VERSION ""

NS_ :

BS_:

BU_: ECS Dummy CGW MFC SPAS ESC BSD SCC SAS MDPS HUD CLU

BO_ 3221225472 VECTOR__INDEPENDENT_SIG_MSG: 0 Vector__XXX
 SG_ SNI_MDPS : 0|8@1+ (1,0) [0|0] "" Vector__XXX
 SG_ SNI_ECS : 0|8@1+ (1,0) [0|0] "" Vector__XXX
 SG_ CBV_RMR_MDPS : 0|1@1+ (1,0) [0|0] "" Vector__XXX
 SG_ CBV_RMR_ECS : 0|1@1+ (1,0) [0|0] "" Vector__XXX
 SG_ CBV_PNIB_MDPS : 0|1@1+ (1,0) [0|0] "" Vector__XXX
 SG_ CBV_PNIB_ECS : 0|1@1+ (1,0) [0|0] "" Vector__XXX
 SG_ CBV_NMCoSRB_MDPS : 0|1@1+ (1,0) [0|0] "" Vector__XXX
 SG_ CBV_NMCoSRB_ECS : 0|1@1+ (1,0) [0|0] "" Vector__XXX
 SG_ CBV_NMCoID_MDPS : 0|2@1+ (1,0) [0|0] "" Vector__XXX
 SG_ CBV_NMCoID_ECS : 0|2@1+ (1,0) [0|0] "" Vector__XXX
 SG_ CBV_AWB_MDPS : 0|1@1+ (1,0) [0|0] "" Vector__XXX
 SG_ CBV_AWB_ECS : 0|1@1+ (1,0) [0|0] "" Vector__XXX
 SG_ PNI_MDPS : 0|32@1+ (1,0) [0|0] "" Vector__XXX
 SG_ PNI_ECS : 0|32@1+ (1,0) [0|0] "" Vector__XXX
 SG_ NM_State_MDPS : 0|8@1+ (1,0) [0|0] "" Vector__XXX
 SG_ NM_State_ECS : 0|8@1+ (1,0) [0|0] "" Vector__XXX
 SG_ BSD_Crc1Val : 0|12@1+ (1,0) [0|0] "" Vector__XXX
 SG_ BSD_AlvCnt1Val : 0|4@1+ (1,0) [0|0] "" Vector__XXX
 SG_ BSD_Sta : 0|4@1+ (1,0) [0|0] "" Vector__XXX
 SG_ BSD_SndWarngSta : 0|2@1- (1,0) [0|0] "" Vector__XXX
 SG_ BSD_LftIndSta : 0|2@1+ (1,0) [0|0] "" Vector__XXX
 SG_ BSD_RtIndSta : 0|2@1+ (1,0) [0|0] "" Vector__XXX
 SG_ BSD_LftSndWrngSta : 0|2@1+ (1,0) [0|0] "" Vector__XXX
 SG_ BSD_RtSndWrngSta : 0|2@1+ (1,0) [0|0] "" Vector__XXX
 SG_ BSD_LftIndBriLvlSta : 0|8@1+ (1,0) [0|0] "" Vector__XXX
 SG_ BSD_RtIndBriLvlSta : 0|8@1+ (1,0) [0|0] "" Vector__XXX
 SG_ RCTA_Sta : 0|4@1+ (1,0) [0|0] "" Vector__XXX
 SG_ RCTA_LftIndSta : 0|2@1+ (1,0) [0|0] "" Vector__XXX
 SG_ RCTA_RtIndSta : 0|2@1+ (1,0) [0|0] "" Vector__XXX
 SG_ RCTA_LftSndWrngSta : 0|2@1+ (1,0) [0|0] "" Vector__XXX
 SG_ RCTA_RtSndWrngSta : 0|2@1+ (1,0) [0|0] "" Vector__XXX
 SG_ RCTA_LftWrngIndBriLvlSta : 0|8@1+ (1,0) [0|0] "" Vector__XXX
 SG_ RCTA_RtWrngIndBriLvlSta : 0|8@1+ (1,0) [0|0] "" Vector__XXX
 SG_ ABSD_Sta : 0|3@1+ (1,0) [0|0] "" Vector__XXX
 SG_ ABSD_WrngSta : 0|2@1+ (1,0) [0|0] "" Vector__XXX
 SG_ ABSD_FLBrkCtrlReq : 0|2@1+ (1,0) [0|0] "" Vector__XXX
 SG_ ABSD_FRBrkCtrlReq : 0|2@1+ (1,0) [0|0] "" Vector__XXX
 SG_ ABSD_RLBrkCtrlReq : 0|2@1+ (1,0) [0|0] "" Vector__XXX
 SG_ ABSD_RRBrkCtrlReq : 0|2@1+ (1,0) [0|0] "" Vector__XXX
 SG_ ABSD_FrWhlTrgtBrkPrsrVal : 0|6@1+ (1,0) [0|0] "Bar" Vector__XXX
 SG_ ABSD_RrWhlTrgtBrkPrsrVal : 0|6@1+ (1,0) [0|0] "Bar" Vector__XXX

BO_ 1892 CGW_SIG_GW_TOM_IF_03_B: 8 CGW
 SG_ SIG_GW_03_B_Sig2 : 32|32@1+ (1,0) [0|4294967295] ""  Dummy
 SG_ SIG_GW_03_B_Sig1 : 0|32@1+ (1,0) [0|4294967295] ""  Dummy

BO_ 1891 CGW_SIG_GW_Msg_IF_02_C: 8 CGW
 SG_ SIG_GW_02_C_Sig2 : 32|32@1+ (1,0) [0|4294967295] ""  Dummy
 SG_ SIG_GW_02_C_Sig1 : 0|32@1+ (1,0) [0|4294967295] ""  Dummy

BO_ 1890 CGW_SIG_GW_Msg_IF_02_B: 8 CGW
 SG_ SIG_GW_02_B_Sig2 : 32|32@1+ (1,0) [0|4294967295] ""  Dummy
 SG_ SIG_GW_02_B_Sig1 : 0|32@1+ (1,0) [0|4294967295] ""  Dummy

BO_ 1889 CGW_SIG_GW_Msg_IF_01_B: 8 CGW
 SG_ SIG_GW_01_B_Sig2 : 32|32@1+ (1,0) [0|4294967295] ""  Dummy
 SG_ SIG_GW_01_B_Sig1 : 0|32@1+ (1,0) [0|4294967295] ""  Dummy

BO_ 1888 Diag_Msg_TP_Phys_Res_FD_CAN1: 8 CGW
 SG_ TP_Phys_DiagRes_DATA_FD_CAN1 : 0|64@1+ (1,0) [0|0] ""  Dummy

BO_ 1896 Diag_Msg_TP_Phys_Req_FD_CAN1: 8 Dummy
 SG_ TP_Phys_DiagReq_DATA_FD_CAN1 : 0|64@1+ (1,0) [0|0] ""  CGW

BO_ 2015 Diag_Msg_TP_Func_FD_CAN1: 8 Dummy
 SG_ TP_Func_DiagReq_DATA_FD_CAN1 : 0|64@1+ (1,0) [0|0] ""  CGW

BO_ 263 V_CGW_07_B: 8 CGW
 SG_ V_CGW_07_B_SIG : 0|32@1+ (1,0) [0|0] ""  Dummy

BO_ 262 V_CGW_06_A: 8 Dummy
 SG_ V_CGW_06_A_SIG : 0|64@1+ (1,0) [0|0] ""  CGW

BO_ 290 V_CGW_05_C: 8 CGW
 SG_ V_CGW_05_C_SIG : 0|8@1- (1,0) [0|0] ""  Dummy

BO_ 517 V_CGW_02_A: 8 Dummy
 SG_ V_CGW_02_A_SIG : 0|64@1+ (1,0) [0|0] ""  CGW

BO_ 514 V_CGW_01_B: 8 CGW
 SG_ V_CGW_01_B_SigGrp_2 : 8|4@1+ (1,0) [0|15] ""  Dummy
 SG_ V_CGW_01_B_SigGrp_1 : 0|8@1+ (1,0) [0|244] ""  Dummy

BO_ 1761 XCP_Response: 20 CGW
 SG_ XCP_RESPONSE_DATA : 0|64@1+ (1,0) [0|1.84467440737096E+019] ""  SCC

BO_ 1762 XCP_Request: 20 SCC
 SG_ XCP_REQUEST_DATA : 0|64@1+ (1,0) [0|1.84467440737096E+019] ""  CGW

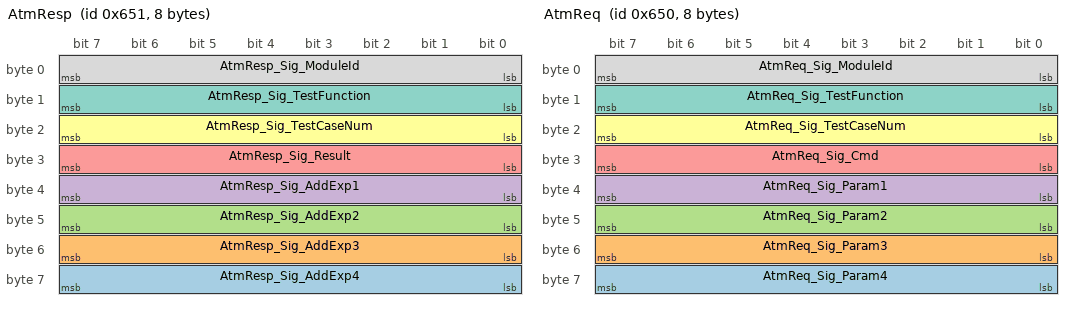
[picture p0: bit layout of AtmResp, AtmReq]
BO_ 1617 AtmResp: 8 CGW
 SG_ AtmResp_Sig_AddExp4 : 56|8@1+ (1,0) [0|0] ""  Dummy
 SG_ AtmResp_Sig_AddExp3 : 48|8@1+ (1,0) [0|0] ""  Dummy
 SG_ AtmResp_Sig_AddExp2 : 40|8@1+ (1,0) [0|0] ""  Dummy
 SG_ AtmResp_Sig_AddExp1 : 32|8@1+ (1,0) [0|0] ""  Dummy
 SG_ AtmResp_Sig_Result : 24|8@1+ (1,0) [0|0] ""  Dummy
 SG_ AtmResp_Sig_TestCaseNum : 16|8@1+ (1,0) [0|0] ""  Dummy
 SG_ AtmResp_Sig_TestFunction : 8|8@1+ (1,0) [0|0] ""  Dummy
 SG_ AtmResp_Sig_ModuleId : 0|8@1+ (1,0) [0|0] ""  Dummy

BO_ 1616 AtmReq: 8 Dummy
 SG_ AtmReq_Sig_Param4 : 56|8@1+ (1,0) [0|0] ""  CGW
 SG_ AtmReq_Sig_Param3 : 48|8@1+ (1,0) [0|0] ""  CGW
 SG_ AtmReq_Sig_Param2 : 40|8@1+ (1,0) [0|0] ""  CGW
 SG_ AtmReq_Sig_Param1 : 32|8@1+ (1,0) [0|0] ""  CGW
 SG_ AtmReq_Sig_Cmd : 24|8@1+ (1,0) [0|0] ""  CGW
 SG_ AtmReq_Sig_TestCaseNum : 16|8@1+ (1,0) [0|0] ""  CGW
 SG_ AtmReq_Sig_TestFunction : 8|8@1+ (1,0) [0|0] ""  CGW
 SG_ AtmReq_Sig_ModuleId : 0|8@1+ (1,0) [0|0] ""  CGW

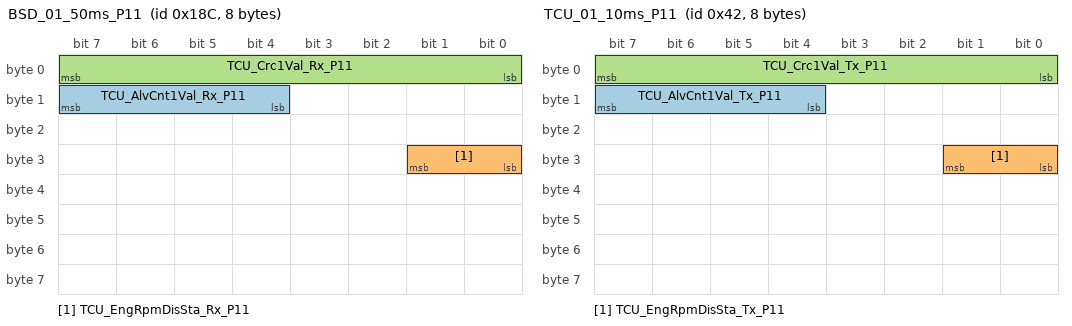
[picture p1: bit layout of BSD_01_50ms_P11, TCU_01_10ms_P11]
BO_ 396 BSD_01_50ms_P11: 8 CLU
 SG_ TCU_AlvCnt1Val_Rx_P11 : 12|4@1+ (1,0) [0|15] ""  CGW
 SG_ TCU_EngRpmDisSta_Rx_P11 : 24|2@1+ (1,0) [0|3] ""  CGW
 SG_ TCU_Crc1Val_Rx_P11 : 0|8@1+ (1,0) [0|255] ""  CGW

BO_ 66 TCU_01_10ms_P11: 8 CGW
 SG_ TCU_AlvCnt1Val_Tx_P11 : 12|4@1+ (1,0) [0|15] ""  CLU
 SG_ TCU_EngRpmDisSta_Tx_P11 : 24|2@1+ (1,0) [0|3] ""  CLU
 SG_ TCU_Crc1Val_Tx_P11 : 0|8@1+ (1,0) [0|255] ""  CLU

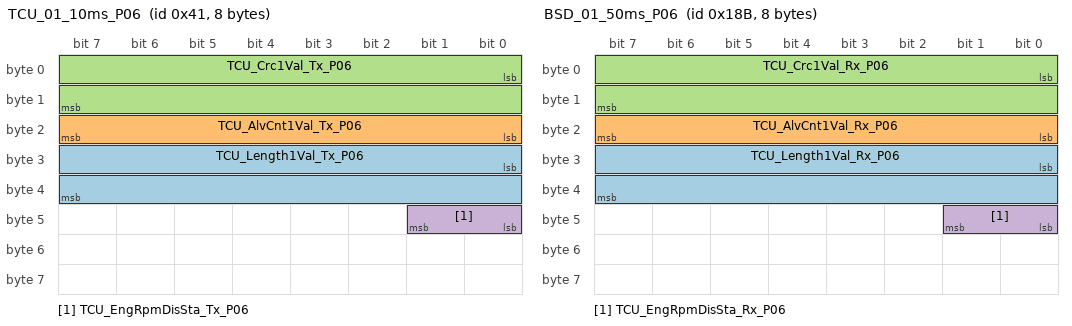
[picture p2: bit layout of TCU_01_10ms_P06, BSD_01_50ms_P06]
BO_ 65 TCU_01_10ms_P06: 8 CGW
 SG_ TCU_Length1Val_Tx_P06 : 24|16@1+ (1,0) [0|65535] "" Vector__XXX
 SG_ TCU_AlvCnt1Val_Tx_P06 : 16|8@1+ (1,0) [0|255] ""  CLU
 SG_ TCU_Crc1Val_Tx_P06 : 0|16@1+ (1,0) [0|65535] ""  CLU
 SG_ TCU_EngRpmDisSta_Tx_P06 : 40|2@1+ (1,0) [0|3] ""  CLU

BO_ 395 BSD_01_50ms_P06: 8 CLU
 SG_ TCU_Length1Val_Rx_P06 : 24|16@1+ (1,0) [0|65535] "" Vector__XXX
 SG_ TCU_AlvCnt1Val_Rx_P06 : 16|8@1+ (1,0) [0|255] ""  CGW
 SG_ TCU_Crc1Val_Rx_P06 : 0|16@1+ (1,0) [0|65535] ""  CGW
 SG_ TCU_EngRpmDisSta_Rx_P06 : 40|2@1+ (1,0) [0|3] ""  CGW

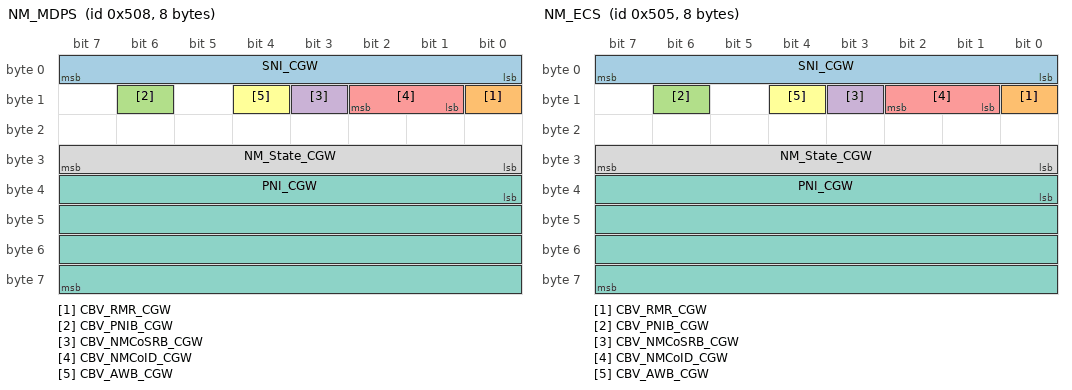
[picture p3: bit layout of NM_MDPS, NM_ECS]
BO_ 1288 NM_MDPS: 8 MDPS
 SG_ SNI_CGW : 0|8@1+ (1,0) [0|0] ""  CGW,ECS
 SG_ CBV_RMR_CGW : 8|1@1+ (1,0) [0|0] ""  CGW,ECS
 SG_ CBV_PNIB_CGW : 14|1@1+ (1,0) [0|0] ""  CGW,ECS
 SG_ CBV_NMCoSRB_CGW : 11|1@1+ (1,0) [0|0] ""  CGW,ECS
 SG_ CBV_NMCoID_CGW : 9|2@1+ (1,0) [0|0] ""  CGW,ECS
 SG_ CBV_AWB_CGW : 12|1@1+ (1,0) [0|0] ""  CGW,ECS
 SG_ PNI_CGW : 32|32@1+ (1,0) [0|0] ""  CGW,ECS
 SG_ NM_State_CGW : 24|8@1+ (1,0) [0|0] ""  CGW,ECS

BO_ 1285 NM_ECS: 8 ECS
 SG_ SNI_CGW : 0|8@1+ (1,0) [0|0] ""  CGW,MDPS
 SG_ CBV_RMR_CGW : 8|1@1+ (1,0) [0|0] ""  CGW,MDPS
 SG_ CBV_PNIB_CGW : 14|1@1+ (1,0) [0|0] ""  CGW,MDPS
 SG_ CBV_NMCoSRB_CGW : 11|1@1+ (1,0) [0|0] ""  CGW,MDPS
 SG_ CBV_NMCoID_CGW : 9|2@1+ (1,0) [0|0] ""  CGW,MDPS
 SG_ CBV_AWB_CGW : 12|1@1+ (1,0) [0|0] ""  CGW,MDPS
 SG_ PNI_CGW : 32|32@1+ (1,0) [0|0] ""  CGW,MDPS
 SG_ NM_State_CGW : 24|8@1+ (1,0) [0|0] ""  CGW,MDPS

BO_ 1886 Normal_Msg_FD_TP_01_B: 64 Dummy
 SG_ Normal_FD_TP_01_B_DATA_02 : 64|64@1+ (1,0) [0|0] ""  CGW
 SG_ Normal_FD_TP_01_B_DATA_01 : 0|64@1+ (1,0) [0|0] ""  CGW

BO_ 1882 Normal_Msg_FD_TP_01_A: 64 CGW
 SG_ Normal_FD_TP_01_A_DATA_02 : 64|64@1+ (1,0) [0|0] ""  Dummy
 SG_ Normal_FD_TP_01_A_DATA_01 : 0|64@1+ (1,0) [0|0] ""  Dummy

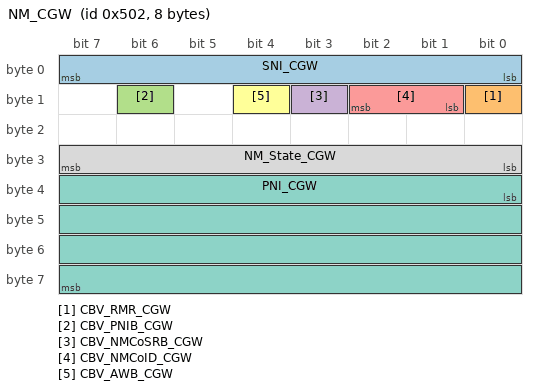
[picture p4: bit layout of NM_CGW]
BO_ 1282 NM_CGW: 8 CGW
 SG_ SNI_CGW : 0|8@1+ (1,0) [0|0] ""  MDPS,ECS
 SG_ CBV_RMR_CGW : 8|1@1+ (1,0) [0|0] ""  MDPS,ECS
 SG_ CBV_PNIB_CGW : 14|1@1+ (1,0) [0|0] ""  MDPS,ECS
 SG_ CBV_NMCoSRB_CGW : 11|1@1+ (1,0) [0|0] ""  MDPS,ECS
 SG_ CBV_NMCoID_CGW : 9|2@1+ (1,0) [0|0] ""  MDPS,ECS
 SG_ CBV_AWB_CGW : 12|1@1+ (1,0) [0|0] ""  MDPS,ECS
 SG_ PNI_CGW : 32|32@1+ (1,0) [0|0] ""  MDPS,ECS
 SG_ NM_State_CGW : 24|8@1+ (1,0) [0|0] ""  MDPS,ECS

BO_ 171 CGW_GW1_0xAB: 8 CGW
 SG_ CGW_GW1_TC00001_Signal1 : 0|64@1+ (1,0) [0|0] ""  Dummy

BO_ 464 ECS_01_100ms: 32 ECS
 SG_ ECS_Crc1Val : 0|12@1+ (1,0) [0|0] ""  Dummy,CGW
 SG_ ECS_AlvCnt1Val : 12|4@1+ (1,0) [0|0] ""  Dummy,CGW
 SG_ ECS_WrngLmpSta : 16|2@1+ (1,0) [0|0] ""  Dummy,CGW
 SG_ ECS_DfctvSta : 18|2@1+ (1,0) [0|0] ""  Dummy,CGW
 SG_ ECS_DiagSta : 20|2@1+ (1,0) [0|0] ""  Dummy,CGW
 SG_ ECS_DmpModSta : 22|3@1+ (1,0) [0|0] ""  Dummy,CGW
 SG_ ECS_DmpModReq : 25|3@1+ (1,0) [0|0] ""  Dummy,CGW
 SG_ ECS_SysUnblSta : 28|2@1+ (1,0) [0|0] ""  Dummy,CGW

BO_ 330 ECS_02_20ms: 64 ECS
 SG_ ECS_GroupSignal1 : 119|3@1+ (1,0) [0|7] "" Vector__XXX
 SG_ ECS_GroupSignal0 : 111|2@1+ (1,0) [0|3] "" Vector__XXX
 SG_ ECS_Crc2Val : 0|12@1+ (1,0) [0|0] ""  Dummy,CGW
 SG_ ECS_AlvCnt2Val : 12|4@1+ (1,0) [0|0] ""  Dummy,CGW
 SG_ ECS_ALS_FLHghtVal : 16|8@1- (1,-128) [-256|-1] "mm"  Dummy,CGW
 SG_ ECS_ALS_FRHghtVal : 24|17@1- (1,-128) [-65664|65407] "mm"  Dummy,CGW
 SG_ ECS_ALS_RLHghtVal : 41|40@1- (1,-128) [-549755814016|549755813759] "mm"  Dummy,CGW
 SG_ ECS_ALS_RRHghtVal : 81|8@1+ (1,-128) [-128|127] "mm"  Dummy,CGW
 SG_ ECS_ALS_HghtLvlChgUnblSta : 89|2@1+ (1,0) [0|0] ""  Dummy,CGW
 SG_ ECS_ALS_LvlOffSta : 91|2@1+ (1,0) [0|0] ""  Dummy,CGW
 SG_ ECS_ALS_LvlCtrlUnblOvhtSta : 93|2@1+ (1,0) [0|0] ""  Dummy,CGW
 SG_ ECS_ALS_LftngSta : 95|2@1+ (1,0) [0|0] ""  Dummy,CGW
 SG_ ECS_ALS_LwrngSta : 97|2@1+ (1,0) [0|0] ""  Dummy,CGW
 SG_ ECS_ALS_HghtReq : 100|3@1+ (1,0) [0|0] ""  Dummy,CGW
 SG_ ECS_ALS_LvlReq : 103|4@1+ (1,0) [0|0] ""  Dummy,CGW
 SG_ ECS_ALS_ActlHghtSta : 107|4@1+ (1,0) [0|0] ""  Dummy,CGW
 SG_ ECS_ALS_SysUnblSta : 496|2@1+ (1,0) [0|0] ""  Dummy,CGW

BO_ 122 ECS_03_10ms: 32 ECS
 SG_ ECS_Crc3Val : 0|12@1+ (1,0) [0|0] ""  Dummy
 SG_ ECS_AlvCnt3Val : 12|4@1+ (1,0) [0|0] ""  Dummy
 SG_ ECSIVSS_FLNmlCurrentVal : 16|8@1+ (0.5,0) [0|0] "%"  Dummy
 SG_ ECSIVSS_FRNmlCurrentVal : 24|8@1+ (0.5,0) [0|0] "%"  Dummy
 SG_ ECSIVSS_RLNmlCurrentVal : 32|8@1+ (0.5,0) [0|0] "%"  Dummy
 SG_ ECSIVSS_RRNmlCurrentVal : 40|8@1+ (0.5,0) [0|0] "%"  Dummy
 SG_ ECSIVSS_FLEstDmpVelVal : 48|12@1+ (1,1024) [0|0] "mm/s"  Dummy

CM_ BO_ 3221225472 "This is a message for not used signals, created by Vector CANdb++ DBC OLE DB Provider.";
CM_ SG_ 1761 XCP_RESPONSE_DATA "XCP response";
CM_ SG_ 1762 XCP_REQUEST_DATA "Xcp: FD request signal. Using for testing purpose";
BA_DEF_  "NmBaseAddress" HEX 0 2047;
BA_DEF_  "NmAsrWaitBusSleepTime" INT 0 100000;
BA_DEF_  "NmAsrTimeoutTime" INT 0 100000;
BA_DEF_  "NmAsrRepeatMessageTime" INT 0 100000;
BA_DEF_ BU_  "NmAsrNodeIdentifier" HEX 0 255;
BA_DEF_  "NmAsrMessageCount" INT 1 128;
BA_DEF_ BO_  "NmAsrMessage" ENUM  "No","Yes";
BA_DEF_ BU_  "NmAsrCanMsgReducedTime" INT 0 1000;
BA_DEF_  "NmAsrCanMsgCycleTime" INT 0 100;
BA_DEF_  "BusType" STRING ;
BA_DEF_  "DBName" STRING ;
BA_DEF_  "Baudrate" INT 50000 1000000;
BA_DEF_  "BRS" INT 0 1;
BA_DEF_  "GenEnvVarEndingDsp" STRING ;
BA_DEF_  "GenEnvVarEndingSnd" STRING ;
BA_DEF_  "GenEnvVarPrefix" STRING ;
BA_DEF_  "GenNWMApBusSleep" STRING ;
BA_DEF_  "GenNWMApCanNormal" STRING ;
BA_DEF_  "GenNWMApCanOff" STRING ;
BA_DEF_  "GenNWMApCanOn" STRING ;
BA_DEF_  "GenNWMApCanSleep" STRING ;
BA_DEF_  "GenNWMApCanWakeUp" STRING ;
BA_DEF_  "GenNWMGotoMode_Awake" STRING ;
BA_DEF_  "GenNWMGotoMode_BusSleep" STRING ;
BA_DEF_  "GenNWMSleepTime" INT 1375 1650;
BA_DEF_  "GenNWMTalkNM" STRING ;
BA_DEF_  "Manufacturer" STRING ;
BA_DEF_  "NmAsrBaseAddress" HEX 0 536870911;
BA_DEF_  "NmMessageCount" INT 0 128;
BA_DEF_  "NmType" STRING ;
BA_DEF_  "SamplePointMax" INT 50 85;
BA_DEF_  "SamplePointMin" INT 55 85;
BA_DEF_  "SyncJumpWidthMax" INT 1 8;
BA_DEF_  "SyncJumpWidthMin" INT 1 4;
BA_DEF_  "VersionDay" INT 1 31;
BA_DEF_  "VersionMonth" INT 1 12;
BA_DEF_  "VersionWeek" INT 1 53;
BA_DEF_ BU_  "NmStationAddress" HEX 0 127;
BA_DEF_ BU_  "NmNode" ENUM  "No","Yes";
BA_DEF_ BU_  "GenNodSleepTime" INT 1375 1650;
BA_DEF_ BU_  "ILUsed" ENUM  "No","Yes";
BA_DEF_ BU_  "NmCAN" INT 1 2;
BA_DEF_ BU_  "NodeLayerModules" STRING ;
BA_DEF_ BU_  "NWM_Knoten" ENUM  "No","Yes";
BA_DEF_ BO_  "GenMsgCycleTime" INT 0 2000;
BA_DEF_ BO_  "GenMsgSendType" ENUM  "Cyclic","NoMsgSendType";
BA_DEF_ BO_  "GenMsgCycleTimeFast" INT 0 500;
BA_DEF_ BO_  "GenMsgDelayTime" INT 0 20;
BA_DEF_ BO_  "GenMsgILSupport" ENUM  "No","Yes";
BA_DEF_ BO_  "GenMsgNrOfRepetition" INT 0 3;
BA_DEF_ BO_  "VFrameFormat" ENUM  "StandardCAN","ExtendedCAN","reserved","reserved","reserved","reserved","reserved","reserved","reserved","reserved","reserved","reserved","reserved","reserved","StandardCAN_FD","ExtendedCAN_FD";
BA_DEF_ SG_  "SignalLongName" STRING ;
BA_DEF_ SG_  "UserSigValidity" ENUM  "B+","ACC","IG","IG1","IG2","IG3","IG1 or IG2","IG1 or IG3","Undef";
BA_DEF_ SG_  "GenSigTimeoutTime" INT 0 7000;
BA_DEF_ SG_  "UsrSigTimeoutValue" STRING ;
BA_DEF_ SG_  "UsrSigPurpose" ENUM  "Undef","FN","DIAG","DEV","NM";
BA_DEF_ SG_  "GenSigStartValue" INT 0 1215752192;
BA_DEF_ SG_  "NetworkRequest" ENUM  "Yes","No";
BA_DEF_ SG_  "NetworkRequestHoldingTime" INT 0 65535;
BA_DEF_ SG_  "Description" STRING ;
BA_DEF_ SG_  "Version" STRING ;
BA_DEF_ SG_  "GenSigEnvVarType" ENUM  "Int","Float","Undef";
BA_DEF_ SG_  "GenSigSendType" ENUM  "OnChangeWithRepetition","OnWriteWithRepetition","NoSigSendType";
BA_DEF_ SG_  "GwSigLatencyTime" INT 0 65536;
BA_DEF_ SG_  "GwSigMissingSourceType" ENUM  "Undef","OldValue","DefaultValue","InitialValue";
BA_DEF_ SG_  "RoutingFactor" INT 1 1215752192;
BA_DEF_ SG_  "RoutingFactorMM" INT 1 1215752192;
BA_DEF_  "Datarate" INT 2000000 8000000;
BA_DEF_DEF_  "NmBaseAddress" 1280;
BA_DEF_DEF_  "NmAsrWaitBusSleepTime" 1500;
BA_DEF_DEF_  "NmAsrTimeoutTime" 1000;
BA_DEF_DEF_  "NmAsrRepeatMessageTime" 1200;
BA_DEF_DEF_  "NmAsrNodeIdentifier" 0;
BA_DEF_DEF_  "NmAsrMessageCount" 128;
BA_DEF_DEF_  "NmAsrMessage" "No";
BA_DEF_DEF_  "NmAsrCanMsgReducedTime" 1000;
BA_DEF_DEF_  "NmAsrCanMsgCycleTime" 100;
BA_DEF_DEF_  "BusType" "CAN FD";
BA_DEF_DEF_  "DBName" "";
BA_DEF_DEF_  "Baudrate" 500000;
BA_DEF_DEF_  "BRS" 1;
BA_DEF_DEF_  "GenEnvVarEndingDsp" "Dsp_";
BA_DEF_DEF_  "GenEnvVarEndingSnd" "_";
BA_DEF_DEF_  "GenEnvVarPrefix" "Env";
BA_DEF_DEF_  "GenNWMApBusSleep" "AppNmCanBusSleep()";
BA_DEF_DEF_  "GenNWMApCanNormal" "AppNmCanNormal()";
BA_DEF_DEF_  "GenNWMApCanOff" "ApplCanOffline()";
BA_DEF_DEF_  "GenNWMApCanOn" "ApplCanOnline()";
BA_DEF_DEF_  "GenNWMApCanSleep" "ApplNmCanSleep()";
BA_DEF_DEF_  "GenNWMApCanWakeUp" "ApplCanWakeUp()";
BA_DEF_DEF_  "GenNWMGotoMode_Awake" "GotoMode_Awake()";
BA_DEF_DEF_  "GenNWMGotoMode_BusSleep" "GotoMode_BusSleep()";
BA_DEF_DEF_  "GenNWMSleepTime" 1500;
BA_DEF_DEF_  "GenNWMTalkNM" "TalkNM()";
BA_DEF_DEF_  "Manufacturer" "HMC";
BA_DEF_DEF_  "NmAsrBaseAddress" 1280;
BA_DEF_DEF_  "NmMessageCount" 0;
BA_DEF_DEF_  "NmType" "AsrNm";
BA_DEF_DEF_  "SamplePointMax" 80;
BA_DEF_DEF_  "SamplePointMin" 80;
BA_DEF_DEF_  "SyncJumpWidthMax" 3;
BA_DEF_DEF_  "SyncJumpWidthMin" 2;
BA_DEF_DEF_  "VersionDay" 1;
BA_DEF_DEF_  "VersionMonth" 1;
BA_DEF_DEF_  "VersionWeek" 1;
BA_DEF_DEF_  "NmStationAddress" 0;
BA_DEF_DEF_  "NmNode" "Yes";
BA_DEF_DEF_  "GenNodSleepTime" 1500;
BA_DEF_DEF_  "ILUsed" "Yes";
BA_DEF_DEF_  "NmCAN" 1;
BA_DEF_DEF_  "NodeLayerModules" "AsrNM33.DLL,CANoeILNLVector.DLL";
BA_DEF_DEF_  "NWM_Knoten" "Yes";
BA_DEF_DEF_  "GenMsgCycleTime" 200;
BA_DEF_DEF_  "GenMsgSendType" "NoMsgSendType";
BA_DEF_DEF_  "GenMsgCycleTimeFast" 40;
BA_DEF_DEF_  "GenMsgDelayTime" 20;
BA_DEF_DEF_  "GenMsgILSupport" "Yes";
BA_DEF_DEF_  "GenMsgNrOfRepetition" 3;
BA_DEF_DEF_  "VFrameFormat" "StandardCAN";
BA_DEF_DEF_  "SignalLongName" "";
BA_DEF_DEF_  "UserSigValidity" "IG";
BA_DEF_DEF_  "GenSigTimeoutTime" 500;
BA_DEF_DEF_  "UsrSigTimeoutValue" "Undef";
BA_DEF_DEF_  "UsrSigPurpose" "FN";
BA_DEF_DEF_  "GenSigStartValue" 0;
BA_DEF_DEF_  "NetworkRequest" "No";
BA_DEF_DEF_  "NetworkRequestHoldingTime" 5.03070881554866E-316;
BA_DEF_DEF_  "Description" "";
BA_DEF_DEF_  "Version" "";
BA_DEF_DEF_  "GenSigEnvVarType" "Undef";
BA_DEF_DEF_  "GenSigSendType" "NoSigSendType";
BA_DEF_DEF_  "GwSigLatencyTime" 40;
BA_DEF_DEF_  "GwSigMissingSourceType" "Undef";
BA_DEF_DEF_  "RoutingFactor" 1;
BA_DEF_DEF_  "RoutingFactorMM" 1;
BA_DEF_DEF_  "Datarate" 2000000;
BA_ "NmMessageCount" 128;
BA_ "DBName" "FD_CAN1";
BA_ "NmStationAddress" BU_ ECS 5;
BA_ "NmAsrNodeIdentifier" BU_ ECS 5;
BA_ "NWM_Knoten" BU_ Dummy 0;
BA_ "NmNode" BU_ Dummy 0;
BA_ "NmStationAddress" BU_ Dummy 4;
BA_ "NmStationAddress" BU_ CGW 2;
BA_ "NmAsrNodeIdentifier" BU_ CGW 2;
BA_ "NWM_Knoten" BU_ MFC 0;
BA_ "NmNode" BU_ MFC 0;
BA_ "NmStationAddress" BU_ MFC 9;
BA_ "NWM_Knoten" BU_ SPAS 0;
BA_ "NmNode" BU_ SPAS 0;
BA_ "NmStationAddress" BU_ SPAS 12;
BA_ "NWM_Knoten" BU_ ESC 0;
BA_ "NmNode" BU_ ESC 0;
BA_ "NmStationAddress" BU_ ESC 6;
BA_ "NWM_Knoten" BU_ BSD 0;
BA_ "NmNode" BU_ BSD 0;
BA_ "NmStationAddress" BU_ BSD 1;
BA_ "NWM_Knoten" BU_ SCC 0;
BA_ "NmNode" BU_ SCC 0;
BA_ "NmStationAddress" BU_ SCC 11;
BA_ "NWM_Knoten" BU_ SAS 0;
BA_ "NmNode" BU_ SAS 0;
BA_ "NmStationAddress" BU_ SAS 10;
BA_ "NmStationAddress" BU_ MDPS 8;
BA_ "NmAsrNodeIdentifier" BU_ MDPS 8;
BA_ "NWM_Knoten" BU_ HUD 0;
BA_ "NmNode" BU_ HUD 0;
BA_ "NmStationAddress" BU_ HUD 7;
BA_ "NWM_Knoten" BU_ CLU 0;
BA_ "NmNode" BU_ CLU 0;
BA_ "NmStationAddress" BU_ CLU 3;
BA_ "GenMsgCycleTime" BO_ 1888 0;
BA_ "GenMsgDelayTime" BO_ 1888 0;
BA_ "VFrameFormat" BO_ 1888 14;
BA_ "GenMsgCycleTime" BO_ 1896 0;
BA_ "GenMsgDelayTime" BO_ 1896 0;
BA_ "VFrameFormat" BO_ 1896 14;
BA_ "VFrameFormat" BO_ 2015 14;
BA_ "VFrameFormat" BO_ 263 14;
BA_ "VFrameFormat" BO_ 262 14;
BA_ "VFrameFormat" BO_ 290 14;
BA_ "VFrameFormat" BO_ 517 14;
BA_ "VFrameFormat" BO_ 514 14;
BA_ "VFrameFormat" BO_ 1761 14;
BA_ "VFrameFormat" BO_ 1762 14;
BA_ "VFrameFormat" BO_ 1617 14;
BA_ "VFrameFormat" BO_ 1616 14;
BA_ "GenMsgCycleTime" BO_ 396 50;
BA_ "GenMsgSendType" BO_ 396 0;
BA_ "VFrameFormat" BO_ 396 14;
BA_ "GenMsgCycleTime" BO_ 66 10;
BA_ "GenMsgSendType" BO_ 66 0;
BA_ "VFrameFormat" BO_ 66 14;
BA_ "GenMsgSendType" BO_ 65 0;
BA_ "GenMsgCycleTime" BO_ 65 10;
BA_ "VFrameFormat" BO_ 65 14;
BA_ "GenMsgSendType" BO_ 395 0;
BA_ "GenMsgCycleTime" BO_ 395 50;
BA_ "VFrameFormat" BO_ 395 14;
BA_ "GenMsgCycleTime" BO_ 1288 100;
BA_ "GenMsgCycleTimeFast" BO_ 1288 0;
BA_ "GenMsgDelayTime" BO_ 1288 10;
BA_ "GenMsgILSupport" BO_ 1288 0;
BA_ "GenMsgNrOfRepetition" BO_ 1288 0;
BA_ "NmAsrMessage" BO_ 1288 1;
BA_ "VFrameFormat" BO_ 1288 14;
BA_ "GenMsgCycleTime" BO_ 1285 100;
BA_ "GenMsgCycleTimeFast" BO_ 1285 0;
BA_ "GenMsgDelayTime" BO_ 1285 10;
BA_ "GenMsgILSupport" BO_ 1285 0;
BA_ "GenMsgNrOfRepetition" BO_ 1285 0;
BA_ "NmAsrMessage" BO_ 1285 1;
BA_ "VFrameFormat" BO_ 1285 14;
BA_ "VFrameFormat" BO_ 1886 14;
BA_ "VFrameFormat" BO_ 1882 14;
BA_ "GenMsgCycleTime" BO_ 1282 100;
BA_ "GenMsgCycleTimeFast" BO_ 1282 0;
BA_ "GenMsgDelayTime" BO_ 1282 10;
BA_ "GenMsgILSupport" BO_ 1282 0;
BA_ "GenMsgNrOfRepetition" BO_ 1282 0;
BA_ "NmAsrMessage" BO_ 1282 1;
BA_ "VFrameFormat" BO_ 1282 14;
BA_ "VFrameFormat" BO_ 171 14;
BA_ "GenMsgSendType" BO_ 464 0;
BA_ "GenMsgCycleTime" BO_ 464 100;
BA_ "VFrameFormat" BO_ 464 14;
BA_ "GenMsgSendType" BO_ 330 0;
BA_ "GenMsgCycleTime" BO_ 330 20;
BA_ "VFrameFormat" BO_ 330 14;
BA_ "GenMsgSendType" BO_ 122 0;
BA_ "GenMsgCycleTime" BO_ 122 10;
BA_ "VFrameFormat" BO_ 122 14;
BA_ "UserSigValidity" SG_ 3221225472 SNI_MDPS 0;
BA_ "GenSigTimeoutTime" SG_ 3221225472 SNI_MDPS 0;
BA_ "UsrSigPurpose" SG_ 3221225472 SNI_MDPS 4;
BA_ "NetworkRequest" SG_ 3221225472 SNI_MDPS 0;
BA_ "NetworkRequestHoldingTime" SG_ 3221225472 SNI_MDPS 5000;
BA_ "UserSigValidity" SG_ 3221225472 SNI_ECS 0;
BA_ "GenSigTimeoutTime" SG_ 3221225472 SNI_ECS 0;
BA_ "UsrSigPurpose" SG_ 3221225472 SNI_ECS 4;
BA_ "NetworkRequest" SG_ 3221225472 SNI_ECS 0;
BA_ "NetworkRequestHoldingTime" SG_ 3221225472 SNI_ECS 5000;
BA_ "UserSigValidity" SG_ 3221225472 CBV_RMR_MDPS 0;
BA_ "GenSigTimeoutTime" SG_ 3221225472 CBV_RMR_MDPS 0;
BA_ "UsrSigPurpose" SG_ 3221225472 CBV_RMR_MDPS 4;
BA_ "NetworkRequest" SG_ 3221225472 CBV_RMR_MDPS 0;
BA_ "NetworkRequestHoldingTime" SG_ 3221225472 CBV_RMR_MDPS 5000;
BA_ "UserSigValidity" SG_ 3221225472 CBV_RMR_ECS 0;
BA_ "GenSigTimeoutTime" SG_ 3221225472 CBV_RMR_ECS 0;
BA_ "UsrSigPurpose" SG_ 3221225472 CBV_RMR_ECS 4;
BA_ "NetworkRequest" SG_ 3221225472 CBV_RMR_ECS 0;
BA_ "NetworkRequestHoldingTime" SG_ 3221225472 CBV_RMR_ECS 5000;
BA_ "UserSigValidity" SG_ 3221225472 CBV_PNIB_MDPS 0;
BA_ "GenSigTimeoutTime" SG_ 3221225472 CBV_PNIB_MDPS 0;
BA_ "UsrSigPurpose" SG_ 3221225472 CBV_PNIB_MDPS 4;
BA_ "NetworkRequest" SG_ 3221225472 CBV_PNIB_MDPS 0;
BA_ "NetworkRequestHoldingTime" SG_ 3221225472 CBV_PNIB_MDPS 5000;
BA_ "UserSigValidity" SG_ 3221225472 CBV_PNIB_ECS 0;
BA_ "GenSigTimeoutTime" SG_ 3221225472 CBV_PNIB_ECS 0;
BA_ "UsrSigPurpose" SG_ 3221225472 CBV_PNIB_ECS 4;
BA_ "NetworkRequest" SG_ 3221225472 CBV_PNIB_ECS 0;
BA_ "NetworkRequestHoldingTime" SG_ 3221225472 CBV_PNIB_ECS 5000;
BA_ "UserSigValidity" SG_ 3221225472 CBV_NMCoSRB_MDPS 0;
BA_ "GenSigTimeoutTime" SG_ 3221225472 CBV_NMCoSRB_MDPS 0;
BA_ "UsrSigPurpose" SG_ 3221225472 CBV_NMCoSRB_MDPS 4;
BA_ "NetworkRequest" SG_ 3221225472 CBV_NMCoSRB_MDPS 0;
BA_ "NetworkRequestHoldingTime" SG_ 3221225472 CBV_NMCoSRB_MDPS 5000;
BA_ "UserSigValidity" SG_ 3221225472 CBV_NMCoSRB_ECS 0;
BA_ "GenSigTimeoutTime" SG_ 3221225472 CBV_NMCoSRB_ECS 0;
BA_ "UsrSigPurpose" SG_ 3221225472 CBV_NMCoSRB_ECS 4;
BA_ "NetworkRequest" SG_ 3221225472 CBV_NMCoSRB_ECS 0;
BA_ "NetworkRequestHoldingTime" SG_ 3221225472 CBV_NMCoSRB_ECS 5000;
BA_ "UserSigValidity" SG_ 3221225472 CBV_NMCoID_MDPS 0;
BA_ "GenSigTimeoutTime" SG_ 3221225472 CBV_NMCoID_MDPS 0;
BA_ "UsrSigPurpose" SG_ 3221225472 CBV_NMCoID_MDPS 4;
BA_ "NetworkRequest" SG_ 3221225472 CBV_NMCoID_MDPS 0;
BA_ "NetworkRequestHoldingTime" SG_ 3221225472 CBV_NMCoID_MDPS 5000;
BA_ "UserSigValidity" SG_ 3221225472 CBV_NMCoID_ECS 0;
BA_ "GenSigTimeoutTime" SG_ 3221225472 CBV_NMCoID_ECS 0;
BA_ "UsrSigPurpose" SG_ 3221225472 CBV_NMCoID_ECS 4;
BA_ "NetworkRequest" SG_ 3221225472 CBV_NMCoID_ECS 0;
BA_ "NetworkRequestHoldingTime" SG_ 3221225472 CBV_NMCoID_ECS 5000;
BA_ "UserSigValidity" SG_ 3221225472 CBV_AWB_MDPS 0;
BA_ "GenSigTimeoutTime" SG_ 3221225472 CBV_AWB_MDPS 0;
BA_ "UsrSigPurpose" SG_ 3221225472 CBV_AWB_MDPS 4;
BA_ "NetworkRequest" SG_ 3221225472 CBV_AWB_MDPS 0;
BA_ "NetworkRequestHoldingTime" SG_ 3221225472 CBV_AWB_MDPS 5000;
BA_ "UserSigValidity" SG_ 3221225472 CBV_AWB_ECS 0;
BA_ "GenSigTimeoutTime" SG_ 3221225472 CBV_AWB_ECS 0;
BA_ "UsrSigPurpose" SG_ 3221225472 CBV_AWB_ECS 4;
BA_ "NetworkRequest" SG_ 3221225472 CBV_AWB_ECS 0;
BA_ "NetworkRequestHoldingTime" SG_ 3221225472 CBV_AWB_ECS 5000;
BA_ "UserSigValidity" SG_ 3221225472 PNI_MDPS 0;
BA_ "GenSigTimeoutTime" SG_ 3221225472 PNI_MDPS 0;
BA_ "UsrSigPurpose" SG_ 3221225472 PNI_MDPS 4;
BA_ "NetworkRequest" SG_ 3221225472 PNI_MDPS 0;
BA_ "NetworkRequestHoldingTime" SG_ 3221225472 PNI_MDPS 5000;
BA_ "UserSigValidity" SG_ 3221225472 PNI_ECS 0;
BA_ "GenSigTimeoutTime" SG_ 3221225472 PNI_ECS 0;
BA_ "UsrSigPurpose" SG_ 3221225472 PNI_ECS 4;
BA_ "NetworkRequest" SG_ 3221225472 PNI_ECS 0;
BA_ "NetworkRequestHoldingTime" SG_ 3221225472 PNI_ECS 5000;
BA_ "UserSigValidity" SG_ 3221225472 NM_State_MDPS 0;
BA_ "GenSigTimeoutTime" SG_ 3221225472 NM_State_MDPS 0;
BA_ "UsrSigPurpose" SG_ 3221225472 NM_State_MDPS 4;
BA_ "NetworkRequest" SG_ 3221225472 NM_State_MDPS 0;
BA_ "NetworkRequestHoldingTime" SG_ 3221225472 NM_State_MDPS 5000;
BA_ "UserSigValidity" SG_ 3221225472 NM_State_ECS 0;
BA_ "GenSigTimeoutTime" SG_ 3221225472 NM_State_ECS 0;
BA_ "UsrSigPurpose" SG_ 3221225472 NM_State_ECS 4;
BA_ "NetworkRequest" SG_ 3221225472 NM_State_ECS 0;
BA_ "NetworkRequestHoldingTime" SG_ 3221225472 NM_State_ECS 5000;
BA_ "Version" SG_ 3221225472 BSD_Crc1Val "1.0";
BA_ "GenSigStartValue" SG_ 3221225472 BSD_Crc1Val 4095;
BA_ "UsrSigTimeoutValue" SG_ 3221225472 BSD_Crc1Val "";
BA_ "UserSigValidity" SG_ 3221225472 BSD_Crc1Val 3;
BA_ "SignalLongName" SG_ 3221225472 BSD_Crc1Val "BSD_Crc1Value";
BA_ "Version" SG_ 3221225472 BSD_AlvCnt1Val "1.0";
BA_ "Description" SG_ 3221225472 BSD_AlvCnt1Val "This signal indicates Alive Counter";
BA_ "UsrSigTimeoutValue" SG_ 3221225472 BSD_AlvCnt1Val "";
BA_ "UserSigValidity" SG_ 3221225472 BSD_AlvCnt1Val 3;
BA_ "SignalLongName" SG_ 3221225472 BSD_AlvCnt1Val "BSD_AliveCounter1Value";
BA_ "Version" SG_ 3221225472 BSD_Sta "1.0";
BA_ "Description" SG_ 3221225472 BSD_Sta "This signal indicates the status of LCA/BSD ECU";
BA_ "UsrSigTimeoutValue" SG_ 3221225472 BSD_Sta "";
BA_ "UserSigValidity" SG_ 3221225472 BSD_Sta 3;
BA_ "SignalLongName" SG_ 3221225472 BSD_Sta "BSD_Status";
BA_ "Version" SG_ 3221225472 BSD_SndWarngSta "1.0";
BA_ "Description" SG_ 3221225472 BSD_SndWarngSta "This signal indicates the selected mode of LCA/BSD sound output";
BA_ "UsrSigTimeoutValue" SG_ 3221225472 BSD_SndWarngSta "";
BA_ "UserSigValidity" SG_ 3221225472 BSD_SndWarngSta 3;
BA_ "SignalLongName" SG_ 3221225472 BSD_SndWarngSta "BSD_SoundWarningStatus";
BA_ "Version" SG_ 3221225472 BSD_LftIndSta "1.0";
BA_ "Description" SG_ 3221225472 BSD_LftIndSta "This signal Indicates LCA Warning Indicator mode for Left side";
BA_ "UsrSigTimeoutValue" SG_ 3221225472 BSD_LftIndSta "";
BA_ "UserSigValidity" SG_ 3221225472 BSD_LftIndSta 3;
BA_ "SignalLongName" SG_ 3221225472 BSD_LftIndSta "BSD_LeftIndicatorStatus";
BA_ "Version" SG_ 3221225472 BSD_RtIndSta "1.0";
BA_ "Description" SG_ 3221225472 BSD_RtIndSta "This signal Indicates LCA Warning Indicator mode for Right side";
BA_ "UsrSigTimeoutValue" SG_ 3221225472 BSD_RtIndSta "";
BA_ "UserSigValidity" SG_ 3221225472 BSD_RtIndSta 3;
BA_ "SignalLongName" SG_ 3221225472 BSD_RtIndSta "BSD_RightIndicatorStatus";
BA_ "Version" SG_ 3221225472 BSD_LftSndWrngSta "1.0";
BA_ "Description" SG_ 3221225472 BSD_LftSndWrngSta "This signal indicates BSD Sound Warning for Front Left Speaker";
BA_ "UsrSigTimeoutValue" SG_ 3221225472 BSD_LftSndWrngSta "";
BA_ "UserSigValidity" SG_ 3221225472 BSD_LftSndWrngSta 3;
BA_ "SignalLongName" SG_ 3221225472 BSD_LftSndWrngSta "BSD_LeftSoundWarningStatus";
BA_ "Version" SG_ 3221225472 BSD_RtSndWrngSta "1.0";
BA_ "Description" SG_ 3221225472 BSD_RtSndWrngSta "This signal indicates BSD Sound Warning for Front Right Speaker";
BA_ "UsrSigTimeoutValue" SG_ 3221225472 BSD_RtSndWrngSta "";
BA_ "UserSigValidity" SG_ 3221225472 BSD_RtSndWrngSta 3;
BA_ "SignalLongName" SG_ 3221225472 BSD_RtSndWrngSta "BSD_RightSoundWarningStatus";
BA_ "Version" SG_ 3221225472 BSD_LftIndBriLvlSta "1.0";
BA_ "Description" SG_ 3221225472 BSD_LftIndBriLvlSta "0x00~FF : Indicator Brightness level of BSD/LCA";
BA_ "UsrSigTimeoutValue" SG_ 3221225472 BSD_LftIndBriLvlSta "";
BA_ "UserSigValidity" SG_ 3221225472 BSD_LftIndBriLvlSta 3;
BA_ "SignalLongName" SG_ 3221225472 BSD_LftIndBriLvlSta "BSD_LeftIndicatorBrightnessLevelStatus";
BA_ "Version" SG_ 3221225472 BSD_RtIndBriLvlSta "1.0";
BA_ "Description" SG_ 3221225472 BSD_RtIndBriLvlSta "0x00~FF : Indicator Brightness level of BSD/LCA";
BA_ "UsrSigTimeoutValue" SG_ 3221225472 BSD_RtIndBriLvlSta "";
BA_ "UserSigValidity" SG_ 3221225472 BSD_RtIndBriLvlSta 3;
BA_ "SignalLongName" SG_ 3221225472 BSD_RtIndBriLvlSta "BSD_RightIndicatorBrightnessLevelStatus";
BA_ "Version" SG_ 3221225472 RCTA_Sta "1.0";
BA_ "Description" SG_ 3221225472 RCTA_Sta "This signal indicates the Status of RCTA";
BA_ "UsrSigTimeoutValue" SG_ 3221225472 RCTA_Sta "";
BA_ "UserSigValidity" SG_ 3221225472 RCTA_Sta 3;
BA_ "SignalLongName" SG_ 3221225472 RCTA_Sta "RCTA_Status";
BA_ "Version" SG_ 3221225472 RCTA_LftIndSta "1.0";
BA_ "Description" SG_ 3221225472 RCTA_LftIndSta "This signal Indicates RCTA Warning Indicator mode for Left side";
BA_ "UsrSigTimeoutValue" SG_ 3221225472 RCTA_LftIndSta "";
BA_ "UserSigValidity" SG_ 3221225472 RCTA_LftIndSta 3;
BA_ "SignalLongName" SG_ 3221225472 RCTA_LftIndSta "RCTA_LeftIndicatorStatus";
BA_ "Version" SG_ 3221225472 RCTA_RtIndSta "1.0";
BA_ "Description" SG_ 3221225472 RCTA_RtIndSta "This signal Indicates RCTA Warning Indicator mode for Right side";
BA_ "UsrSigTimeoutValue" SG_ 3221225472 RCTA_RtIndSta "";
BA_ "UserSigValidity" SG_ 3221225472 RCTA_RtIndSta 3;
BA_ "SignalLongName" SG_ 3221225472 RCTA_RtIndSta "RCTA_RightIndicatorStatus";
BA_ "Version" SG_ 3221225472 RCTA_LftSndWrngSta "1.0";
BA_ "Description" SG_ 3221225472 RCTA_LftSndWrngSta "This signal indicates RCTA Sound Warning for Rear Left Speaker";
BA_ "UsrSigTimeoutValue" SG_ 3221225472 RCTA_LftSndWrngSta "";
BA_ "UserSigValidity" SG_ 3221225472 RCTA_LftSndWrngSta 3;
BA_ "SignalLongName" SG_ 3221225472 RCTA_LftSndWrngSta "RCTA_LeftSoundWarningStatus";
BA_ "Version" SG_ 3221225472 RCTA_RtSndWrngSta "1.0";
BA_ "Description" SG_ 3221225472 RCTA_RtSndWrngSta "This signal indicates RCTA Sound Warning for Rear Right Speaker";
BA_ "UsrSigTimeoutValue" SG_ 3221225472 RCTA_RtSndWrngSta "";
BA_ "UserSigValidity" SG_ 3221225472 RCTA_RtSndWrngSta 3;
BA_ "SignalLongName" SG_ 3221225472 RCTA_RtSndWrngSta "RCTA_RightSoundWarningStatus";
BA_ "Version" SG_ 3221225472 RCTA_LftWrngIndBriLvlSta "1.0";
BA_ "Description" SG_ 3221225472 RCTA_LftWrngIndBriLvlSta "This signal indicator Brightness level of RCTA";
BA_ "UsrSigTimeoutValue" SG_ 3221225472 RCTA_LftWrngIndBriLvlSta "";
BA_ "UserSigValidity" SG_ 3221225472 RCTA_LftWrngIndBriLvlSta 3;
BA_ "SignalLongName" SG_ 3221225472 RCTA_LftWrngIndBriLvlSta "RCTA_LeftWarningIndicatorBrightnessLevelStatus";
BA_ "Version" SG_ 3221225472 RCTA_RtWrngIndBriLvlSta "1.0";
BA_ "Description" SG_ 3221225472 RCTA_RtWrngIndBriLvlSta "This signal indicator Brightness level of RCTA";
BA_ "UsrSigTimeoutValue" SG_ 3221225472 RCTA_RtWrngIndBriLvlSta "";
BA_ "UserSigValidity" SG_ 3221225472 RCTA_RtWrngIndBriLvlSta 3;
BA_ "SignalLongName" SG_ 3221225472 RCTA_RtWrngIndBriLvlSta "RCTA_RightWarningIndicatorBrightnessLevelStatus";
BA_ "Version" SG_ 3221225472 ABSD_Sta "1.0";
BA_ "Description" SG_ 3221225472 ABSD_Sta "This signal indicates the status of ABSD";
BA_ "UsrSigTimeoutValue" SG_ 3221225472 ABSD_Sta "";
BA_ "UserSigValidity" SG_ 3221225472 ABSD_Sta 3;
BA_ "SignalLongName" SG_ 3221225472 ABSD_Sta "ABSD_Status";
BA_ "Version" SG_ 3221225472 ABSD_WrngSta "1.0";
BA_ "Description" SG_ 3221225472 ABSD_WrngSta "This signal indicates the warning of ABSD";
BA_ "UsrSigTimeoutValue" SG_ 3221225472 ABSD_WrngSta "";
BA_ "UserSigValidity" SG_ 3221225472 ABSD_WrngSta 3;
BA_ "SignalLongName" SG_ 3221225472 ABSD_WrngSta "ABSD_WarningStatus";
BA_ "Version" SG_ 3221225472 ABSD_FLBrkCtrlReq "1.0";
BA_ "Description" SG_ 3221225472 ABSD_FLBrkCtrlReq "This signal inform ESC whether to control FL wheel or not";
BA_ "UsrSigTimeoutValue" SG_ 3221225472 ABSD_FLBrkCtrlReq "";
BA_ "UserSigValidity" SG_ 3221225472 ABSD_FLBrkCtrlReq 3;
BA_ "SignalLongName" SG_ 3221225472 ABSD_FLBrkCtrlReq "ABSD_FrontLeftBrakeControlRequest";
BA_ "Version" SG_ 3221225472 ABSD_FRBrkCtrlReq "1.0";
BA_ "Description" SG_ 3221225472 ABSD_FRBrkCtrlReq "This signal inform ESC whether to control FR wheel or not";
BA_ "UsrSigTimeoutValue" SG_ 3221225472 ABSD_FRBrkCtrlReq "";
BA_ "UserSigValidity" SG_ 3221225472 ABSD_FRBrkCtrlReq 3;
BA_ "SignalLongName" SG_ 3221225472 ABSD_FRBrkCtrlReq "ABSD_FrontRightBrakeControlRequest";
BA_ "Version" SG_ 3221225472 ABSD_RLBrkCtrlReq "1.0";
BA_ "Description" SG_ 3221225472 ABSD_RLBrkCtrlReq "This signal inform ESC whether to control RL wheel or not";
BA_ "UsrSigTimeoutValue" SG_ 3221225472 ABSD_RLBrkCtrlReq "";
BA_ "UserSigValidity" SG_ 3221225472 ABSD_RLBrkCtrlReq 3;
BA_ "SignalLongName" SG_ 3221225472 ABSD_RLBrkCtrlReq "ABSD_RearLeftBrakeControlRequest";
BA_ "Version" SG_ 3221225472 ABSD_RRBrkCtrlReq "1.0";
BA_ "Description" SG_ 3221225472 ABSD_RRBrkCtrlReq "This signal inform ESC whether to control RR wheel or not";
BA_ "UsrSigTimeoutValue" SG_ 3221225472 ABSD_RRBrkCtrlReq "";
BA_ "UserSigValidity" SG_ 3221225472 ABSD_RRBrkCtrlReq 3;
BA_ "SignalLongName" SG_ 3221225472 ABSD_RRBrkCtrlReq "ABSD_RearRightBrakeControlRequest";
BA_ "Version" SG_ 3221225472 ABSD_FrWhlTrgtBrkPrsrVal "1.0";
BA_ "Description" SG_ 3221225472 ABSD_FrWhlTrgtBrkPrsrVal "This signal indicates Front_Target_Pressure";
BA_ "UsrSigTimeoutValue" SG_ 3221225472 ABSD_FrWhlTrgtBrkPrsrVal "";
BA_ "UserSigValidity" SG_ 3221225472 ABSD_FrWhlTrgtBrkPrsrVal 3;
BA_ "SignalLongName" SG_ 3221225472 ABSD_FrWhlTrgtBrkPrsrVal "ABSD_FrontWheelTargetBrakingPressure";
BA_ "Version" SG_ 3221225472 ABSD_RrWhlTrgtBrkPrsrVal "1.0";
BA_ "Description" SG_ 3221225472 ABSD_RrWhlTrgtBrkPrsrVal "This signal indicates Rear_Target_Pressure";
BA_ "UsrSigTimeoutValue" SG_ 3221225472 ABSD_RrWhlTrgtBrkPrsrVal "";
BA_ "UserSigValidity" SG_ 3221225472 ABSD_RrWhlTrgtBrkPrsrVal 3;
BA_ "SignalLongName" SG_ 3221225472 ABSD_RrWhlTrgtBrkPrsrVal "ABSD_RearWheelTargetBrakingPressure";
BA_ "GenSigSendType" SG_ 1761 XCP_RESPONSE_DATA 0;
BA_ "GenSigSendType" SG_ 1617 AtmResp_Sig_AddExp4 1;
BA_ "GenSigSendType" SG_ 1617 AtmResp_Sig_AddExp3 1;
BA_ "GenSigSendType" SG_ 1617 AtmResp_Sig_AddExp2 1;
BA_ "GenSigSendType" SG_ 1617 AtmResp_Sig_AddExp1 1;
BA_ "GenSigSendType" SG_ 1617 AtmResp_Sig_Result 1;
BA_ "GenSigSendType" SG_ 1617 AtmResp_Sig_TestCaseNum 1;
BA_ "GenSigSendType" SG_ 1617 AtmResp_Sig_TestFunction 1;
BA_ "GenSigSendType" SG_ 1617 AtmResp_Sig_ModuleId 1;
BA_ "SignalLongName" SG_ 396 TCU_AlvCnt1Val_Rx_P11 "TCU_AliveCounter1Value";
BA_ "UserSigValidity" SG_ 396 TCU_AlvCnt1Val_Rx_P11 3;
BA_ "UsrSigTimeoutValue" SG_ 396 TCU_AlvCnt1Val_Rx_P11 "";
BA_ "Description" SG_ 396 TCU_AlvCnt1Val_Rx_P11 "Alive Counter";
BA_ "Version" SG_ 396 TCU_AlvCnt1Val_Rx_P11 "1.0";
BA_ "SignalLongName" SG_ 396 TCU_EngRpmDisSta_Rx_P11 "TCU_EngineRpmDisplayStatus";
BA_ "UserSigValidity" SG_ 396 TCU_EngRpmDisSta_Rx_P11 3;
BA_ "UsrSigTimeoutValue" SG_ 396 TCU_EngRpmDisSta_Rx_P11 "";
BA_ "Description" SG_ 396 TCU_EngRpmDisSta_Rx_P11 "Flag for Engine RPM(from TCU) Display on Cluster, Only when this flag is set to 1, Cluster shall display the Engine RPM from TCU";
BA_ "Version" SG_ 396 TCU_EngRpmDisSta_Rx_P11 "1.0";
BA_ "SignalLongName" SG_ 396 TCU_Crc1Val_Rx_P11 "TCU_Crc1Value";
BA_ "UserSigValidity" SG_ 396 TCU_Crc1Val_Rx_P11 3;
BA_ "UsrSigTimeoutValue" SG_ 396 TCU_Crc1Val_Rx_P11 "";
BA_ "Description" SG_ 396 TCU_Crc1Val_Rx_P11 "(PH) = 10H-(Least significant nibbles of (Byte0 + Byte1 + Byte2 + Byte3+ Byte4 + Byte5 + Byte6 + Byte7) + Most significant nibbles of (Byte0 + Byte1 + Byte2 + Byte3 + Byte4 + Byte5 + Byte6))";
BA_ "Version" SG_ 396 TCU_Crc1Val_Rx_P11 "1.0";
BA_ "SignalLongName" SG_ 66 TCU_AlvCnt1Val_Tx_P11 "TCU_AliveCounter1Value";
BA_ "UserSigValidity" SG_ 66 TCU_AlvCnt1Val_Tx_P11 3;
BA_ "UsrSigTimeoutValue" SG_ 66 TCU_AlvCnt1Val_Tx_P11 "";
BA_ "Description" SG_ 66 TCU_AlvCnt1Val_Tx_P11 "Alive Counter";
BA_ "Version" SG_ 66 TCU_AlvCnt1Val_Tx_P11 "1.0";
BA_ "SignalLongName" SG_ 66 TCU_EngRpmDisSta_Tx_P11 "TCU_EngineRpmDisplayStatus";
BA_ "UserSigValidity" SG_ 66 TCU_EngRpmDisSta_Tx_P11 3;
BA_ "UsrSigTimeoutValue" SG_ 66 TCU_EngRpmDisSta_Tx_P11 "";
BA_ "Description" SG_ 66 TCU_EngRpmDisSta_Tx_P11 "Flag for Engine RPM(from TCU) Display on Cluster, Only when this flag is set to 1, Cluster shall display the Engine RPM from TCU";
BA_ "Version" SG_ 66 TCU_EngRpmDisSta_Tx_P11 "1.0";
BA_ "SignalLongName" SG_ 66 TCU_Crc1Val_Tx_P11 "TCU_Crc1Value";
BA_ "UserSigValidity" SG_ 66 TCU_Crc1Val_Tx_P11 3;
BA_ "UsrSigTimeoutValue" SG_ 66 TCU_Crc1Val_Tx_P11 "";
BA_ "Description" SG_ 66 TCU_Crc1Val_Tx_P11 "(PH) = 10H-(Least significant nibbles of (Byte0 + Byte1 + Byte2 + Byte3+ Byte4 + Byte5 + Byte6 + Byte7) + Most significant nibbles of (Byte0 + Byte1 + Byte2 + Byte3 + Byte4 + Byte5 + Byte6))";
BA_ "Version" SG_ 66 TCU_Crc1Val_Tx_P11 "1.0";
BA_ "Version" SG_ 65 TCU_AlvCnt1Val_Tx_P06 "1.0";
BA_ "Description" SG_ 65 TCU_AlvCnt1Val_Tx_P06 "Alive Counter";
BA_ "UsrSigTimeoutValue" SG_ 65 TCU_AlvCnt1Val_Tx_P06 "";
BA_ "UserSigValidity" SG_ 65 TCU_AlvCnt1Val_Tx_P06 3;
BA_ "SignalLongName" SG_ 65 TCU_AlvCnt1Val_Tx_P06 "TCU_AliveCounter1Value";
BA_ "Version" SG_ 65 TCU_Crc1Val_Tx_P06 "1.0";
BA_ "Description" SG_ 65 TCU_Crc1Val_Tx_P06 "(PH) = 10H-(Least significant nibbles of (Byte0 + Byte1 + Byte2 + Byte3+ Byte4 + Byte5 + Byte6 + Byte7) + Most significant nibbles of (Byte0 + Byte1 + Byte2 + Byte3 + Byte4 + Byte5 + Byte6))";
BA_ "GenSigStartValue" SG_ 65 TCU_Crc1Val_Tx_P06 4095;
BA_ "UsrSigTimeoutValue" SG_ 65 TCU_Crc1Val_Tx_P06 "";
BA_ "UserSigValidity" SG_ 65 TCU_Crc1Val_Tx_P06 3;
BA_ "SignalLongName" SG_ 65 TCU_Crc1Val_Tx_P06 "TCU_Crc1Value";
BA_ "Version" SG_ 65 TCU_EngRpmDisSta_Tx_P06 "1.0";
BA_ "Description" SG_ 65 TCU_EngRpmDisSta_Tx_P06 "Flag for Engine RPM(from TCU) Display on Cluster, Only when this flag is set to 1, Cluster shall display the Engine RPM from TCU";
BA_ "UsrSigTimeoutValue" SG_ 65 TCU_EngRpmDisSta_Tx_P06 "";
BA_ "UserSigValidity" SG_ 65 TCU_EngRpmDisSta_Tx_P06 3;
BA_ "SignalLongName" SG_ 65 TCU_EngRpmDisSta_Tx_P06 "TCU_EngineRpmDisplayStatus";
BA_ "Version" SG_ 395 TCU_AlvCnt1Val_Rx_P06 "1.0";
BA_ "Description" SG_ 395 TCU_AlvCnt1Val_Rx_P06 "Alive Counter";
BA_ "UsrSigTimeoutValue" SG_ 395 TCU_AlvCnt1Val_Rx_P06 "";
BA_ "UserSigValidity" SG_ 395 TCU_AlvCnt1Val_Rx_P06 3;
BA_ "SignalLongName" SG_ 395 TCU_AlvCnt1Val_Rx_P06 "TCU_AliveCounter1Value";
BA_ "Version" SG_ 395 TCU_Crc1Val_Rx_P06 "1.0";
BA_ "Description" SG_ 395 TCU_Crc1Val_Rx_P06 "(PH) = 10H-(Least significant nibbles of (Byte0 + Byte1 + Byte2 + Byte3+ Byte4 + Byte5 + Byte6 + Byte7) + Most significant nibbles of (Byte0 + Byte1 + Byte2 + Byte3 + Byte4 + Byte5 + Byte6))";
BA_ "GenSigStartValue" SG_ 395 TCU_Crc1Val_Rx_P06 4095;
BA_ "UsrSigTimeoutValue" SG_ 395 TCU_Crc1Val_Rx_P06 "";
BA_ "UserSigValidity" SG_ 395 TCU_Crc1Val_Rx_P06 3;
BA_ "SignalLongName" SG_ 395 TCU_Crc1Val_Rx_P06 "TCU_Crc1Value";
BA_ "Version" SG_ 395 TCU_EngRpmDisSta_Rx_P06 "1.0";
BA_ "Description" SG_ 395 TCU_EngRpmDisSta_Rx_P06 "Flag for Engine RPM(from TCU) Display on Cluster, Only when this flag is set to 1, Cluster shall display the Engine RPM from TCU";
BA_ "UsrSigTimeoutValue" SG_ 395 TCU_EngRpmDisSta_Rx_P06 "";
BA_ "UserSigValidity" SG_ 395 TCU_EngRpmDisSta_Rx_P06 3;
BA_ "SignalLongName" SG_ 395 TCU_EngRpmDisSta_Rx_P06 "TCU_EngineRpmDisplayStatus";
BA_ "UserSigValidity" SG_ 1288 SNI_CGW 0;
BA_ "GenSigTimeoutTime" SG_ 1288 SNI_CGW 0;
BA_ "UsrSigPurpose" SG_ 1288 SNI_CGW 4;
BA_ "NetworkRequest" SG_ 1288 SNI_CGW 0;
BA_ "NetworkRequestHoldingTime" SG_ 1288 SNI_CGW 5000;
BA_ "UserSigValidity" SG_ 1288 CBV_RMR_CGW 0;
BA_ "GenSigTimeoutTime" SG_ 1288 CBV_RMR_CGW 0;
BA_ "UsrSigPurpose" SG_ 1288 CBV_RMR_CGW 4;
BA_ "NetworkRequest" SG_ 1288 CBV_RMR_CGW 0;
BA_ "NetworkRequestHoldingTime" SG_ 1288 CBV_RMR_CGW 5000;
BA_ "UserSigValidity" SG_ 1288 CBV_PNIB_CGW 0;
BA_ "GenSigTimeoutTime" SG_ 1288 CBV_PNIB_CGW 0;
BA_ "UsrSigPurpose" SG_ 1288 CBV_PNIB_CGW 4;
BA_ "NetworkRequest" SG_ 1288 CBV_PNIB_CGW 0;
BA_ "NetworkRequestHoldingTime" SG_ 1288 CBV_PNIB_CGW 5000;
BA_ "UserSigValidity" SG_ 1288 CBV_NMCoSRB_CGW 0;
BA_ "GenSigTimeoutTime" SG_ 1288 CBV_NMCoSRB_CGW 0;
BA_ "UsrSigPurpose" SG_ 1288 CBV_NMCoSRB_CGW 4;
BA_ "NetworkRequest" SG_ 1288 CBV_NMCoSRB_CGW 0;
BA_ "NetworkRequestHoldingTime" SG_ 1288 CBV_NMCoSRB_CGW 5000;
BA_ "UserSigValidity" SG_ 1288 CBV_NMCoID_CGW 0;
BA_ "GenSigTimeoutTime" SG_ 1288 CBV_NMCoID_CGW 0;
BA_ "UsrSigPurpose" SG_ 1288 CBV_NMCoID_CGW 4;
BA_ "NetworkRequest" SG_ 1288 CBV_NMCoID_CGW 0;
BA_ "NetworkRequestHoldingTime" SG_ 1288 CBV_NMCoID_CGW 5000;
BA_ "UserSigValidity" SG_ 1288 CBV_AWB_CGW 0;
BA_ "GenSigTimeoutTime" SG_ 1288 CBV_AWB_CGW 0;
BA_ "UsrSigPurpose" SG_ 1288 CBV_AWB_CGW 4;
BA_ "NetworkRequest" SG_ 1288 CBV_AWB_CGW 0;
BA_ "NetworkRequestHoldingTime" SG_ 1288 CBV_AWB_CGW 5000;
BA_ "UserSigValidity" SG_ 1288 PNI_CGW 0;
BA_ "GenSigTimeoutTime" SG_ 1288 PNI_CGW 0;
BA_ "UsrSigPurpose" SG_ 1288 PNI_CGW 4;
BA_ "NetworkRequest" SG_ 1288 PNI_CGW 0;
BA_ "NetworkRequestHoldingTime" SG_ 1288 PNI_CGW 5000;
BA_ "UserSigValidity" SG_ 1288 NM_State_CGW 0;
BA_ "GenSigTimeoutTime" SG_ 1288 NM_State_CGW 0;
BA_ "UsrSigPurpose" SG_ 1288 NM_State_CGW 4;
BA_ "NetworkRequest" SG_ 1288 NM_State_CGW 0;
BA_ "NetworkRequestHoldingTime" SG_ 1288 NM_State_CGW 5000;
BA_ "UserSigValidity" SG_ 1285 SNI_CGW 0;
BA_ "GenSigTimeoutTime" SG_ 1285 SNI_CGW 0;
BA_ "UsrSigPurpose" SG_ 1285 SNI_CGW 4;
BA_ "NetworkRequest" SG_ 1285 SNI_CGW 0;
BA_ "NetworkRequestHoldingTime" SG_ 1285 SNI_CGW 5000;
BA_ "UserSigValidity" SG_ 1285 CBV_RMR_CGW 0;
BA_ "GenSigTimeoutTime" SG_ 1285 CBV_RMR_CGW 0;
BA_ "UsrSigPurpose" SG_ 1285 CBV_RMR_CGW 4;
BA_ "NetworkRequest" SG_ 1285 CBV_RMR_CGW 0;
BA_ "NetworkRequestHoldingTime" SG_ 1285 CBV_RMR_CGW 5000;
BA_ "UserSigValidity" SG_ 1285 CBV_PNIB_CGW 0;
BA_ "GenSigTimeoutTime" SG_ 1285 CBV_PNIB_CGW 0;
BA_ "UsrSigPurpose" SG_ 1285 CBV_PNIB_CGW 4;
BA_ "NetworkRequest" SG_ 1285 CBV_PNIB_CGW 0;
BA_ "NetworkRequestHoldingTime" SG_ 1285 CBV_PNIB_CGW 5000;
BA_ "UserSigValidity" SG_ 1285 CBV_NMCoSRB_CGW 0;
BA_ "GenSigTimeoutTime" SG_ 1285 CBV_NMCoSRB_CGW 0;
BA_ "UsrSigPurpose" SG_ 1285 CBV_NMCoSRB_CGW 4;
BA_ "NetworkRequest" SG_ 1285 CBV_NMCoSRB_CGW 0;
BA_ "NetworkRequestHoldingTime" SG_ 1285 CBV_NMCoSRB_CGW 5000;
BA_ "UserSigValidity" SG_ 1285 CBV_NMCoID_CGW 0;
BA_ "GenSigTimeoutTime" SG_ 1285 CBV_NMCoID_CGW 0;
BA_ "UsrSigPurpose" SG_ 1285 CBV_NMCoID_CGW 4;
BA_ "NetworkRequest" SG_ 1285 CBV_NMCoID_CGW 0;
BA_ "NetworkRequestHoldingTime" SG_ 1285 CBV_NMCoID_CGW 5000;
BA_ "UserSigValidity" SG_ 1285 CBV_AWB_CGW 0;
BA_ "GenSigTimeoutTime" SG_ 1285 CBV_AWB_CGW 0;
BA_ "UsrSigPurpose" SG_ 1285 CBV_AWB_CGW 4;
BA_ "NetworkRequest" SG_ 1285 CBV_AWB_CGW 0;
BA_ "NetworkRequestHoldingTime" SG_ 1285 CBV_AWB_CGW 5000;
BA_ "UserSigValidity" SG_ 1285 PNI_CGW 0;
BA_ "GenSigTimeoutTime" SG_ 1285 PNI_CGW 0;
BA_ "UsrSigPurpose" SG_ 1285 PNI_CGW 4;
BA_ "NetworkRequest" SG_ 1285 PNI_CGW 0;
BA_ "NetworkRequestHoldingTime" SG_ 1285 PNI_CGW 5000;
BA_ "UserSigValidity" SG_ 1285 NM_State_CGW 0;
BA_ "GenSigTimeoutTime" SG_ 1285 NM_State_CGW 0;
BA_ "UsrSigPurpose" SG_ 1285 NM_State_CGW 4;
BA_ "NetworkRequest" SG_ 1285 NM_State_CGW 0;
BA_ "NetworkRequestHoldingTime" SG_ 1285 NM_State_CGW 5000;
BA_ "UserSigValidity" SG_ 1282 SNI_CGW 0;
BA_ "GenSigTimeoutTime" SG_ 1282 SNI_CGW 0;
BA_ "UsrSigPurpose" SG_ 1282 SNI_CGW 4;
BA_ "NetworkRequest" SG_ 1282 SNI_CGW 0;
BA_ "NetworkRequestHoldingTime" SG_ 1282 SNI_CGW 5000;
BA_ "UserSigValidity" SG_ 1282 CBV_RMR_CGW 0;
BA_ "GenSigTimeoutTime" SG_ 1282 CBV_RMR_CGW 0;
BA_ "UsrSigPurpose" SG_ 1282 CBV_RMR_CGW 4;
BA_ "NetworkRequest" SG_ 1282 CBV_RMR_CGW 0;
BA_ "NetworkRequestHoldingTime" SG_ 1282 CBV_RMR_CGW 5000;
BA_ "UserSigValidity" SG_ 1282 CBV_PNIB_CGW 0;
BA_ "GenSigTimeoutTime" SG_ 1282 CBV_PNIB_CGW 0;
BA_ "UsrSigPurpose" SG_ 1282 CBV_PNIB_CGW 4;
BA_ "NetworkRequest" SG_ 1282 CBV_PNIB_CGW 0;
BA_ "NetworkRequestHoldingTime" SG_ 1282 CBV_PNIB_CGW 5000;
BA_ "UserSigValidity" SG_ 1282 CBV_NMCoSRB_CGW 0;
BA_ "GenSigTimeoutTime" SG_ 1282 CBV_NMCoSRB_CGW 0;
BA_ "UsrSigPurpose" SG_ 1282 CBV_NMCoSRB_CGW 4;
BA_ "NetworkRequest" SG_ 1282 CBV_NMCoSRB_CGW 0;
BA_ "NetworkRequestHoldingTime" SG_ 1282 CBV_NMCoSRB_CGW 5000;
BA_ "UserSigValidity" SG_ 1282 CBV_NMCoID_CGW 0;
BA_ "GenSigTimeoutTime" SG_ 1282 CBV_NMCoID_CGW 0;
BA_ "UsrSigPurpose" SG_ 1282 CBV_NMCoID_CGW 4;
BA_ "NetworkRequest" SG_ 1282 CBV_NMCoID_CGW 0;
BA_ "NetworkRequestHoldingTime" SG_ 1282 CBV_NMCoID_CGW 5000;
BA_ "UserSigValidity" SG_ 1282 CBV_AWB_CGW 0;
BA_ "GenSigTimeoutTime" SG_ 1282 CBV_AWB_CGW 0;
BA_ "UsrSigPurpose" SG_ 1282 CBV_AWB_CGW 4;
BA_ "NetworkRequest" SG_ 1282 CBV_AWB_CGW 0;
BA_ "NetworkRequestHoldingTime" SG_ 1282 CBV_AWB_CGW 5000;
BA_ "UserSigValidity" SG_ 1282 PNI_CGW 0;
BA_ "GenSigTimeoutTime" SG_ 1282 PNI_CGW 0;
BA_ "UsrSigPurpose" SG_ 1282 PNI_CGW 4;
BA_ "NetworkRequest" SG_ 1282 PNI_CGW 0;
BA_ "NetworkRequestHoldingTime" SG_ 1282 PNI_CGW 5000;
BA_ "UserSigValidity" SG_ 1282 NM_State_CGW 0;
BA_ "GenSigTimeoutTime" SG_ 1282 NM_State_CGW 0;
BA_ "UsrSigPurpose" SG_ 1282 NM_State_CGW 4;
BA_ "NetworkRequest" SG_ 1282 NM_State_CGW 0;
BA_ "NetworkRequestHoldingTime" SG_ 1282 NM_State_CGW 5000;
BA_ "Version" SG_ 464 ECS_Crc1Val "1.0";
BA_ "GenSigStartValue" SG_ 464 ECS_Crc1Val 4095;
BA_ "UsrSigTimeoutValue" SG_ 464 ECS_Crc1Val "";
BA_ "GenSigTimeoutTime" SG_ 464 ECS_Crc1Val 2000;
BA_ "UserSigValidity" SG_ 464 ECS_Crc1Val 3;
BA_ "SignalLongName" SG_ 464 ECS_Crc1Val "ECS_Crc1Value";
BA_ "Version" SG_ 464 ECS_AlvCnt1Val "1.0";
BA_ "UsrSigTimeoutValue" SG_ 464 ECS_AlvCnt1Val "";
BA_ "GenSigTimeoutTime" SG_ 464 ECS_AlvCnt1Val 2000;
BA_ "UserSigValidity" SG_ 464 ECS_AlvCnt1Val 3;
BA_ "SignalLongName" SG_ 464 ECS_AlvCnt1Val "ECS_AliveCounter1Value";
BA_ "Version" SG_ 464 ECS_WrngLmpSta "1.0";
BA_ "Description" SG_ 464 ECS_WrngLmpSta "The signal indicates the status of the “ECS warning lamp”";
BA_ "UsrSigTimeoutValue" SG_ 464 ECS_WrngLmpSta "";
BA_ "GenSigTimeoutTime" SG_ 464 ECS_WrngLmpSta 2000;
BA_ "UserSigValidity" SG_ 464 ECS_WrngLmpSta 3;
BA_ "SignalLongName" SG_ 464 ECS_WrngLmpSta "ECS_WarningLampStatus";
BA_ "Version" SG_ 464 ECS_DfctvSta "1.0";
BA_ "Description" SG_ 464 ECS_DfctvSta "Information regarding the ECS “defective” indication";
BA_ "UsrSigTimeoutValue" SG_ 464 ECS_DfctvSta "";
BA_ "GenSigTimeoutTime" SG_ 464 ECS_DfctvSta 2000;
BA_ "UserSigValidity" SG_ 464 ECS_DfctvSta 3;
BA_ "SignalLongName" SG_ 464 ECS_DfctvSta "ECS_DefectiveStatus";
BA_ "Version" SG_ 464 ECS_DiagSta "1.0";
BA_ "Description" SG_ 464 ECS_DiagSta "Information regarding the ECS “diagnosis states” indication";
BA_ "UsrSigTimeoutValue" SG_ 464 ECS_DiagSta "";
BA_ "GenSigTimeoutTime" SG_ 464 ECS_DiagSta 2000;
BA_ "UserSigValidity" SG_ 464 ECS_DiagSta 3;
BA_ "SignalLongName" SG_ 464 ECS_DiagSta "ECS_DiagosisStatus";
BA_ "Version" SG_ 464 ECS_DmpModSta "1.0";
BA_ "Description" SG_ 464 ECS_DmpModSta "The actual damping mode of an ECS system";
BA_ "UsrSigTimeoutValue" SG_ 464 ECS_DmpModSta "";
BA_ "GenSigTimeoutTime" SG_ 464 ECS_DmpModSta 2000;
BA_ "UserSigValidity" SG_ 464 ECS_DmpModSta 3;
BA_ "SignalLongName" SG_ 464 ECS_DmpModSta "ECS_DampingModeStatus";
BA_ "Version" SG_ 464 ECS_DmpModReq "1.0";
BA_ "Description" SG_ 464 ECS_DmpModReq "Requested damping mode set by ECS manual switch";
BA_ "UsrSigTimeoutValue" SG_ 464 ECS_DmpModReq "";
BA_ "GenSigTimeoutTime" SG_ 464 ECS_DmpModReq 2000;
BA_ "UserSigValidity" SG_ 464 ECS_DmpModReq 3;
BA_ "SignalLongName" SG_ 464 ECS_DmpModReq "ECS_DampingModeRequest";
BA_ "Version" SG_ 464 ECS_SysUnblSta "1.0";
BA_ "Description" SG_ 464 ECS_SysUnblSta "System temporary not available because of over-heat, no enough air, etc.";
BA_ "UsrSigTimeoutValue" SG_ 464 ECS_SysUnblSta "";
BA_ "GenSigTimeoutTime" SG_ 464 ECS_SysUnblSta 2000;
BA_ "UserSigValidity" SG_ 464 ECS_SysUnblSta 3;
BA_ "SignalLongName" SG_ 464 ECS_SysUnblSta "ECS_SystemUnavailableStatus";
BA_ "Version" SG_ 330 ECS_Crc2Val "1.0";
BA_ "GenSigStartValue" SG_ 330 ECS_Crc2Val 4095;
BA_ "UsrSigTimeoutValue" SG_ 330 ECS_Crc2Val "";
BA_ "UserSigValidity" SG_ 330 ECS_Crc2Val 3;
BA_ "SignalLongName" SG_ 330 ECS_Crc2Val "ECS_Crc2Value";
BA_ "Version" SG_ 330 ECS_AlvCnt2Val "1.0";
BA_ "UsrSigTimeoutValue" SG_ 330 ECS_AlvCnt2Val "";
BA_ "UserSigValidity" SG_ 330 ECS_AlvCnt2Val 3;
BA_ "SignalLongName" SG_ 330 ECS_AlvCnt2Val "ECS_AliveCounter2Value";
BA_ "Version" SG_ 330 ECS_ALS_FLHghtVal "1.0";
BA_ "Description" SG_ 330 ECS_ALS_FLHghtVal "Actual height of each corner of a vehicle.";
BA_ "GenSigStartValue" SG_ 330 ECS_ALS_FLHghtVal 128;
BA_ "UsrSigTimeoutValue" SG_ 330 ECS_ALS_FLHghtVal "";
BA_ "UserSigValidity" SG_ 330 ECS_ALS_FLHghtVal 3;
BA_ "SignalLongName" SG_ 330 ECS_ALS_FLHghtVal "ECS_ALS_FrontLeftHeightValue";
BA_ "Version" SG_ 330 ECS_ALS_FRHghtVal "1.0";
BA_ "Description" SG_ 330 ECS_ALS_FRHghtVal "Actual height of each corner of a vehicle.";
BA_ "GenSigStartValue" SG_ 330 ECS_ALS_FRHghtVal 128;
BA_ "UsrSigTimeoutValue" SG_ 330 ECS_ALS_FRHghtVal "";
BA_ "UserSigValidity" SG_ 330 ECS_ALS_FRHghtVal 3;
BA_ "SignalLongName" SG_ 330 ECS_ALS_FRHghtVal "ECS_ALS_FrontRightHeightValue";
BA_ "Version" SG_ 330 ECS_ALS_RLHghtVal "1.0";
BA_ "Description" SG_ 330 ECS_ALS_RLHghtVal "Actual height of each corner of a vehicle.";
BA_ "GenSigStartValue" SG_ 330 ECS_ALS_RLHghtVal 128;
BA_ "UsrSigTimeoutValue" SG_ 330 ECS_ALS_RLHghtVal "";
BA_ "UserSigValidity" SG_ 330 ECS_ALS_RLHghtVal 3;
BA_ "SignalLongName" SG_ 330 ECS_ALS_RLHghtVal "ECS_ALS_RearLeftHeightValue";
BA_ "Version" SG_ 330 ECS_ALS_RRHghtVal "1.0";
BA_ "Description" SG_ 330 ECS_ALS_RRHghtVal "Actual height of each corner of a vehicle.";
BA_ "GenSigStartValue" SG_ 330 ECS_ALS_RRHghtVal 128;
BA_ "UsrSigTimeoutValue" SG_ 330 ECS_ALS_RRHghtVal "";
BA_ "UserSigValidity" SG_ 330 ECS_ALS_RRHghtVal 3;
BA_ "SignalLongName" SG_ 330 ECS_ALS_RRHghtVal "ECS_ALS_RearRightHeightValue";
BA_ "Version" SG_ 330 ECS_ALS_HghtLvlChgUnblSta "1.0";
BA_ "Description" SG_ 330 ECS_ALS_HghtLvlChgUnblSta "Height level change by ECS switch is not available.

This signal will be set after a manual level/damping request by the driver only for one loop.";
BA_ "UsrSigTimeoutValue" SG_ 330 ECS_ALS_HghtLvlChgUnblSta "";
BA_ "UserSigValidity" SG_ 330 ECS_ALS_HghtLvlChgUnblSta 3;
BA_ "SignalLongName" SG_ 330 ECS_ALS_HghtLvlChgUnblSta "ECS_ALS_HeightLevelChangeUnavailableStatus";
BA_ "Version" SG_ 330 ECS_ALS_LvlOffSta "1.0";
BA_ "Description" SG_ 330 ECS_ALS_LvlOffSta "The signal indicates the status of leveling deactivation.";
BA_ "UsrSigTimeoutValue" SG_ 330 ECS_ALS_LvlOffSta "";
BA_ "UserSigValidity" SG_ 330 ECS_ALS_LvlOffSta 3;
BA_ "SignalLongName" SG_ 330 ECS_ALS_LvlOffSta "ECS_ALS_LevelingOffStatus";
BA_ "Version" SG_ 330 ECS_ALS_LvlCtrlUnblOvhtSta "1.0";
BA_ "Description" SG_ 330 ECS_ALS_LvlCtrlUnblOvhtSta "The signal indicates that leveling control is temporary not available due to actuator overheat.";
BA_ "UsrSigTimeoutValue" SG_ 330 ECS_ALS_LvlCtrlUnblOvhtSta "";
BA_ "UserSigValidity" SG_ 330 ECS_ALS_LvlCtrlUnblOvhtSta 3;
BA_ "SignalLongName" SG_ 330 ECS_ALS_LvlCtrlUnblOvhtSta "ECS_ALS_LevelingControlUnavailableOverheatStatus";
BA_ "Version" SG_ 330 ECS_ALS_LftngSta "1.0";
BA_ "Description" SG_ 330 ECS_ALS_LftngSta "ECS is raising a vehicle to a higher level.";
BA_ "UsrSigTimeoutValue" SG_ 330 ECS_ALS_LftngSta "";
BA_ "UserSigValidity" SG_ 330 ECS_ALS_LftngSta 3;
BA_ "SignalLongName" SG_ 330 ECS_ALS_LftngSta "ECS_ALS_LiftingStatus";
BA_ "Version" SG_ 330 ECS_ALS_LwrngSta "1.0";
BA_ "Description" SG_ 330 ECS_ALS_LwrngSta "ECS is lowering a vehicle to a lower level.";
BA_ "UsrSigTimeoutValue" SG_ 330 ECS_ALS_LwrngSta "";
BA_ "UserSigValidity" SG_ 330 ECS_ALS_LwrngSta 3;
BA_ "SignalLongName" SG_ 330 ECS_ALS_LwrngSta "ECS_ALS_LoweringStatus";
BA_ "Version" SG_ 330 ECS_ALS_HghtReq "1.0";
BA_ "Description" SG_ 330 ECS_ALS_HghtReq "Requested level by ECS manual switch.

This signal will be set after a manual level request by a driver only for one loop.";
BA_ "UsrSigTimeoutValue" SG_ 330 ECS_ALS_HghtReq "";
BA_ "UserSigValidity" SG_ 330 ECS_ALS_HghtReq 3;
BA_ "SignalLongName" SG_ 330 ECS_ALS_HghtReq "ECS_ALS_HeightRequest";
BA_ "Version" SG_ 330 ECS_ALS_LvlReq "1.0";
BA_ "Description" SG_ 330 ECS_ALS_LvlReq "Requested level by ECS switch or automatic

(1) Without automatic or manual level changes REQ_level=ACT_Height

(2) During level changes new target level = REQ_level. Until the new target level is reached, REQ_level ≠ ACT_Height. 

When the new target l";
BA_ "UsrSigTimeoutValue" SG_ 330 ECS_ALS_LvlReq "";
BA_ "UserSigValidity" SG_ 330 ECS_ALS_LvlReq 3;
BA_ "SignalLongName" SG_ 330 ECS_ALS_LvlReq "ECS_ALS_LevelRequest";
BA_ "Version" SG_ 330 ECS_ALS_ActlHghtSta "1.0";
BA_ "Description" SG_ 330 ECS_ALS_ActlHghtSta "The vehicle level of the last finished vehicle level control is indicated. If a new level change is requested and could not be finished it is not shown. Dynamic deviation of actual height is possible.";
BA_ "UsrSigTimeoutValue" SG_ 330 ECS_ALS_ActlHghtSta "";
BA_ "UserSigValidity" SG_ 330 ECS_ALS_ActlHghtSta 3;
BA_ "SignalLongName" SG_ 330 ECS_ALS_ActlHghtSta "ECS_ALS_ActualHeightLevelStatus";
BA_ "Version" SG_ 330 ECS_ALS_SysUnblSta "1.0";
BA_ "Description" SG_ 330 ECS_ALS_SysUnblSta "System temporary not available because of over-heat, no enough air, etc.";
BA_ "UsrSigTimeoutValue" SG_ 330 ECS_ALS_SysUnblSta "";
BA_ "UserSigValidity" SG_ 330 ECS_ALS_SysUnblSta 3;
BA_ "SignalLongName" SG_ 330 ECS_ALS_SysUnblSta "ECS_ALS_SystemUnavailableStatus";
BA_ "Version" SG_ 122 ECS_Crc3Val "1.0";
BA_ "GenSigStartValue" SG_ 122 ECS_Crc3Val 4095;
BA_ "UsrSigTimeoutValue" SG_ 122 ECS_Crc3Val "";
BA_ "UserSigValidity" SG_ 122 ECS_Crc3Val 3;
BA_ "SignalLongName" SG_ 122 ECS_Crc3Val "ECS_Crc3Value";
BA_ "Version" SG_ 122 ECS_AlvCnt3Val "1.0";
BA_ "UsrSigTimeoutValue" SG_ 122 ECS_AlvCnt3Val "";
BA_ "UserSigValidity" SG_ 122 ECS_AlvCnt3Val 3;
BA_ "SignalLongName" SG_ 122 ECS_AlvCnt3Val "ECS_AliveCounter3Value";
BA_ "Version" SG_ 122 ECSIVSS_FLNmlCurrentVal "1.0";
BA_ "Description" SG_ 122 ECSIVSS_FLNmlCurrentVal "ECS Normalized Current FL (%)

- 0%: Full Soft, 100%: Full Hard";
BA_ "UsrSigTimeoutValue" SG_ 122 ECSIVSS_FLNmlCurrentVal "";
BA_ "UserSigValidity" SG_ 122 ECSIVSS_FLNmlCurrentVal 3;
BA_ "SignalLongName" SG_ 122 ECSIVSS_FLNmlCurrentVal "ECSIVSS_FrontLeftNormalizedCurrentValue";
BA_ "Version" SG_ 122 ECSIVSS_FRNmlCurrentVal "1.0";
BA_ "Description" SG_ 122 ECSIVSS_FRNmlCurrentVal "ECS Normalized Current FR (%)

- 0%: Full Soft, 100%: Full Hard";
BA_ "UsrSigTimeoutValue" SG_ 122 ECSIVSS_FRNmlCurrentVal "";
BA_ "UserSigValidity" SG_ 122 ECSIVSS_FRNmlCurrentVal 3;
BA_ "SignalLongName" SG_ 122 ECSIVSS_FRNmlCurrentVal "ECSIVSS_FrontRightNormalizedCurrentValue";
BA_ "Version" SG_ 122 ECSIVSS_RLNmlCurrentVal "1.0";
BA_ "Description" SG_ 122 ECSIVSS_RLNmlCurrentVal "ECS Normalized Current RL (%)

- 0%: Full Soft, 100%: Full Hard";
BA_ "UsrSigTimeoutValue" SG_ 122 ECSIVSS_RLNmlCurrentVal "";
BA_ "UserSigValidity" SG_ 122 ECSIVSS_RLNmlCurrentVal 3;
BA_ "SignalLongName" SG_ 122 ECSIVSS_RLNmlCurrentVal "ECSIVSS_RearLeftNormalizedCurrentValue";
BA_ "Version" SG_ 122 ECSIVSS_RRNmlCurrentVal "1.0";
BA_ "Description" SG_ 122 ECSIVSS_RRNmlCurrentVal "ECS Normalized Current RR (%)

- 0%: Full Soft, 100%: Full Hard";
BA_ "UsrSigTimeoutValue" SG_ 122 ECSIVSS_RRNmlCurrentVal "";
BA_ "UserSigValidity" SG_ 122 ECSIVSS_RRNmlCurrentVal 3;
BA_ "SignalLongName" SG_ 122 ECSIVSS_RRNmlCurrentVal "ECSIVSS_RearRightNormalizedCurrentValue";
BA_ "Version" SG_ 122 ECSIVSS_FLEstDmpVelVal "1.0";
BA_ "Description" SG_ 122 ECSIVSS_FLEstDmpVelVal "Estimated Damper Velocity - FL";
BA_ "UsrSigTimeoutValue" SG_ 122 ECSIVSS_FLEstDmpVelVal "";
BA_ "UserSigValidity" SG_ 122 ECSIVSS_FLEstDmpVelVal 3;
BA_ "SignalLongName" SG_ 122 ECSIVSS_FLEstDmpVelVal "ECSIVSS_FrontLeftEstimatedDamperVelocity";
VAL_ 3221225472 BSD_AlvCnt1Val 0 "-" 1 "-" 2 "-" 3 "-" 4 "-" 5 "-" 6 "-" 7 "-" 8 "Reserved" 9 "Reserved" 10 "Reserved" 11 "Reserved" 12 "Reserved" 13 "Reserved" 14 "Reserved" 15 "Reserved" ;
VAL_ 3221225472 BSD_Sta 0 "System is Off" 1 "System Passive" 2 "System Active" 3 "System Failure" 4 "System Blockage" 5 "System Overtemperature" 6 "System minor failure" ;
VAL_ 3221225472 BSD_SndWarngSta 0 "Off" 1 "On" 2 "Disable Off" 3 "Disable On" ;
VAL_ 3221225472 BSD_LftIndSta 0 "Indicator output off" 1 "Indicator on (information)" 2 "Indicator blinking(warning)" 3 "Indicator output check" ;
VAL_ 3221225472 BSD_RtIndSta 0 "Indicator output off" 1 "Indicator on (information)" 2 "Indicator blinking(warning)" 3 "Indicator output check" ;
VAL_ 3221225472 BSD_LftSndWrngSta 0 "Speaker is Off" 1 "Speaker On" 2 "Not used" 3 "Error Indicator" ;
VAL_ 3221225472 BSD_RtSndWrngSta 0 "Speaker is Off" 1 "Speaker On" 2 "Not used" 3 "Error Indicator" ;
VAL_ 3221225472 BSD_LftIndBriLvlSta 0 "-" 1 "-" 2 "-" 3 "-" 4 "-" 5 "-" 6 "-" 7 "-" 8 "-" 9 "-" 10 "-" 11 "-" 12 "-" 13 "-" 14 "-" 15 "-" 16 "-" 17 "-" 18 "-" 19 "-" 20 "-" 21 "-" 22 "-" 23 "-" 24 "-" 25 "-" 26 "-" 27 "-" 28 "-" 29 "-" 30 "-" 31 "-" 32 "-" 33 "-" 34 "-" 35 "-" 36 "-" 37 "-" 38 "-" 39 "-" 40 "-" 41 "-" 42 "-" 43 "-" 44 "-" 45 "-" 46 "-" 47 "-" 48 "-" 49 "-" 50 "-" 51 "-" 52 "-" 53 "-" 54 "-" 55 "-" 56 "-" 57 "-" 58 "-" 59 "-" 60 "-" 61 "-" 62 "-" 63 "-" 64 "-" 65 "-" 66 "-" 67 "-" 68 "-" 69 "-" 70 "-" 71 "-" 72 "-" 73 "-" 74 "-" 75 "-" 76 "-" 77 "-" 78 "-" 79 "-" 80 "-" 81 "-" 82 "-" 83 "-" 84 "-" 85 "-" 86 "-" 87 "-" 88 "-" 89 "-" 90 "-" 91 "-" 92 "-" 93 "-" 94 "-" 95 "-" 96 "-" 97 "-" 98 "-" 99 "-" 100 "-" 101 "-" 102 "-" 103 "-" 104 "-" 105 "-" 106 "-" 107 "-" 108 "-" 109 "-" 110 "-" 111 "-" 112 "-" 113 "-" 114 "-" 115 "-" 116 "-" 117 "-" 118 "-" 119 "-" 120 "-" 121 "-" 122 "-" 123 "-" 124 "-" 125 "-" 126 "-" 127 "-" 128 "-" 129 "-" 130 "-" 131 "-" 132 "-" 133 "-" 134 "-" 135 "-" 136 "-" 137 "-" 138 "-" 139 "-" 140 "-" 141 "-" 142 "-" 143 "-" 144 "-" 145 "-" 146 "-" 147 "-" 148 "-" 149 "-" 150 "-" 151 "-" 152 "-" 153 "-" 154 "-" 155 "-" 156 "-" 157 "-" 158 "-" 159 "-" 160 "-" 161 "-" 162 "-" 163 "-" 164 "-" 165 "-" 166 "-" 167 "-" 168 "-" 169 "-" 170 "-" 171 "-" 172 "-" 173 "-" 174 "-" 175 "-" 176 "-" 177 "-" 178 "-" 179 "-" 180 "-" 181 "-" 182 "-" 183 "-" 184 "-" 185 "-" 186 "-" 187 "-" 188 "-" 189 "-" 190 "-" 191 "-" 192 "-" 193 "-" 194 "-" 195 "-" 196 "-" 197 "-" 198 "-" 199 "-" 200 "-" 201 "-" 202 "-" 203 "-" 204 "-" 205 "-" 206 "-" 207 "-" 208 "-" 209 "-" 210 "-" 211 "-" 212 "-" 213 "-" 214 "-" 215 "-" 216 "-" 217 "-" 218 "-" 219 "-" 220 "-" 221 "-" 222 "-" 223 "-" 224 "-" 225 "-" 226 "-" 227 "-" 228 "-" 229 "-" 230 "-" 231 "-" 232 "-" 233 "-" 234 "-" 235 "-" 236 "-" 237 "-" 238 "-" 239 "-" 240 "-" 241 "-" 242 "-" 243 "-" 244 "-" 245 "-" 246 "-" 247 "-" 248 "-" 249 "-" 250 "-" 251 "-" 252 "-" 253 "-" 254 "-" 255 "-" ;
VAL_ 3221225472 BSD_RtIndBriLvlSta 0 "-" 1 "-" 2 "-" 3 "-" 4 "-" 5 "-" 6 "-" 7 "-" 8 "-" 9 "-" 10 "-" 11 "-" 12 "-" 13 "-" 14 "-" 15 "-" 16 "-" 17 "-" 18 "-" 19 "-" 20 "-" 21 "-" 22 "-" 23 "-" 24 "-" 25 "-" 26 "-" 27 "-" 28 "-" 29 "-" 30 "-" 31 "-" 32 "-" 33 "-" 34 "-" 35 "-" 36 "-" 37 "-" 38 "-" 39 "-" 40 "-" 41 "-" 42 "-" 43 "-" 44 "-" 45 "-" 46 "-" 47 "-" 48 "-" 49 "-" 50 "-" 51 "-" 52 "-" 53 "-" 54 "-" 55 "-" 56 "-" 57 "-" 58 "-" 59 "-" 60 "-" 61 "-" 62 "-" 63 "-" 64 "-" 65 "-" 66 "-" 67 "-" 68 "-" 69 "-" 70 "-" 71 "-" 72 "-" 73 "-" 74 "-" 75 "-" 76 "-" 77 "-" 78 "-" 79 "-" 80 "-" 81 "-" 82 "-" 83 "-" 84 "-" 85 "-" 86 "-" 87 "-" 88 "-" 89 "-" 90 "-" 91 "-" 92 "-" 93 "-" 94 "-" 95 "-" 96 "-" 97 "-" 98 "-" 99 "-" 100 "-" 101 "-" 102 "-" 103 "-" 104 "-" 105 "-" 106 "-" 107 "-" 108 "-" 109 "-" 110 "-" 111 "-" 112 "-" 113 "-" 114 "-" 115 "-" 116 "-" 117 "-" 118 "-" 119 "-" 120 "-" 121 "-" 122 "-" 123 "-" 124 "-" 125 "-" 126 "-" 127 "-" 128 "-" 129 "-" 130 "-" 131 "-" 132 "-" 133 "-" 134 "-" 135 "-" 136 "-" 137 "-" 138 "-" 139 "-" 140 "-" 141 "-" 142 "-" 143 "-" 144 "-" 145 "-" 146 "-" 147 "-" 148 "-" 149 "-" 150 "-" 151 "-" 152 "-" 153 "-" 154 "-" 155 "-" 156 "-" 157 "-" 158 "-" 159 "-" 160 "-" 161 "-" 162 "-" 163 "-" 164 "-" 165 "-" 166 "-" 167 "-" 168 "-" 169 "-" 170 "-" 171 "-" 172 "-" 173 "-" 174 "-" 175 "-" 176 "-" 177 "-" 178 "-" 179 "-" 180 "-" 181 "-" 182 "-" 183 "-" 184 "-" 185 "-" 186 "-" 187 "-" 188 "-" 189 "-" 190 "-" 191 "-" 192 "-" 193 "-" 194 "-" 195 "-" 196 "-" 197 "-" 198 "-" 199 "-" 200 "-" 201 "-" 202 "-" 203 "-" 204 "-" 205 "-" 206 "-" 207 "-" 208 "-" 209 "-" 210 "-" 211 "-" 212 "-" 213 "-" 214 "-" 215 "-" 216 "-" 217 "-" 218 "-" 219 "-" 220 "-" 221 "-" 222 "-" 223 "-" 224 "-" 225 "-" 226 "-" 227 "-" 228 "-" 229 "-" 230 "-" 231 "-" 232 "-" 233 "-" 234 "-" 235 "-" 236 "-" 237 "-" 238 "-" 239 "-" 240 "-" 241 "-" 242 "-" 243 "-" 244 "-" 245 "-" 246 "-" 247 "-" 248 "-" 249 "-" 250 "-" 251 "-" 252 "-" 253 "-" 254 "-" 255 "-" ;
VAL_ 3221225472 RCTA_Sta 0 "RCTA is Off" 1 "RCTA Passive" 2 "RCTA Active" 3 "RCTA Failure" 4 "RCTA Blockage" 5 "RCTA Overtemperature" 6 "RCTA Minor Failure" ;
VAL_ 3221225472 RCTA_LftIndSta 0 "Warning is Off" 1 "Warning On" 2 "Not used" 3 "Error Indicator" ;
VAL_ 3221225472 RCTA_RtIndSta 0 "Warning is Off" 1 "Warning On" 2 "Not used" 3 "Error Indicator" ;
VAL_ 3221225472 RCTA_LftSndWrngSta 0 "Speaker is Off" 1 "Speaker On" 2 "Not used" 3 "Error Indicator" ;
VAL_ 3221225472 RCTA_RtSndWrngSta 0 "Speaker is Off" 1 "Speaker On" 2 "Not used" 3 "Error Indicator" ;
VAL_ 3221225472 RCTA_LftWrngIndBriLvlSta 0 "-" 1 "-" 2 "-" 3 "-" 4 "-" 5 "-" 6 "-" 7 "-" 8 "-" 9 "-" 10 "-" 11 "-" 12 "-" 13 "-" 14 "-" 15 "-" 16 "-" 17 "-" 18 "-" 19 "-" 20 "-" 21 "-" 22 "-" 23 "-" 24 "-" 25 "-" 26 "-" 27 "-" 28 "-" 29 "-" 30 "-" 31 "-" 32 "-" 33 "-" 34 "-" 35 "-" 36 "-" 37 "-" 38 "-" 39 "-" 40 "-" 41 "-" 42 "-" 43 "-" 44 "-" 45 "-" 46 "-" 47 "-" 48 "-" 49 "-" 50 "-" 51 "-" 52 "-" 53 "-" 54 "-" 55 "-" 56 "-" 57 "-" 58 "-" 59 "-" 60 "-" 61 "-" 62 "-" 63 "-" 64 "-" 65 "-" 66 "-" 67 "-" 68 "-" 69 "-" 70 "-" 71 "-" 72 "-" 73 "-" 74 "-" 75 "-" 76 "-" 77 "-" 78 "-" 79 "-" 80 "-" 81 "-" 82 "-" 83 "-" 84 "-" 85 "-" 86 "-" 87 "-" 88 "-" 89 "-" 90 "-" 91 "-" 92 "-" 93 "-" 94 "-" 95 "-" 96 "-" 97 "-" 98 "-" 99 "-" 100 "-" 101 "-" 102 "-" 103 "-" 104 "-" 105 "-" 106 "-" 107 "-" 108 "-" 109 "-" 110 "-" 111 "-" 112 "-" 113 "-" 114 "-" 115 "-" 116 "-" 117 "-" 118 "-" 119 "-" 120 "-" 121 "-" 122 "-" 123 "-" 124 "-" 125 "-" 126 "-" 127 "-" 128 "-" 129 "-" 130 "-" 131 "-" 132 "-" 133 "-" 134 "-" 135 "-" 136 "-" 137 "-" 138 "-" 139 "-" 140 "-" 141 "-" 142 "-" 143 "-" 144 "-" 145 "-" 146 "-" 147 "-" 148 "-" 149 "-" 150 "-" 151 "-" 152 "-" 153 "-" 154 "-" 155 "-" 156 "-" 157 "-" 158 "-" 159 "-" 160 "-" 161 "-" 162 "-" 163 "-" 164 "-" 165 "-" 166 "-" 167 "-" 168 "-" 169 "-" 170 "-" 171 "-" 172 "-" 173 "-" 174 "-" 175 "-" 176 "-" 177 "-" 178 "-" 179 "-" 180 "-" 181 "-" 182 "-" 183 "-" 184 "-" 185 "-" 186 "-" 187 "-" 188 "-" 189 "-" 190 "-" 191 "-" 192 "-" 193 "-" 194 "-" 195 "-" 196 "-" 197 "-" 198 "-" 199 "-" 200 "-" 201 "-" 202 "-" 203 "-" 204 "-" 205 "-" 206 "-" 207 "-" 208 "-" 209 "-" 210 "-" 211 "-" 212 "-" 213 "-" 214 "-" 215 "-" 216 "-" 217 "-" 218 "-" 219 "-" 220 "-" 221 "-" 222 "-" 223 "-" 224 "-" 225 "-" 226 "-" 227 "-" 228 "-" 229 "-" 230 "-" 231 "-" 232 "-" 233 "-" 234 "-" 235 "-" 236 "-" 237 "-" 238 "-" 239 "-" 240 "-" 241 "-" 242 "-" 243 "-" 244 "-" 245 "-" 246 "-" 247 "-" 248 "-" 249 "-" 250 "-" 251 "-" 252 "-" 253 "-" 254 "-" 255 "-" ;
VAL_ 3221225472 RCTA_RtWrngIndBriLvlSta 0 "-" 1 "-" 2 "-" 3 "-" 4 "-" 5 "-" 6 "-" 7 "-" 8 "-" 9 "-" 10 "-" 11 "-" 12 "-" 13 "-" 14 "-" 15 "-" 16 "-" 17 "-" 18 "-" 19 "-" 20 "-" 21 "-" 22 "-" 23 "-" 24 "-" 25 "-" 26 "-" 27 "-" 28 "-" 29 "-" 30 "-" 31 "-" 32 "-" 33 "-" 34 "-" 35 "-" 36 "-" 37 "-" 38 "-" 39 "-" 40 "-" 41 "-" 42 "-" 43 "-" 44 "-" 45 "-" 46 "-" 47 "-" 48 "-" 49 "-" 50 "-" 51 "-" 52 "-" 53 "-" 54 "-" 55 "-" 56 "-" 57 "-" 58 "-" 59 "-" 60 "-" 61 "-" 62 "-" 63 "-" 64 "-" 65 "-" 66 "-" 67 "-" 68 "-" 69 "-" 70 "-" 71 "-" 72 "-" 73 "-" 74 "-" 75 "-" 76 "-" 77 "-" 78 "-" 79 "-" 80 "-" 81 "-" 82 "-" 83 "-" 84 "-" 85 "-" 86 "-" 87 "-" 88 "-" 89 "-" 90 "-" 91 "-" 92 "-" 93 "-" 94 "-" 95 "-" 96 "-" 97 "-" 98 "-" 99 "-" 100 "-" 101 "-" 102 "-" 103 "-" 104 "-" 105 "-" 106 "-" 107 "-" 108 "-" 109 "-" 110 "-" 111 "-" 112 "-" 113 "-" 114 "-" 115 "-" 116 "-" 117 "-" 118 "-" 119 "-" 120 "-" 121 "-" 122 "-" 123 "-" 124 "-" 125 "-" 126 "-" 127 "-" 128 "-" 129 "-" 130 "-" 131 "-" 132 "-" 133 "-" 134 "-" 135 "-" 136 "-" 137 "-" 138 "-" 139 "-" 140 "-" 141 "-" 142 "-" 143 "-" 144 "-" 145 "-" 146 "-" 147 "-" 148 "-" 149 "-" 150 "-" 151 "-" 152 "-" 153 "-" 154 "-" 155 "-" 156 "-" 157 "-" 158 "-" 159 "-" 160 "-" 161 "-" 162 "-" 163 "-" 164 "-" 165 "-" 166 "-" 167 "-" 168 "-" 169 "-" 170 "-" 171 "-" 172 "-" 173 "-" 174 "-" 175 "-" 176 "-" 177 "-" 178 "-" 179 "-" 180 "-" 181 "-" 182 "-" 183 "-" 184 "-" 185 "-" 186 "-" 187 "-" 188 "-" 189 "-" 190 "-" 191 "-" 192 "-" 193 "-" 194 "-" 195 "-" 196 "-" 197 "-" 198 "-" 199 "-" 200 "-" 201 "-" 202 "-" 203 "-" 204 "-" 205 "-" 206 "-" 207 "-" 208 "-" 209 "-" 210 "-" 211 "-" 212 "-" 213 "-" 214 "-" 215 "-" 216 "-" 217 "-" 218 "-" 219 "-" 220 "-" 221 "-" 222 "-" 223 "-" 224 "-" 225 "-" 226 "-" 227 "-" 228 "-" 229 "-" 230 "-" 231 "-" 232 "-" 233 "-" 234 "-" 235 "-" 236 "-" 237 "-" 238 "-" 239 "-" 240 "-" 241 "-" 242 "-" 243 "-" 244 "-" 245 "-" 246 "-" 247 "-" 248 "-" 249 "-" 250 "-" 251 "-" 252 "-" 253 "-" 254 "-" 255 "-" ;
VAL_ 3221225472 ABSD_Sta 0 "ABSD Function_is_off" 1 "ABSD Function_is_passive" 2 "ABSD_Function_active" 3 "ABSD_Function_failure" 4 "ABSD_Function Blockage" 5 "ABSD_Overtemperature" 6 "ABSD_Function minor failure" 7 "Reserved" ;
VAL_ 3221225472 ABSD_WrngSta 0 "ABSD Warning is Off" 1 "ABSD Left Warning is On" 2 "ABSD Right Warning is On" 3 "Reserved" ;
VAL_ 3221225472 ABSD_FLBrkCtrlReq 0 "Front left control off" 1 "Front left control on" 2 "Not used" 3 "Error Indicator" ;
VAL_ 3221225472 ABSD_FRBrkCtrlReq 0 "Front right control off" 1 "Front right control on" 2 "Not used" 3 "Error Indicator" ;
VAL_ 3221225472 ABSD_RLBrkCtrlReq 0 "Rear left control off" 1 "Rear left control on" 2 "Not used" 3 "Error Indicator" ;
VAL_ 3221225472 ABSD_RRBrkCtrlReq 0 "Rear right control off" 1 "Rear right control on" 2 "Not used" 3 "Error Indicator" ;
VAL_ 3221225472 ABSD_FrWhlTrgtBrkPrsrVal 0 "-" 1 "-" 2 "-" 3 "-" 4 "-" 5 "-" 6 "-" 7 "-" 8 "-" 9 "-" 10 "-" 11 "-" 12 "-" 13 "-" 14 "-" 15 "-" 16 "-" 17 "-" 18 "-" 19 "-" 20 "-" 21 "-" 22 "-" 23 "-" 24 "-" 25 "-" 26 "-" 27 "-" 28 "-" 29 "-" 30 "-" 31 "-" 32 "-" 33 "-" 34 "-" 35 "-" 36 "-" 37 "-" 38 "-" 39 "-" 40 "-" 41 "-" 42 "-" 43 "-" 44 "-" 45 "-" 46 "-" 47 "-" 48 "-" 49 "-" 50 "-" 51 "-" 52 "-" 53 "-" 54 "-" 55 "-" 56 "-" 57 "-" 58 "-" 59 "-" 60 "-" 61 "-" 62 "-" 63 "Error" ;
VAL_ 3221225472 ABSD_RrWhlTrgtBrkPrsrVal 0 "-" 1 "-" 2 "-" 3 "-" 4 "-" 5 "-" 6 "-" 7 "-" 8 "-" 9 "-" 10 "-" 11 "-" 12 "-" 13 "-" 14 "-" 15 "-" 16 "-" 17 "-" 18 "-" 19 "-" 20 "-" 21 "-" 22 "-" 23 "-" 24 "-" 25 "-" 26 "-" 27 "-" 28 "-" 29 "-" 30 "-" 31 "-" 32 "-" 33 "-" 34 "-" 35 "-" 36 "-" 37 "-" 38 "-" 39 "-" 40 "-" 41 "-" 42 "-" 43 "-" 44 "-" 45 "-" 46 "-" 47 "-" 48 "-" 49 "-" 50 "-" 51 "-" 52 "-" 53 "-" 54 "-" 55 "-" 56 "-" 57 "-" 58 "-" 59 "-" 60 "-" 61 "-" 62 "-" 63 "Error" ;
VAL_ 464 ECS_WrngLmpSta 0 "Off" 1 "On" 2 "Not used" 3 "Error Indicator" ;
VAL_ 464 ECS_DfctvSta 0 "ECS is not defective" 1 "ECS is defective" 2 "Not used" 3 "Error Indicator" ;
VAL_ 464 ECS_DiagSta 0 "ECS is not diagnosis states" 1 "ECS is diagnosis states" 2 "Not used" 3 "Error Indicator" ;
VAL_ 464 ECS_DmpModSta 0 "Auto" 1 "Soft" 2 "Hard" 3 "Reserved" 4 "Reserved" 5 "Reserved" 6 "Not used" 7 "Error Indicator" ;
VAL_ 464 ECS_DmpModReq 0 "Auto" 1 "Soft" 2 "Hard" 3 "Reserved" 4 "Reserved" 5 "Reserved" 6 "Not used" 7 "Error Indicator" ;
VAL_ 464 ECS_SysUnblSta 0 "System available" 1 "System temporary not available" 2 "Not used" 3 "Error Indicator" ;
VAL_ 330 ECS_ALS_FLHghtVal 254 "Not initialized" 255 "Error" ;
VAL_ 330 ECS_ALS_FRHghtVal 254 "Not initialized" 255 "Error" ;
VAL_ 330 ECS_ALS_RLHghtVal 254 "Not initialized" 255 "Error" ;
VAL_ 330 ECS_ALS_RRHghtVal 254 "Not initialized" 255 "Error" ;
VAL_ 330 ECS_ALS_HghtLvlChgUnblSta 0 "-" 1 "Height level change not available" 2 "Not used" 3 "Error Indicator" ;
VAL_ 330 ECS_ALS_LvlOffSta 0 "Leveling control active (normal)" 1 "Leveling control deactivated by user" 2 "Not used" 3 "Error Indicator" ;
VAL_ 330 ECS_ALS_LvlCtrlUnblOvhtSta 0 "Normal" 1 "System is overheated (cooling in progress)" 2 "Not used" 3 "Error Indicator" ;
VAL_ 330 ECS_ALS_LftngSta 0 "no change of level" 1 "raising" 2 "Not used" 3 "Error Indicator" ;
VAL_ 330 ECS_ALS_LwrngSta 0 "no change of level" 1 "lowering" 2 "Not used" 3 "Error Indicator" ;
VAL_ 330 ECS_ALS_HghtReq 0 "No Manual Switch input" 1 "Normal" 2 "High" 3 "Low" 4 "Reserved" 5 "Reserved" 6 "Not used" 7 "Error Indicator" ;
VAL_ 330 ECS_ALS_LvlReq 0 "Low" 1 "Highway" 2 "Normal" 3 "Off-road" 4 "High" 6 "Reserved" 7 "Reserved" 8 "Reserved" 9 "Reserved" 10 "Reserved" 11 "Reserved" 12 "Reserved" 13 "Reserved" 14 "Not used" 15 "Error Indicator" ;
VAL_ 330 ECS_ALS_ActlHghtSta 0 "Low" 1 "Highway" 2 "Normal" 3 "Off-road" 4 "High" 6 "Reserved" 7 "Reserved" 8 "Reserved" 9 "Reserved" 10 "Reserved" 11 "Reserved" 12 "Reserved" 13 "Reserved" 14 "Not used" 15 "Error Indicator" ;
VAL_ 330 ECS_ALS_SysUnblSta 0 "System available" 1 "System temporary not available" 2 "Not used" 3 "Error Indicator" ;
VAL_ 122 ECSIVSS_FLNmlCurrentVal 0 "0~100%" 1 "0~100%" 2 "0~100%" 3 "0~100%" 4 "0~100%" 5 "0~100%" 6 "0~100%" 7 "0~100%" 8 "0~100%" 9 "0~100%" 10 "0~100%" 11 "0~100%" 12 "0~100%" 13 "0~100%" 14 "0~100%" 15 "0~100%" 16 "0~100%" 17 "0~100%" 18 "0~100%" 19 "0~100%" 20 "0~100%" 21 "0~100%" 22 "0~100%" 23 "0~100%" 24 "0~100%" 25 "0~100%" 26 "0~100%" 27 "0~100%" 28 "0~100%" 29 "0~100%" 30 "0~100%" 31 "0~100%" 32 "0~100%" 33 "0~100%" 34 "0~100%" 35 "0~100%" 36 "0~100%" 37 "0~100%" 38 "0~100%" 39 "0~100%" 40 "0~100%" 41 "0~100%" 42 "0~100%" 43 "0~100%" 44 "0~100%" 45 "0~100%" 46 "0~100%" 47 "0~100%" 48 "0~100%" 49 "0~100%" 50 "0~100%" 51 "0~100%" 52 "0~100%" 53 "0~100%" 54 "0~100%" 55 "0~100%" 56 "0~100%" 57 "0~100%" 58 "0~100%" 59 "0~100%" 60 "0~100%" 61 "0~100%" 62 "0~100%" 63 "0~100%" 64 "0~100%" 65 "0~100%" 66 "0~100%" 67 "0~100%" 68 "0~100%" 69 "0~100%" 70 "0~100%" 71 "0~100%" 72 "0~100%" 73 "0~100%" 74 "0~100%" 75 "0~100%" 76 "0~100%" 77 "0~100%" 78 "0~100%" 79 "0~100%" 80 "0~100%" 81 "0~100%" 82 "0~100%" 83 "0~100%" 84 "0~100%" 85 "0~100%" 86 "0~100%" 87 "0~100%" 88 "0~100%" 89 "0~100%" 90 "0~100%" 91 "0~100%" 92 "0~100%" 93 "0~100%" 94 "0~100%" 95 "0~100%" 96 "0~100%" 97 "0~100%" 98 "0~100%" 99 "0~100%" 100 "0~100%" 101 "0~100%" 102 "0~100%" 103 "0~100%" 104 "0~100%" 105 "0~100%" 106 "0~100%" 107 "0~100%" 108 "0~100%" 109 "0~100%" 110 "0~100%" 111 "0~100%" 112 "0~100%" 113 "0~100%" 114 "0~100%" 115 "0~100%" 116 "0~100%" 117 "0~100%" 118 "0~100%" 119 "0~100%" 120 "0~100%" 121 "0~100%" 122 "0~100%" 123 "0~100%" 124 "0~100%" 125 "0~100%" 126 "0~100%" 127 "0~100%" 128 "0~100%" 129 "0~100%" 130 "0~100%" 131 "0~100%" 132 "0~100%" 133 "0~100%" 134 "0~100%" 135 "0~100%" 136 "0~100%" 137 "0~100%" 138 "0~100%" 139 "0~100%" 140 "0~100%" 141 "0~100%" 142 "0~100%" 143 "0~100%" 144 "0~100%" 145 "0~100%" 146 "0~100%" 147 "0~100%" 148 "0~100%" 149 "0~100%" 150 "0~100%" 151 "0~100%" 152 "0~100%" 153 "0~100%" 154 "0~100%" 155 "0~100%" 156 "0~100%" 157 "0~100%" 158 "0~100%" 159 "0~100%" 160 "0~100%" 161 "0~100%" 162 "0~100%" 163 "0~100%" 164 "0~100%" 165 "0~100%" 166 "0~100%" 167 "0~100%" 168 "0~100%" 169 "0~100%" 170 "0~100%" 171 "0~100%" 172 "0~100%" 173 "0~100%" 174 "0~100%" 175 "0~100%" 176 "0~100%" 177 "0~100%" 178 "0~100%" 179 "0~100%" 180 "0~100%" 181 "0~100%" 182 "0~100%" 183 "0~100%" 184 "0~100%" 185 "0~100%" 186 "0~100%" 187 "0~100%" 188 "0~100%" 189 "0~100%" 190 "0~100%" 191 "0~100%" 192 "0~100%" 193 "0~100%" 194 "0~100%" 195 "0~100%" 196 "0~100%" 197 "0~100%" 198 "0~100%" 199 "0~100%" 200 "0~100%" 201 "100%" 202 "100%" 203 "100%" 204 "100%" 205 "100%" 206 "100%" 207 "100%" 208 "100%" 209 "100%" 210 "100%" 211 "100%" 212 "100%" 213 "100%" 214 "100%" 215 "100%" 216 "100%" 217 "100%" 218 "100%" 219 "100%" 220 "100%" 221 "100%" 222 "100%" 223 "100%" 224 "100%" 225 "100%" 226 "100%" 227 "100%" 228 "100%" 229 "100%" 230 "100%" 231 "100%" 232 "100%" 233 "100%" 234 "100%" 235 "100%" 236 "100%" 237 "100%" 238 "100%" 239 "100%" 240 "100%" 241 "100%" 242 "100%" 243 "100%" 244 "100%" 245 "100%" 246 "100%" 247 "100%" 248 "100%" 249 "100%" 250 "100%" 251 "100%" 252 "100%" 253 "100%" 254 "Not used" 255 "Invalid" ;
VAL_ 122 ECSIVSS_FRNmlCurrentVal 0 "0~100%" 1 "0~100%" 2 "0~100%" 3 "0~100%" 4 "0~100%" 5 "0~100%" 6 "0~100%" 7 "0~100%" 8 "0~100%" 9 "0~100%" 10 "0~100%" 11 "0~100%" 12 "0~100%" 13 "0~100%" 14 "0~100%" 15 "0~100%" 16 "0~100%" 17 "0~100%" 18 "0~100%" 19 "0~100%" 20 "0~100%" 21 "0~100%" 22 "0~100%" 23 "0~100%" 24 "0~100%" 25 "0~100%" 26 "0~100%" 27 "0~100%" 28 "0~100%" 29 "0~100%" 30 "0~100%" 31 "0~100%" 32 "0~100%" 33 "0~100%" 34 "0~100%" 35 "0~100%" 36 "0~100%" 37 "0~100%" 38 "0~100%" 39 "0~100%" 40 "0~100%" 41 "0~100%" 42 "0~100%" 43 "0~100%" 44 "0~100%" 45 "0~100%" 46 "0~100%" 47 "0~100%" 48 "0~100%" 49 "0~100%" 50 "0~100%" 51 "0~100%" 52 "0~100%" 53 "0~100%" 54 "0~100%" 55 "0~100%" 56 "0~100%" 57 "0~100%" 58 "0~100%" 59 "0~100%" 60 "0~100%" 61 "0~100%" 62 "0~100%" 63 "0~100%" 64 "0~100%" 65 "0~100%" 66 "0~100%" 67 "0~100%" 68 "0~100%" 69 "0~100%" 70 "0~100%" 71 "0~100%" 72 "0~100%" 73 "0~100%" 74 "0~100%" 75 "0~100%" 76 "0~100%" 77 "0~100%" 78 "0~100%" 79 "0~100%" 80 "0~100%" 81 "0~100%" 82 "0~100%" 83 "0~100%" 84 "0~100%" 85 "0~100%" 86 "0~100%" 87 "0~100%" 88 "0~100%" 89 "0~100%" 90 "0~100%" 91 "0~100%" 92 "0~100%" 93 "0~100%" 94 "0~100%" 95 "0~100%" 96 "0~100%" 97 "0~100%" 98 "0~100%" 99 "0~100%" 100 "0~100%" 101 "0~100%" 102 "0~100%" 103 "0~100%" 104 "0~100%" 105 "0~100%" 106 "0~100%" 107 "0~100%" 108 "0~100%" 109 "0~100%" 110 "0~100%" 111 "0~100%" 112 "0~100%" 113 "0~100%" 114 "0~100%" 115 "0~100%" 116 "0~100%" 117 "0~100%" 118 "0~100%" 119 "0~100%" 120 "0~100%" 121 "0~100%" 122 "0~100%" 123 "0~100%" 124 "0~100%" 125 "0~100%" 126 "0~100%" 127 "0~100%" 128 "0~100%" 129 "0~100%" 130 "0~100%" 131 "0~100%" 132 "0~100%" 133 "0~100%" 134 "0~100%" 135 "0~100%" 136 "0~100%" 137 "0~100%" 138 "0~100%" 139 "0~100%" 140 "0~100%" 141 "0~100%" 142 "0~100%" 143 "0~100%" 144 "0~100%" 145 "0~100%" 146 "0~100%" 147 "0~100%" 148 "0~100%" 149 "0~100%" 150 "0~100%" 151 "0~100%" 152 "0~100%" 153 "0~100%" 154 "0~100%" 155 "0~100%" 156 "0~100%" 157 "0~100%" 158 "0~100%" 159 "0~100%" 160 "0~100%" 161 "0~100%" 162 "0~100%" 163 "0~100%" 164 "0~100%" 165 "0~100%" 166 "0~100%" 167 "0~100%" 168 "0~100%" 169 "0~100%" 170 "0~100%" 171 "0~100%" 172 "0~100%" 173 "0~100%" 174 "0~100%" 175 "0~100%" 176 "0~100%" 177 "0~100%" 178 "0~100%" 179 "0~100%" 180 "0~100%" 181 "0~100%" 182 "0~100%" 183 "0~100%" 184 "0~100%" 185 "0~100%" 186 "0~100%" 187 "0~100%" 188 "0~100%" 189 "0~100%" 190 "0~100%" 191 "0~100%" 192 "0~100%" 193 "0~100%" 194 "0~100%" 195 "0~100%" 196 "0~100%" 197 "0~100%" 198 "0~100%" 199 "0~100%" 200 "0~100%" 201 "100%" 202 "100%" 203 "100%" 204 "100%" 205 "100%" 206 "100%" 207 "100%" 208 "100%" 209 "100%" 210 "100%" 211 "100%" 212 "100%" 213 "100%" 214 "100%" 215 "100%" 216 "100%" 217 "100%" 218 "100%" 219 "100%" 220 "100%" 221 "100%" 222 "100%" 223 "100%" 224 "100%" 225 "100%" 226 "100%" 227 "100%" 228 "100%" 229 "100%" 230 "100%" 231 "100%" 232 "100%" 233 "100%" 234 "100%" 235 "100%" 236 "100%" 237 "100%" 238 "100%" 239 "100%" 240 "100%" 241 "100%" 242 "100%" 243 "100%" 244 "100%" 245 "100%" 246 "100%" 247 "100%" 248 "100%" 249 "100%" 250 "100%" 251 "100%" 252 "100%" 253 "100%" 254 "Not used" 255 "Invalid" ;
VAL_ 122 ECSIVSS_RLNmlCurrentVal 0 "0~100%" 1 "0~100%" 2 "0~100%" 3 "0~100%" 4 "0~100%" 5 "0~100%" 6 "0~100%" 7 "0~100%" 8 "0~100%" 9 "0~100%" 10 "0~100%" 11 "0~100%" 12 "0~100%" 13 "0~100%" 14 "0~100%" 15 "0~100%" 16 "0~100%" 17 "0~100%" 18 "0~100%" 19 "0~100%" 20 "0~100%" 21 "0~100%" 22 "0~100%" 23 "0~100%" 24 "0~100%" 25 "0~100%" 26 "0~100%" 27 "0~100%" 28 "0~100%" 29 "0~100%" 30 "0~100%" 31 "0~100%" 32 "0~100%" 33 "0~100%" 34 "0~100%" 35 "0~100%" 36 "0~100%" 37 "0~100%" 38 "0~100%" 39 "0~100%" 40 "0~100%" 41 "0~100%" 42 "0~100%" 43 "0~100%" 44 "0~100%" 45 "0~100%" 46 "0~100%" 47 "0~100%" 48 "0~100%" 49 "0~100%" 50 "0~100%" 51 "0~100%" 52 "0~100%" 53 "0~100%" 54 "0~100%" 55 "0~100%" 56 "0~100%" 57 "0~100%" 58 "0~100%" 59 "0~100%" 60 "0~100%" 61 "0~100%" 62 "0~100%" 63 "0~100%" 64 "0~100%" 65 "0~100%" 66 "0~100%" 67 "0~100%" 68 "0~100%" 69 "0~100%" 70 "0~100%" 71 "0~100%" 72 "0~100%" 73 "0~100%" 74 "0~100%" 75 "0~100%" 76 "0~100%" 77 "0~100%" 78 "0~100%" 79 "0~100%" 80 "0~100%" 81 "0~100%" 82 "0~100%" 83 "0~100%" 84 "0~100%" 85 "0~100%" 86 "0~100%" 87 "0~100%" 88 "0~100%" 89 "0~100%" 90 "0~100%" 91 "0~100%" 92 "0~100%" 93 "0~100%" 94 "0~100%" 95 "0~100%" 96 "0~100%" 97 "0~100%" 98 "0~100%" 99 "0~100%" 100 "0~100%" 101 "0~100%" 102 "0~100%" 103 "0~100%" 104 "0~100%" 105 "0~100%" 106 "0~100%" 107 "0~100%" 108 "0~100%" 109 "0~100%" 110 "0~100%" 111 "0~100%" 112 "0~100%" 113 "0~100%" 114 "0~100%" 115 "0~100%" 116 "0~100%" 117 "0~100%" 118 "0~100%" 119 "0~100%" 120 "0~100%" 121 "0~100%" 122 "0~100%" 123 "0~100%" 124 "0~100%" 125 "0~100%" 126 "0~100%" 127 "0~100%" 128 "0~100%" 129 "0~100%" 130 "0~100%" 131 "0~100%" 132 "0~100%" 133 "0~100%" 134 "0~100%" 135 "0~100%" 136 "0~100%" 137 "0~100%" 138 "0~100%" 139 "0~100%" 140 "0~100%" 141 "0~100%" 142 "0~100%" 143 "0~100%" 144 "0~100%" 145 "0~100%" 146 "0~100%" 147 "0~100%" 148 "0~100%" 149 "0~100%" 150 "0~100%" 151 "0~100%" 152 "0~100%" 153 "0~100%" 154 "0~100%" 155 "0~100%" 156 "0~100%" 157 "0~100%" 158 "0~100%" 159 "0~100%" 160 "0~100%" 161 "0~100%" 162 "0~100%" 163 "0~100%" 164 "0~100%" 165 "0~100%" 166 "0~100%" 167 "0~100%" 168 "0~100%" 169 "0~100%" 170 "0~100%" 171 "0~100%" 172 "0~100%" 173 "0~100%" 174 "0~100%" 175 "0~100%" 176 "0~100%" 177 "0~100%" 178 "0~100%" 179 "0~100%" 180 "0~100%" 181 "0~100%" 182 "0~100%" 183 "0~100%" 184 "0~100%" 185 "0~100%" 186 "0~100%" 187 "0~100%" 188 "0~100%" 189 "0~100%" 190 "0~100%" 191 "0~100%" 192 "0~100%" 193 "0~100%" 194 "0~100%" 195 "0~100%" 196 "0~100%" 197 "0~100%" 198 "0~100%" 199 "0~100%" 200 "0~100%" 201 "100%" 202 "100%" 203 "100%" 204 "100%" 205 "100%" 206 "100%" 207 "100%" 208 "100%" 209 "100%" 210 "100%" 211 "100%" 212 "100%" 213 "100%" 214 "100%" 215 "100%" 216 "100%" 217 "100%" 218 "100%" 219 "100%" 220 "100%" 221 "100%" 222 "100%" 223 "100%" 224 "100%" 225 "100%" 226 "100%" 227 "100%" 228 "100%" 229 "100%" 230 "100%" 231 "100%" 232 "100%" 233 "100%" 234 "100%" 235 "100%" 236 "100%" 237 "100%" 238 "100%" 239 "100%" 240 "100%" 241 "100%" 242 "100%" 243 "100%" 244 "100%" 245 "100%" 246 "100%" 247 "100%" 248 "100%" 249 "100%" 250 "100%" 251 "100%" 252 "100%" 253 "100%" 254 "Not used" 255 "Invalid" ;
VAL_ 122 ECSIVSS_RRNmlCurrentVal 0 "0~100%" 1 "0~100%" 2 "0~100%" 3 "0~100%" 4 "0~100%" 5 "0~100%" 6 "0~100%" 7 "0~100%" 8 "0~100%" 9 "0~100%" 10 "0~100%" 11 "0~100%" 12 "0~100%" 13 "0~100%" 14 "0~100%" 15 "0~100%" 16 "0~100%" 17 "0~100%" 18 "0~100%" 19 "0~100%" 20 "0~100%" 21 "0~100%" 22 "0~100%" 23 "0~100%" 24 "0~100%" 25 "0~100%" 26 "0~100%" 27 "0~100%" 28 "0~100%" 29 "0~100%" 30 "0~100%" 31 "0~100%" 32 "0~100%" 33 "0~100%" 34 "0~100%" 35 "0~100%" 36 "0~100%" 37 "0~100%" 38 "0~100%" 39 "0~100%" 40 "0~100%" 41 "0~100%" 42 "0~100%" 43 "0~100%" 44 "0~100%" 45 "0~100%" 46 "0~100%" 47 "0~100%" 48 "0~100%" 49 "0~100%" 50 "0~100%" 51 "0~100%" 52 "0~100%" 53 "0~100%" 54 "0~100%" 55 "0~100%" 56 "0~100%" 57 "0~100%" 58 "0~100%" 59 "0~100%" 60 "0~100%" 61 "0~100%" 62 "0~100%" 63 "0~100%" 64 "0~100%" 65 "0~100%" 66 "0~100%" 67 "0~100%" 68 "0~100%" 69 "0~100%" 70 "0~100%" 71 "0~100%" 72 "0~100%" 73 "0~100%" 74 "0~100%" 75 "0~100%" 76 "0~100%" 77 "0~100%" 78 "0~100%" 79 "0~100%" 80 "0~100%" 81 "0~100%" 82 "0~100%" 83 "0~100%" 84 "0~100%" 85 "0~100%" 86 "0~100%" 87 "0~100%" 88 "0~100%" 89 "0~100%" 90 "0~100%" 91 "0~100%" 92 "0~100%" 93 "0~100%" 94 "0~100%" 95 "0~100%" 96 "0~100%" 97 "0~100%" 98 "0~100%" 99 "0~100%" 100 "0~100%" 101 "0~100%" 102 "0~100%" 103 "0~100%" 104 "0~100%" 105 "0~100%" 106 "0~100%" 107 "0~100%" 108 "0~100%" 109 "0~100%" 110 "0~100%" 111 "0~100%" 112 "0~100%" 113 "0~100%" 114 "0~100%" 115 "0~100%" 116 "0~100%" 117 "0~100%" 118 "0~100%" 119 "0~100%" 120 "0~100%" 121 "0~100%" 122 "0~100%" 123 "0~100%" 124 "0~100%" 125 "0~100%" 126 "0~100%" 127 "0~100%" 128 "0~100%" 129 "0~100%" 130 "0~100%" 131 "0~100%" 132 "0~100%" 133 "0~100%" 134 "0~100%" 135 "0~100%" 136 "0~100%" 137 "0~100%" 138 "0~100%" 139 "0~100%" 140 "0~100%" 141 "0~100%" 142 "0~100%" 143 "0~100%" 144 "0~100%" 145 "0~100%" 146 "0~100%" 147 "0~100%" 148 "0~100%" 149 "0~100%" 150 "0~100%" 151 "0~100%" 152 "0~100%" 153 "0~100%" 154 "0~100%" 155 "0~100%" 156 "0~100%" 157 "0~100%" 158 "0~100%" 159 "0~100%" 160 "0~100%" 161 "0~100%" 162 "0~100%" 163 "0~100%" 164 "0~100%" 165 "0~100%" 166 "0~100%" 167 "0~100%" 168 "0~100%" 169 "0~100%" 170 "0~100%" 171 "0~100%" 172 "0~100%" 173 "0~100%" 174 "0~100%" 175 "0~100%" 176 "0~100%" 177 "0~100%" 178 "0~100%" 179 "0~100%" 180 "0~100%" 181 "0~100%" 182 "0~100%" 183 "0~100%" 184 "0~100%" 185 "0~100%" 186 "0~100%" 187 "0~100%" 188 "0~100%" 189 "0~100%" 190 "0~100%" 191 "0~100%" 192 "0~100%" 193 "0~100%" 194 "0~100%" 195 "0~100%" 196 "0~100%" 197 "0~100%" 198 "0~100%" 199 "0~100%" 200 "0~100%" 201 "100%" 202 "100%" 203 "100%" 204 "100%" 205 "100%" 206 "100%" 207 "100%" 208 "100%" 209 "100%" 210 "100%" 211 "100%" 212 "100%" 213 "100%" 214 "100%" 215 "100%" 216 "100%" 217 "100%" 218 "100%" 219 "100%" 220 "100%" 221 "100%" 222 "100%" 223 "100%" 224 "100%" 225 "100%" 226 "100%" 227 "100%" 228 "100%" 229 "100%" 230 "100%" 231 "100%" 232 "100%" 233 "100%" 234 "100%" 235 "100%" 236 "100%" 237 "100%" 238 "100%" 239 "100%" 240 "100%" 241 "100%" 242 "100%" 243 "100%" 244 "100%" 245 "100%" 246 "100%" 247 "100%" 248 "100%" 249 "100%" 250 "100%" 251 "100%" 252 "100%" 253 "100%" 254 "Not used" 255 "Invalid" ;
VAL_ 122 ECSIVSS_FLEstDmpVelVal 0 "-2048~2045 (mm/s)" 1 "-2048~2045 (mm/s)" 2 "-2048~2045 (mm/s)" 3 "-2048~2045 (mm/s)" 4 "-2048~2045 (mm/s)" 5 "-2048~2045 (mm/s)" 6 "-2048~2045 (mm/s)" 7 "-2048~2045 (mm/s)" 8 "-2048~2045 (mm/s)" 9 "-2048~2045 (mm/s)" 10 "-2048~2045 (mm/s)" 11 "-2048~2045 (mm/s)" 12 "-2048~2045 (mm/s)" 13 "-2048~2045 (mm/s)" 14 "-2048~2045 (mm/s)" 15 "-2048~2045 (mm/s)" 16 "-2048~2045 (mm/s)" 17 "-2048~2045 (mm/s)" 18 "-2048~2045 (mm/s)" 19 "-2048~2045 (mm/s)" 20 "-2048~2045 (mm/s)" 21 "-2048~2045 (mm/s)" 22 "-2048~2045 (mm/s)" 23 "-2048~2045 (mm/s)" 24 "-2048~2045 (mm/s)" 25 "-2048~2045 (mm/s)" 26 "-2048~2045 (mm/s)" 27 "-2048~2045 (mm/s)" 28 "-2048~2045 (mm/s)" 29 "-2048~2045 (mm/s)" 30 "-2048~2045 (mm/s)" 31 "-2048~2045 (mm/s)" 32 "-2048~2045 (mm/s)" 33 "-2048~2045 (mm/s)" 34 "-2048~2045 (mm/s)" 35 "-2048~2045 (mm/s)" 36 "-2048~2045 (mm/s)" 37 "-2048~2045 (mm/s)" 38 "-2048~2045 (mm/s)" 39 "-2048~2045 (mm/s)" 40 "-2048~2045 (mm/s)" 41 "-2048~2045 (mm/s)" 42 "-2048~2045 (mm/s)" 43 "-2048~2045 (mm/s)" 44 "-2048~2045 (mm/s)" 45 "-2048~2045 (mm/s)" 46 "-2048~2045 (mm/s)" 47 "-2048~2045 (mm/s)" 48 "-2048~2045 (mm/s)" 49 "-2048~2045 (mm/s)" 50 "-2048~2045 (mm/s)" 51 "-2048~2045 (mm/s)" 52 "-2048~2045 (mm/s)" 53 "-2048~2045 (mm/s)" 54 "-2048~2045 (mm/s)" 55 "-2048~2045 (mm/s)" 56 "-2048~2045 (mm/s)" 57 "-2048~2045 (mm/s)" 58 "-2048~2045 (mm/s)" 59 "-2048~2045 (mm/s)" 60 "-2048~2045 (mm/s)" 61 "-2048~2045 (mm/s)" 62 "-2048~2045 (mm/s)" 63 "-2048~2045 (mm/s)" 64 "-2048~2045 (mm/s)" 65 "-2048~2045 (mm/s)" 66 "-2048~2045 (mm/s)" 67 "-2048~2045 (mm/s)" 68 "-2048~2045 (mm/s)" 69 "-2048~2045 (mm/s)" 70 "-2048~2045 (mm/s)" 71 "-2048~2045 (mm/s)" 72 "-2048~2045 (mm/s)" 73 "-2048~2045 (mm/s)" 74 "-2048~2045 (mm/s)" 75 "-2048~2045 (mm/s)" 76 "-2048~2045 (mm/s)" 77 "-2048~2045 (mm/s)" 78 "-2048~2045 (mm/s)" 79 "-2048~2045 (mm/s)" 80 "-2048~2045 (mm/s)" 81 "-2048~2045 (mm/s)" 82 "-2048~2045 (mm/s)" 83 "-2048~2045 (mm/s)" 84 "-2048~2045 (mm/s)" 85 "-2048~2045 (mm/s)" 86 "-2048~2045 (mm/s)" 87 "-2048~2045 (mm/s)" 88 "-2048~2045 (mm/s)" 89 "-2048~2045 (mm/s)" 90 "-2048~2045 (mm/s)" 91 "-2048~2045 (mm/s)" 92 "-2048~2045 (mm/s)" 93 "-2048~2045 (mm/s)" 94 "-2048~2045 (mm/s)" 95 "-2048~2045 (mm/s)" 96 "-2048~2045 (mm/s)" 97 "-2048~2045 (mm/s)" 98 "-2048~2045 (mm/s)" 99 "-2048~2045 (mm/s)" 100 "-2048~2045 (mm/s)" 101 "-2048~2045 (mm/s)" 102 "-2048~2045 (mm/s)" 103 "-2048~2045 (mm/s)" 104 "-2048~2045 (mm/s)" 105 "-2048~2045 (mm/s)" 106 "-2048~2045 (mm/s)" 107 "-2048~2045 (mm/s)" 108 "-2048~2045 (mm/s)" 109 "-2048~2045 (mm/s)" 110 "-2048~2045 (mm/s)" 111 "-2048~2045 (mm/s)" 112 "-2048~2045 (mm/s)" 113 "-2048~2045 (mm/s)" 114 "-2048~2045 (mm/s)" 115 "-2048~2045 (mm/s)" 116 "-2048~2045 (mm/s)" 117 "-2048~2045 (mm/s)" 118 "-2048~2045 (mm/s)" 119 "-2048~2045 (mm/s)" 120 "-2048~2045 (mm/s)" 121 "-2048~2045 (mm/s)" 122 "-2048~2045 (mm/s)" 123 "-2048~2045 (mm/s)" 124 "-2048~2045 (mm/s)" 125 "-2048~2045 (mm/s)" 126 "-2048~2045 (mm/s)" 127 "-2048~2045 (mm/s)" 128 "-2048~2045 (mm/s)" 129 "-2048~2045 (mm/s)" 130 "-2048~2045 (mm/s)" 131 "-2048~2045 (mm/s)" 132 "-2048~2045 (mm/s)" 133 "-2048~2045 (mm/s)" 134 "-2048~2045 (mm/s)" 135 "-2048~2045 (mm/s)" 136 "-2048~2045 (mm/s)" 137 "-2048~2045 (mm/s)" 138 "-2048~2045 (mm/s)" 139 "-2048~2045 (mm/s)" 140 "-2048~2045 (mm/s)" 141 "-2048~2045 (mm/s)" 142 "-2048~2045 (mm/s)" 143 "-2048~2045 (mm/s)" 144 "-2048~2045 (mm/s)" 145 "-2048~2045 (mm/s)" 146 "-2048~2045 (mm/s)" 147 "-2048~2045 (mm/s)" 148 "-2048~2045 (mm/s)" 149 "-2048~2045 (mm/s)" 150 "-2048~2045 (mm/s)" 151 "-2048~2045 (mm/s)" 152 "-2048~2045 (mm/s)" 153 "-2048~2045 (mm/s)" 154 "-2048~2045 (mm/s)" 155 "-2048~2045 (mm/s)" 156 "-2048~2045 (mm/s)" 157 "-2048~2045 (mm/s)" 158 "-2048~2045 (mm/s)" 159 "-2048~2045 (mm/s)" 160 "-2048~2045 (mm/s)" 161 "-2048~2045 (mm/s)" 162 "-2048~2045 (mm/s)" 163 "-2048~2045 (mm/s)" 164 "-2048~2045 (mm/s)" 165 "-2048~2045 (mm/s)" 166 "-2048~2045 (mm/s)" 167 "-2048~2045 (mm/s)" 168 "-2048~2045 (mm/s)" 169 "-2048~2045 (mm/s)" 170 "-2048~2045 (mm/s)" 171 "-2048~2045 (mm/s)" 172 "-2048~2045 (mm/s)" 173 "-2048~2045 (mm/s)" 174 "-2048~2045 (mm/s)" 175 "-2048~2045 (mm/s)" 176 "-2048~2045 (mm/s)" 177 "-2048~2045 (mm/s)" 178 "-2048~2045 (mm/s)" 179 "-2048~2045 (mm/s)" 180 "-2048~2045 (mm/s)" 181 "-2048~2045 (mm/s)" 182 "-2048~2045 (mm/s)" 183 "-2048~2045 (mm/s)" 184 "-2048~2045 (mm/s)" 185 "-2048~2045 (mm/s)" 186 "-2048~2045 (mm/s)" 187 "-2048~2045 (mm/s)" 188 "-2048~2045 (mm/s)" 189 "-2048~2045 (mm/s)" 190 "-2048~2045 (mm/s)" 191 "-2048~2045 (mm/s)" 192 "-2048~2045 (mm/s)" 193 "-2048~2045 (mm/s)" 194 "-2048~2045 (mm/s)" 195 "-2048~2045 (mm/s)" 196 "-2048~2045 (mm/s)" 197 "-2048~2045 (mm/s)" 198 "-2048~2045 (mm/s)" 199 "-2048~2045 (mm/s)" 200 "-2048~2045 (mm/s)" 201 "-2048~2045 (mm/s)" 202 "-2048~2045 (mm/s)" 203 "-2048~2045 (mm/s)" 204 "-2048~2045 (mm/s)" 205 "-2048~2045 (mm/s)" 206 "-2048~2045 (mm/s)" 207 "-2048~2045 (mm/s)" 208 "-2048~2045 (mm/s)" 209 "-2048~2045 (mm/s)" 210 "-2048~2045 (mm/s)" 211 "-2048~2045 (mm/s)" 212 "-2048~2045 (mm/s)" 213 "-2048~2045 (mm/s)" 214 "-2048~2045 (mm/s)" 215 "-2048~2045 (mm/s)" 216 "-2048~2045 (mm/s)" 217 "-2048~2045 (mm/s)" 218 "-2048~2045 (mm/s)" 219 "-2048~2045 (mm/s)" 220 "-2048~2045 (mm/s)" 221 "-2048~2045 (mm/s)" 222 "-2048~2045 (mm/s)" 223 "-2048~2045 (mm/s)" 224 "-2048~2045 (mm/s)" 225 "-2048~2045 (mm/s)" 226 "-2048~2045 (mm/s)" 227 "-2048~2045 (mm/s)" 228 "-2048~2045 (mm/s)" 229 "-2048~2045 (mm/s)" 230 "-2048~2045 (mm/s)" 231 "-2048~2045 (mm/s)" 232 "-2048~2045 (mm/s)" 233 "-2048~2045 (mm/s)" 234 "-2048~2045 (mm/s)" 235 "-2048~2045 (mm/s)" 236 "-2048~2045 (mm/s)" 237 "-2048~2045 (mm/s)" 238 "-2048~2045 (mm/s)" 239 "-2048~2045 (mm/s)" 240 "-2048~2045 (mm/s)" 241 "-2048~2045 (mm/s)" 242 "-2048~2045 (mm/s)" 243 "-2048~2045 (mm/s)" 244 "-2048~2045 (mm/s)" 245 "-2048~2045 (mm/s)" 246 "-2048~2045 (mm/s)" 247 "-2048~2045 (mm/s)" 248 "-2048~2045 (mm/s)" 249 "-2048~2045 (mm/s)" 250 "-2048~2045 (mm/s)" 251 "-2048~2045 (mm/s)" 252 "-2048~2045 (mm/s)" 253 "-2048~2045 (mm/s)" 254 "-2048~2045 (mm/s)" 255 "-2048~2045 (mm/s)" 256 "-2048~2045 (mm/s)" 257 "-2048~2045 (mm/s)" 258 "-2048~2045 (mm/s)" 259 "-2048~2045 (mm/s)" 260 "-2048~2045 (mm/s)" 261 "-2048~2045 (mm/s)" 262 "-2048~2045 (mm/s)" 263 "-2048~2045 (mm/s)" 264 "-2048~2045 (mm/s)" 265 "-2048~2045 (mm/s)" 266 "-2048~2045 (mm/s)" 267 "-2048~2045 (mm/s)" 268 "-2048~2045 (mm/s)" 269 "-2048~2045 (mm/s)" 270 "-2048~2045 (mm/s)" 271 "-2048~2045 (mm/s)" 272 "-2048~2045 (mm/s)" 273 "-2048~2045 (mm/s)" 274 "-2048~2045 (mm/s)" 275 "-2048~2045 (mm/s)" 276 "-2048~2045 (mm/s)" 277 "-2048~2045 (mm/s)" 278 "-2048~2045 (mm/s)" 279 "-2048~2045 (mm/s)" 280 "-2048~2045 (mm/s)" 281 "-2048~2045 (mm/s)" 282 "-2048~2045 (mm/s)" 283 "-2048~2045 (mm/s)" 284 "-2048~2045 (mm/s)" 285 "-2048~2045 (mm/s)" 286 "-2048~2045 (mm/s)" 287 "-2048~2045 (mm/s)" 288 "-2048~2045 (mm/s)" 289 "-2048~2045 (mm/s)" 290 "-2048~2045 (mm/s)" 291 "-2048~2045 (mm/s)" 292 "-2048~2045 (mm/s)" 293 "-2048~2045 (mm/s)" 294 "-2048~2045 (mm/s)" 295 "-2048~2045 (mm/s)" 296 "-2048~2045 (mm/s)" 297 "-2048~2045 (mm/s)" 298 "-2048~2045 (mm/s)" 299 "-2048~2045 (mm/s)" 300 "-2048~2045 (mm/s)" 301 "-2048~2045 (mm/s)" 302 "-2048~2045 (mm/s)" 303 "-2048~2045 (mm/s)" 304 "-2048~2045 (mm/s)" 305 "-2048~2045 (mm/s)" 306 "-2048~2045 (mm/s)" 307 "-2048~2045 (mm/s)" 308 "-2048~2045 (mm/s)" 309 "-2048~2045 (mm/s)" 310 "-2048~2045 (mm/s)" 311 "-2048~2045 (mm/s)" 312 "-2048~2045 (mm/s)" 313 "-2048~2045 (mm/s)" 314 "-2048~2045 (mm/s)" 315 "-2048~2045 (mm/s)" 316 "-2048~2045 (mm/s)" 317 "-2048~2045 (mm/s)" 318 "-2048~2045 (mm/s)" 319 "-2048~2045 (mm/s)" 320 "-2048~2045 (mm/s)" 321 "-2048~2045 (mm/s)" 322 "-2048~2045 (mm/s)" 323 "-2048~2045 (mm/s)" 324 "-2048~2045 (mm/s)" 325 "-2048~2045 (mm/s)" 326 "-2048~2045 (mm/s)" 327 "-2048~2045 (mm/s)" 328 "-2048~2045 (mm/s)" 329 "-2048~2045 (mm/s)" 330 "-2048~2045 (mm/s)" 331 "-2048~2045 (mm/s)" 332 "-2048~2045 (mm/s)" 333 "-2048~2045 (mm/s)" 334 "-2048~2045 (mm/s)" 335 "-2048~2045 (mm/s)" 336 "-2048~2045 (mm/s)" 337 "-2048~2045 (mm/s)" 338 "-2048~2045 (mm/s)" 339 "-2048~2045 (mm/s)" 340 "-2048~2045 (mm/s)" 341 "-2048~2045 (mm/s)" 342 "-2048~2045 (mm/s)" 343 "-2048~2045 (mm/s)" 344 "-2048~2045 (mm/s)" 345 "-2048~2045 (mm/s)" 346 "-2048~2045 (mm/s)" 347 "-2048~2045 (mm/s)" 348 "-2048~2045 (mm/s)" 349 "-2048~2045 (mm/s)" 350 "-2048~2045 (mm/s)" 351 "-2048~2045 (mm/s)" 352 "-2048~2045 (mm/s)" 353 "-2048~2045 (mm/s)" 354 "-2048~2045 (mm/s)" 355 "-2048~2045 (mm/s)" 356 "-2048~2045 (mm/s)" 357 "-2048~2045 (mm/s)" 358 "-2048~2045 (mm/s)" 359 "-2048~2045 (mm/s)" 360 "-2048~2045 (mm/s)" 361 "-2048~2045 (mm/s)" 362 "-2048~2045 (mm/s)" 363 "-2048~2045 (mm/s)" 364 "-2048~2045 (mm/s)" 365 "-2048~2045 (mm/s)" 366 "-2048~2045 (mm/s)" 367 "-2048~2045 (mm/s)" 368 "-2048~2045 (mm/s)" 369 "-2048~2045 (mm/s)" 370 "-2048~2045 (mm/s)" 371 "-2048~2045 (mm/s)" 372 "-2048~2045 (mm/s)" 373 "-2048~2045 (mm/s)" 374 "-2048~2045 (mm/s)" 375 "-2048~2045 (mm/s)" 376 "-2048~2045 (mm/s)" 377 "-2048~2045 (mm/s)" 378 "-2048~2045 (mm/s)" 379 "-2048~2045 (mm/s)" 380 "-2048~2045 (mm/s)" 381 "-2048~2045 (mm/s)" 382 "-2048~2045 (mm/s)" 383 "-2048~2045 (mm/s)" 384 "-2048~2045 (mm/s)" 385 "-2048~2045 (mm/s)" 386 "-2048~2045 (mm/s)" 387 "-2048~2045 (mm/s)" 388 "-2048~2045 (mm/s)" 389 "-2048~2045 (mm/s)" 390 "-2048~2045 (mm/s)" 391 "-2048~2045 (mm/s)" 392 "-2048~2045 (mm/s)" 393 "-2048~2045 (mm/s)" 394 "-2048~2045 (mm/s)" 395 "-2048~2045 (mm/s)" 396 "-2048~2045 (mm/s)" 397 "-2048~2045 (mm/s)" 398 "-2048~2045 (mm/s)" 399 "-2048~2045 (mm/s)" 400 "-2048~2045 (mm/s)" 401 "-2048~2045 (mm/s)" 402 "-2048~2045 (mm/s)" 403 "-2048~2045 (mm/s)" 404 "-2048~2045 (mm/s)" 405 "-2048~2045 (mm/s)" 406 "-2048~2045 (mm/s)" 407 "-2048~2045 (mm/s)" 408 "-2048~2045 (mm/s)" 409 "-2048~2045 (mm/s)" 410 "-2048~2045 (mm/s)" 411 "-2048~2045 (mm/s)" 412 "-2048~2045 (mm/s)" 413 "-2048~2045 (mm/s)" 414 "-2048~2045 (mm/s)" 415 "-2048~2045 (mm/s)" 416 "-2048~2045 (mm/s)" 417 "-2048~2045 (mm/s)" 418 "-2048~2045 (mm/s)" 419 "-2048~2045 (mm/s)" 420 "-2048~2045 (mm/s)" 421 "-2048~2045 (mm/s)" 422 "-2048~2045 (mm/s)" 423 "-2048~2045 (mm/s)" 424 "-2048~2045 (mm/s)" 425 "-2048~2045 (mm/s)" 426 "-2048~2045 (mm/s)" 427 "-2048~2045 (mm/s)" 428 "-2048~2045 (mm/s)" 429 "-2048~2045 (mm/s)" 430 "-2048~2045 (mm/s)" 431 "-2048~2045 (mm/s)" 432 "-2048~2045 (mm/s)" 433 "-2048~2045 (mm/s)" 434 "-2048~2045 (mm/s)" 435 "-2048~2045 (mm/s)" 436 "-2048~2045 (mm/s)" 437 "-2048~2045 (mm/s)" 438 "-2048~2045 (mm/s)" 439 "-2048~2045 (mm/s)" 440 "-2048~2045 (mm/s)" 441 "-2048~2045 (mm/s)" 442 "-2048~2045 (mm/s)" 443 "-2048~2045 (mm/s)" 444 "-2048~2045 (mm/s)" 445 "-2048~2045 (mm/s)" 446 "-2048~2045 (mm/s)" 447 "-2048~2045 (mm/s)" 448 "-2048~2045 (mm/s)" 449 "-2048~2045 (mm/s)" 450 "-2048~2045 (mm/s)" 451 "-2048~2045 (mm/s)" 452 "-2048~2045 (mm/s)" 453 "-2048~2045 (mm/s)" 454 "-2048~2045 (mm/s)" 455 "-2048~2045 (mm/s)" 456 "-2048~2045 (mm/s)" 457 "-2048~2045 (mm/s)" 458 "-2048~2045 (mm/s)" 459 "-2048~2045 (mm/s)" 460 "-2048~2045 (mm/s)" 461 "-2048~2045 (mm/s)" 462 "-2048~2045 (mm/s)" 463 "-2048~2045 (mm/s)" 464 "-2048~2045 (mm/s)" 465 "-2048~2045 (mm/s)" 466 "-2048~2045 (mm/s)" 467 "-2048~2045 (mm/s)" 468 "-2048~2045 (mm/s)" 469 "-2048~2045 (mm/s)" 470 "-2048~2045 (mm/s)" 471 "-2048~2045 (mm/s)" 472 "-2048~2045 (mm/s)" 473 "-2048~2045 (mm/s)" 474 "-2048~2045 (mm/s)" 475 "-2048~2045 (mm/s)" 476 "-2048~2045 (mm/s)" 477 "-2048~2045 (mm/s)" 478 "-2048~2045 (mm/s)" 479 "-2048~2045 (mm/s)" 480 "-2048~2045 (mm/s)" 481 "-2048~2045 (mm/s)" 482 "-2048~2045 (mm/s)" 483 "-2048~2045 (mm/s)" 484 "-2048~2045 (mm/s)" 485 "-2048~2045 (mm/s)" 486 "-2048~2045 (mm/s)" 487 "-2048~2045 (mm/s)" 488 "-2048~2045 (mm/s)" 489 "-2048~2045 (mm/s)" 490 "-2048~2045 (mm/s)" 491 "-2048~2045 (mm/s)" 492 "-2048~2045 (mm/s)" 493 "-2048~2045 (mm/s)" 494 "-2048~2045 (mm/s)" 495 "-2048~2045 (mm/s)" 496 "-2048~2045 (mm/s)" 497 "-2048~2045 (mm/s)" 498 "-2048~2045 (mm/s)" 499 "-2048~2045 (mm/s)" 500 "-2048~2045 (mm/s)" 501 "-2048~2045 (mm/s)" 502 "-2048~2045 (mm/s)" 503 "-2048~2045 (mm/s)" 504 "-2048~2045 (mm/s)" 505 "-2048~2045 (mm/s)" 506 "-2048~2045 (mm/s)" 507 "-2048~2045 (mm/s)" 508 "-2048~2045 (mm/s)" 509 "-2048~2045 (mm/s)" 510 "-2048~2045 (mm/s)" 511 "-2048~2045 (mm/s)" 512 "-2048~2045 (mm/s)" 513 "-2048~2045 (mm/s)" 514 "-2048~2045 (mm/s)" 515 "-2048~2045 (mm/s)" 516 "-2048~2045 (mm/s)" 517 "-2048~2045 (mm/s)" 518 "-2048~2045 (mm/s)" 519 "-2048~2045 (mm/s)" 520 "-2048~2045 (mm/s)" 521 "-2048~2045 (mm/s)" 522 "-2048~2045 (mm/s)" 523 "-2048~2045 (mm/s)" 524 "-2048~2045 (mm/s)" 525 "-2048~2045 (mm/s)" 526 "-2048~2045 (mm/s)" 527 "-2048~2045 (mm/s)" 528 "-2048~2045 (mm/s)" 529 "-2048~2045 (mm/s)" 530 "-2048~2045 (mm/s)" 531 "-2048~2045 (mm/s)" 532 "-2048~2045 (mm/s)" 533 "-2048~2045 (mm/s)" 534 "-2048~2045 (mm/s)" 535 "-2048~2045 (mm/s)" 536 "-2048~2045 (mm/s)" 537 "-2048~2045 (mm/s)" 538 "-2048~2045 (mm/s)" 539 "-2048~2045 (mm/s)" 540 "-2048~2045 (mm/s)" 541 "-2048~2045 (mm/s)" 542 "-2048~2045 (mm/s)" 543 "-2048~2045 (mm/s)" 544 "-2048~2045 (mm/s)" 545 "-2048~2045 (mm/s)" 546 "-2048~2045 (mm/s)" 547 "-2048~2045 (mm/s)" 548 "-2048~2045 (mm/s)" 549 "-2048~2045 (mm/s)" 550 "-2048~2045 (mm/s)" 551 "-2048~2045 (mm/s)" 552 "-2048~2045 (mm/s)" 553 "-2048~2045 (mm/s)" 554 "-2048~2045 (mm/s)" 555 "-2048~2045 (mm/s)" 556 "-2048~2045 (mm/s)" 557 "-2048~2045 (mm/s)" 558 "-2048~2045 (mm/s)" 559 "-2048~2045 (mm/s)" 560 "-2048~2045 (mm/s)" 561 "-2048~2045 (mm/s)" 562 "-2048~2045 (mm/s)" 563 "-2048~2045 (mm/s)" 564 "-2048~2045 (mm/s)" 565 "-2048~2045 (mm/s)" 566 "-2048~2045 (mm/s)" 567 "-2048~2045 (mm/s)" 568 "-2048~2045 (mm/s)" 569 "-2048~2045 (mm/s)" 570 "-2048~2045 (mm/s)" 571 "-2048~2045 (mm/s)" 572 "-2048~2045 (mm/s)" 573 "-2048~2045 (mm/s)" 574 "-2048~2045 (mm/s)" 575 "-2048~2045 (mm/s)" 576 "-2048~2045 (mm/s)" 577 "-2048~2045 (mm/s)" 578 "-2048~2045 (mm/s)" 579 "-2048~2045 (mm/s)" 580 "-2048~2045 (mm/s)" 581 "-2048~2045 (mm/s)" 582 "-2048~2045 (mm/s)" 583 "-2048~2045 (mm/s)" 584 "-2048~2045 (mm/s)" 585 "-2048~2045 (mm/s)" 586 "-2048~2045 (mm/s)" 587 "-2048~2045 (mm/s)" 588 "-2048~2045 (mm/s)" 589 "-2048~2045 (mm/s)" 590 "-2048~2045 (mm/s)" 591 "-2048~2045 (mm/s)" 592 "-2048~2045 (mm/s)" 593 "-2048~2045 (mm/s)" 594 "-2048~2045 (mm/s)" 595 "-2048~2045 (mm/s)" 596 "-2048~2045 (mm/s)" 597 "-2048~2045 (mm/s)" 598 "-2048~2045 (mm/s)" 599 "-2048~2045 (mm/s)" 600 "-2048~2045 (mm/s)" 601 "-2048~2045 (mm/s)" 602 "-2048~2045 (mm/s)" 603 "-2048~2045 (mm/s)" 604 "-2048~2045 (mm/s)" 605 "-2048~2045 (mm/s)" 606 "-2048~2045 (mm/s)" 607 "-2048~2045 (mm/s)" 608 "-2048~2045 (mm/s)" 609 "-2048~2045 (mm/s)" 610 "-2048~2045 (mm/s)" 611 "-2048~2045 (mm/s)" 612 "-2048~2045 (mm/s)" 613 "-2048~2045 (mm/s)" 614 "-2048~2045 (mm/s)" 615 "-2048~2045 (mm/s)" 616 "-2048~2045 (mm/s)" 617 "-2048~2045 (mm/s)" 618 "-2048~2045 (mm/s)" 619 "-2048~2045 (mm/s)" 620 "-2048~2045 (mm/s)" 621 "-2048~2045 (mm/s)" 622 "-2048~2045 (mm/s)" 623 "-2048~2045 (mm/s)" 624 "-2048~2045 (mm/s)" 625 "-2048~2045 (mm/s)" 626 "-2048~2045 (mm/s)" 627 "-2048~2045 (mm/s)" 628 "-2048~2045 (mm/s)" 629 "-2048~2045 (mm/s)" 630 "-2048~2045 (mm/s)" 631 "-2048~2045 (mm/s)" 632 "-2048~2045 (mm/s)" 633 "-2048~2045 (mm/s)" 634 "-2048~2045 (mm/s)" 635 "-2048~2045 (mm/s)" 636 "-2048~2045 (mm/s)" 637 "-2048~2045 (mm/s)" 638 "-2048~2045 (mm/s)" 639 "-2048~2045 (mm/s)" 640 "-2048~2045 (mm/s)" 641 "-2048~2045 (mm/s)" 642 "-2048~2045 (mm/s)" 643 "-2048~2045 (mm/s)" 644 "-2048~2045 (mm/s)" 645 "-2048~2045 (mm/s)" 646 "-2048~2045 (mm/s)" 647 "-2048~2045 (mm/s)" 648 "-2048~2045 (mm/s)" 649 "-2048~2045 (mm/s)" 650 "-2048~2045 (mm/s)" 651 "-2048~2045 (mm/s)" 652 "-2048~2045 (mm/s)" 653 "-2048~2045 (mm/s)" 654 "-2048~2045 (mm/s)" 655 "-2048~2045 (mm/s)" 656 "-2048~2045 (mm/s)" 657 "-2048~2045 (mm/s)" 658 "-2048~2045 (mm/s)" 659 "-2048~2045 (mm/s)" 660 "-2048~2045 (mm/s)" 661 "-2048~2045 (mm/s)" 662 "-2048~2045 (mm/s)" 663 "-2048~2045 (mm/s)" 664 "-2048~2045 (mm/s)" 665 "-2048~2045 (mm/s)" 666 "-2048~2045 (mm/s)" 667 "-2048~2045 (mm/s)" 668 "-2048~2045 (mm/s)" 669 "-2048~2045 (mm/s)" 670 "-2048~2045 (mm/s)" 671 "-2048~2045 (mm/s)" 672 "-2048~2045 (mm/s)" 673 "-2048~2045 (mm/s)" 674 "-2048~2045 (mm/s)" 675 "-2048~2045 (mm/s)" 676 "-2048~2045 (mm/s)" 677 "-2048~2045 (mm/s)" 678 "-2048~2045 (mm/s)" 679 "-2048~2045 (mm/s)" 680 "-2048~2045 (mm/s)" 681 "-2048~2045 (mm/s)" 682 "-2048~2045 (mm/s)" 683 "-2048~2045 (mm/s)" 684 "-2048~2045 (mm/s)" 685 "-2048~2045 (mm/s)" 686 "-2048~2045 (mm/s)" 687 "-2048~2045 (mm/s)" 688 "-2048~2045 (mm/s)" 689 "-2048~2045 (mm/s)" 690 "-2048~2045 (mm/s)" 691 "-2048~2045 (mm/s)" 692 "-2048~2045 (mm/s)" 693 "-2048~2045 (mm/s)" 694 "-2048~2045 (mm/s)" 695 "-2048~2045 (mm/s)" 696 "-2048~2045 (mm/s)" 697 "-2048~2045 (mm/s)" 698 "-2048~2045 (mm/s)" 699 "-2048~2045 (mm/s)" 700 "-2048~2045 (mm/s)" 701 "-2048~2045 (mm/s)" 702 "-2048~2045 (mm/s)" 703 "-2048~2045 (mm/s)" 704 "-2048~2045 (mm/s)" 705 "-2048~2045 (mm/s)" 706 "-2048~2045 (mm/s)" 707 "-2048~2045 (mm/s)" 708 "-2048~2045 (mm/s)" 709 "-2048~2045 (mm/s)" 710 "-2048~2045 (mm/s)" 711 "-2048~2045 (mm/s)" 712 "-2048~2045 (mm/s)" 713 "-2048~2045 (mm/s)" 714 "-2048~2045 (mm/s)" 715 "-2048~2045 (mm/s)" 716 "-2048~2045 (mm/s)" 717 "-2048~2045 (mm/s)" 718 "-2048~2045 (mm/s)" 719 "-2048~2045 (mm/s)" 720 "-2048~2045 (mm/s)" 721 "-2048~2045 (mm/s)" 722 "-2048~2045 (mm/s)" 723 "-2048~2045 (mm/s)" 724 "-2048~2045 (mm/s)" 725 "-2048~2045 (mm/s)" 726 "-2048~2045 (mm/s)" 727 "-2048~2045 (mm/s)" 728 "-2048~2045 (mm/s)" 729 "-2048~2045 (mm/s)" 730 "-2048~2045 (mm/s)" 731 "-2048~2045 (mm/s)" 732 "-2048~2045 (mm/s)" 733 "-2048~2045 (mm/s)" 734 "-2048~2045 (mm/s)" 735 "-2048~2045 (mm/s)" 736 "-2048~2045 (mm/s)" 737 "-2048~2045 (mm/s)" 738 "-2048~2045 (mm/s)" 739 "-2048~2045 (mm/s)" 740 "-2048~2045 (mm/s)" 741 "-2048~2045 (mm/s)" 742 "-2048~2045 (mm/s)" 743 "-2048~2045 (mm/s)" 744 "-2048~2045 (mm/s)" 745 "-2048~2045 (mm/s)" 746 "-2048~2045 (mm/s)" 747 "-2048~2045 (mm/s)" 748 "-2048~2045 (mm/s)" 749 "-2048~2045 (mm/s)" 750 "-2048~2045 (mm/s)" 751 "-2048~2045 (mm/s)" 752 "-2048~2045 (mm/s)" 753 "-2048~2045 (mm/s)" 754 "-2048~2045 (mm/s)" 755 "-2048~2045 (mm/s)" 756 "-2048~2045 (mm/s)" 757 "-2048~2045 (mm/s)" 758 "-2048~2045 (mm/s)" 759 "-2048~2045 (mm/s)" 760 "-2048~2045 (mm/s)" 761 "-2048~2045 (mm/s)" 762 "-2048~2045 (mm/s)" 763 "-2048~2045 (mm/s)" 764 "-2048~2045 (mm/s)" 765 "-2048~2045 (mm/s)" 766 "-2048~2045 (mm/s)" 767 "-2048~2045 (mm/s)" 768 "-2048~2045 (mm/s)" 769 "-2048~2045 (mm/s)" 770 "-2048~2045 (mm/s)" 771 "-2048~2045 (mm/s)" 772 "-2048~2045 (mm/s)" 773 "-2048~2045 (mm/s)" 774 "-2048~2045 (mm/s)" 775 "-2048~2045 (mm/s)" 776 "-2048~2045 (mm/s)" 777 "-2048~2045 (mm/s)" 778 "-2048~2045 (mm/s)" 779 "-2048~2045 (mm/s)" 780 "-2048~2045 (mm/s)" 781 "-2048~2045 (mm/s)" 782 "-2048~2045 (mm/s)" 783 "-2048~2045 (mm/s)" 784 "-2048~2045 (mm/s)" 785 "-2048~2045 (mm/s)" 786 "-2048~2045 (mm/s)" 787 "-2048~2045 (mm/s)" 788 "-2048~2045 (mm/s)" 789 "-2048~2045 (mm/s)" 790 "-2048~2045 (mm/s)" 791 "-2048~2045 (mm/s)" 792 "-2048~2045 (mm/s)" 793 "-2048~2045 (mm/s)" 794 "-2048~2045 (mm/s)" 795 "-2048~2045 (mm/s)" 796 "-2048~2045 (mm/s)" 797 "-2048~2045 (mm/s)" 798 "-2048~2045 (mm/s)" 799 "-2048~2045 (mm/s)" 800 "-2048~2045 (mm/s)" 801 "-2048~2045 (mm/s)" 802 "-2048~2045 (mm/s)" 803 "-2048~2045 (mm/s)" 804 "-2048~2045 (mm/s)" 805 "-2048~2045 (mm/s)" 806 "-2048~2045 (mm/s)" 807 "-2048~2045 (mm/s)" 808 "-2048~2045 (mm/s)" 809 "-2048~2045 (mm/s)" 810 "-2048~2045 (mm/s)" 811 "-2048~2045 (mm/s)" 812 "-2048~2045 (mm/s)" 813 "-2048~2045 (mm/s)" 814 "-2048~2045 (mm/s)" 815 "-2048~2045 (mm/s)" 816 "-2048~2045 (mm/s)" 817 "-2048~2045 (mm/s)" 818 "-2048~2045 (mm/s)" 819 "-2048~2045 (mm/s)" 820 "-2048~2045 (mm/s)" 821 "-2048~2045 (mm/s)" 822 "-2048~2045 (mm/s)" 823 "-2048~2045 (mm/s)" 824 "-2048~2045 (mm/s)" 825 "-2048~2045 (mm/s)" 826 "-2048~2045 (mm/s)" 827 "-2048~2045 (mm/s)" 828 "-2048~2045 (mm/s)" 829 "-2048~2045 (mm/s)" 830 "-2048~2045 (mm/s)" 831 "-2048~2045 (mm/s)" 832 "-2048~2045 (mm/s)" 833 "-2048~2045 (mm/s)" 834 "-2048~2045 (mm/s)" 835 "-2048~2045 (mm/s)" 836 "-2048~2045 (mm/s)" 837 "-2048~2045 (mm/s)" 838 "-2048~2045 (mm/s)" 839 "-2048~2045 (mm/s)" 840 "-2048~2045 (mm/s)" 841 "-2048~2045 (mm/s)" 842 "-2048~2045 (mm/s)" 843 "-2048~2045 (mm/s)" 844 "-2048~2045 (mm/s)" 845 "-2048~2045 (mm/s)" 846 "-2048~2045 (mm/s)" 847 "-2048~2045 (mm/s)" 848 "-2048~2045 (mm/s)" 849 "-2048~2045 (mm/s)" 850 "-2048~2045 (mm/s)" 851 "-2048~2045 (mm/s)" 852 "-2048~2045 (mm/s)" 853 "-2048~2045 (mm/s)" 854 "-2048~2045 (mm/s)" 855 "-2048~2045 (mm/s)" 856 "-2048~2045 (mm/s)" 857 "-2048~2045 (mm/s)" 858 "-2048~2045 (mm/s)" 859 "-2048~2045 (mm/s)" 860 "-2048~2045 (mm/s)" 861 "-2048~2045 (mm/s)" 862 "-2048~2045 (mm/s)" 863 "-2048~2045 (mm/s)" 864 "-2048~2045 (mm/s)" 865 "-2048~2045 (mm/s)" 866 "-2048~2045 (mm/s)" 867 "-2048~2045 (mm/s)" 868 "-2048~2045 (mm/s)" 869 "-2048~2045 (mm/s)" 870 "-2048~2045 (mm/s)" 871 "-2048~2045 (mm/s)" 872 "-2048~2045 (mm/s)" 873 "-2048~2045 (mm/s)" 874 "-2048~2045 (mm/s)" 875 "-2048~2045 (mm/s)" 876 "-2048~2045 (mm/s)" 877 "-2048~2045 (mm/s)" 878 "-2048~2045 (mm/s)" 879 "-2048~2045 (mm/s)" 880 "-2048~2045 (mm/s)" 881 "-2048~2045 (mm/s)" 882 "-2048~2045 (mm/s)" 883 "-2048~2045 (mm/s)" 884 "-2048~2045 (mm/s)" 885 "-2048~2045 (mm/s)" 886 "-2048~2045 (mm/s)" 887 "-2048~2045 (mm/s)" 888 "-2048~2045 (mm/s)" 889 "-2048~2045 (mm/s)" 890 "-2048~2045 (mm/s)" 891 "-2048~2045 (mm/s)" 892 "-2048~2045 (mm/s)" 893 "-2048~2045 (mm/s)" 894 "-2048~2045 (mm/s)" 895 "-2048~2045 (mm/s)" 896 "-2048~2045 (mm/s)" 897 "-2048~2045 (mm/s)" 898 "-2048~2045 (mm/s)" 899 "-2048~2045 (mm/s)" 900 "-2048~2045 (mm/s)" 901 "-2048~2045 (mm/s)" 902 "-2048~2045 (mm/s)" 903 "-2048~2045 (mm/s)" 904 "-2048~2045 (mm/s)" 905 "-2048~2045 (mm/s)" 906 "-2048~2045 (mm/s)" 907 "-2048~2045 (mm/s)" 908 "-2048~2045 (mm/s)" 909 "-2048~2045 (mm/s)" 910 "-2048~2045 (mm/s)" 911 "-2048~2045 (mm/s)" 912 "-2048~2045 (mm/s)" 913 "-2048~2045 (mm/s)" 914 "-2048~2045 (mm/s)" 915 "-2048~2045 (mm/s)" 916 "-2048~2045 (mm/s)" 917 "-2048~2045 (mm/s)" 918 "-2048~2045 (mm/s)" 919 "-2048~2045 (mm/s)" 920 "-2048~2045 (mm/s)" 921 "-2048~2045 (mm/s)" 922 "-2048~2045 (mm/s)" 923 "-2048~2045 (mm/s)" 924 "-2048~2045 (mm/s)" 925 "-2048~2045 (mm/s)" 926 "-2048~2045 (mm/s)" 927 "-2048~2045 (mm/s)" 928 "-2048~2045 (mm/s)" 929 "-2048~2045 (mm/s)" 930 "-2048~2045 (mm/s)" 931 "-2048~2045 (mm/s)" 932 "-2048~2045 (mm/s)" 933 "-2048~2045 (mm/s)" 934 "-2048~2045 (mm/s)" 935 "-2048~2045 (mm/s)" 936 "-2048~2045 (mm/s)" 937 "-2048~2045 (mm/s)" 938 "-2048~2045 (mm/s)" 939 "-2048~2045 (mm/s)" 940 "-2048~2045 (mm/s)" 941 "-2048~2045 (mm/s)" 942 "-2048~2045 (mm/s)" 943 "-2048~2045 (mm/s)" 944 "-2048~2045 (mm/s)" 945 "-2048~2045 (mm/s)" 946 "-2048~2045 (mm/s)" 947 "-2048~2045 (mm/s)" 948 "-2048~2045 (mm/s)" 949 "-2048~2045 (mm/s)" 950 "-2048~2045 (mm/s)" 951 "-2048~2045 (mm/s)" 952 "-2048~2045 (mm/s)" 953 "-2048~2045 (mm/s)" 954 "-2048~2045 (mm/s)" 955 "-2048~2045 (mm/s)" 956 "-2048~2045 (mm/s)" 957 "-2048~2045 (mm/s)" 958 "-2048~2045 (mm/s)" 959 "-2048~2045 (mm/s)" 960 "-2048~2045 (mm/s)" 961 "-2048~2045 (mm/s)" 962 "-2048~2045 (mm/s)" 963 "-2048~2045 (mm/s)" 964 "-2048~2045 (mm/s)" 965 "-2048~2045 (mm/s)" 966 "-2048~2045 (mm/s)" 967 "-2048~2045 (mm/s)" 968 "-2048~2045 (mm/s)" 969 "-2048~2045 (mm/s)" 970 "-2048~2045 (mm/s)" 971 "-2048~2045 (mm/s)" 972 "-2048~2045 (mm/s)" 973 "-2048~2045 (mm/s)" 974 "-2048~2045 (mm/s)" 975 "-2048~2045 (mm/s)" 976 "-2048~2045 (mm/s)" 977 "-2048~2045 (mm/s)" 978 "-2048~2045 (mm/s)" 979 "-2048~2045 (mm/s)" 980 "-2048~2045 (mm/s)" 981 "-2048~2045 (mm/s)" 982 "-2048~2045 (mm/s)" 983 "-2048~2045 (mm/s)" 984 "-2048~2045 (mm/s)" 985 "-2048~2045 (mm/s)" 986 "-2048~2045 (mm/s)" 987 "-2048~2045 (mm/s)" 988 "-2048~2045 (mm/s)" 989 "-2048~2045 (mm/s)" 990 "-2048~2045 (mm/s)" 991 "-2048~2045 (mm/s)" 992 "-2048~2045 (mm/s)" 993 "-2048~2045 (mm/s)" 994 "-2048~2045 (mm/s)" 995 "-2048~2045 (mm/s)" 996 "-2048~2045 (mm/s)" 997 "-2048~2045 (mm/s)" 998 "-2048~2045 (mm/s)" 999 "-2048~2045 (mm/s)" 1000 "-2048~2045 (mm/s)" 1001 "-2048~2045 (mm/s)" 1002 "-2048~2045 (mm/s)" 1003 "-2048~2045 (mm/s)" 1004 "-2048~2045 (mm/s)" 1005 "-2048~2045 (mm/s)" 1006 "-2048~2045 (mm/s)" 1007 "-2048~2045 (mm/s)" 1008 "-2048~2045 (mm/s)" 1009 "-2048~2045 (mm/s)" 1010 "-2048~2045 (mm/s)" 1011 "-2048~2045 (mm/s)" 1012 "-2048~2045 (mm/s)" 1013 "-2048~2045 (mm/s)" 1014 "-2048~2045 (mm/s)" 1015 "-2048~2045 (mm/s)" 1016 "-2048~2045 (mm/s)" 1017 "-2048~2045 (mm/s)" 1018 "-2048~2045 (mm/s)" 1019 "-2048~2045 (mm/s)" 1020 "-2048~2045 (mm/s)" 1021 "-2048~2045 (mm/s)" 1022 "-2048~2045 (mm/s)" 1023 "-2048~2045 (mm/s)" 1024 "-2048~2045 (mm/s)" 1025 "-2048~2045 (mm/s)" 1026 "-2048~2045 (mm/s)" 1027 "-2048~2045 (mm/s)" 1028 "-2048~2045 (mm/s)" 1029 "-2048~2045 (mm/s)" 1030 "-2048~2045 (mm/s)" 1031 "-2048~2045 (mm/s)" 1032 "-2048~2045 (mm/s)" 1033 "-2048~2045 (mm/s)" 1034 "-2048~2045 (mm/s)" 1035 "-2048~2045 (mm/s)" 1036 "-2048~2045 (mm/s)" 1037 "-2048~2045 (mm/s)" 1038 "-2048~2045 (mm/s)" 1039 "-2048~2045 (mm/s)" 1040 "-2048~2045 (mm/s)" 1041 "-2048~2045 (mm/s)" 1042 "-2048~2045 (mm/s)" 1043 "-2048~2045 (mm/s)" 1044 "-2048~2045 (mm/s)" 1045 "-2048~2045 (mm/s)" 1046 "-2048~2045 (mm/s)" 1047 "-2048~2045 (mm/s)" 1048 "-2048~2045 (mm/s)" 1049 "-2048~2045 (mm/s)" 1050 "-2048~2045 (mm/s)" 1051 "-2048~2045 (mm/s)" 1052 "-2048~2045 (mm/s)" 1053 "-2048~2045 (mm/s)" 1054 "-2048~2045 (mm/s)" 1055 "-2048~2045 (mm/s)" 1056 "-2048~2045 (mm/s)" 1057 "-2048~2045 (mm/s)" 1058 "-2048~2045 (mm/s)" 1059 "-2048~2045 (mm/s)" 1060 "-2048~2045 (mm/s)" 1061 "-2048~2045 (mm/s)" 1062 "-2048~2045 (mm/s)" 1063 "-2048~2045 (mm/s)" 1064 "-2048~2045 (mm/s)" 1065 "-2048~2045 (mm/s)" 1066 "-2048~2045 (mm/s)" 1067 "-2048~2045 (mm/s)" 1068 "-2048~2045 (mm/s)" 1069 "-2048~2045 (mm/s)" 1070 "-2048~2045 (mm/s)" 1071 "-2048~2045 (mm/s)" 1072 "-2048~2045 (mm/s)" 1073 "-2048~2045 (mm/s)" 1074 "-2048~2045 (mm/s)" 1075 "-2048~2045 (mm/s)" 1076 "-2048~2045 (mm/s)" 1077 "-2048~2045 (mm/s)" 1078 "-2048~2045 (mm/s)" 1079 "-2048~2045 (mm/s)" 1080 "-2048~2045 (mm/s)" 1081 "-2048~2045 (mm/s)" 1082 "-2048~2045 (mm/s)" 1083 "-2048~2045 (mm/s)" 1084 "-2048~2045 (mm/s)" 1085 "-2048~2045 (mm/s)" 1086 "-2048~2045 (mm/s)" 1087 "-2048~2045 (mm/s)" 1088 "-2048~2045 (mm/s)" 1089 "-2048~2045 (mm/s)" 1090 "-2048~2045 (mm/s)" 1091 "-2048~2045 (mm/s)" 1092 "-2048~2045 (mm/s)" 1093 "-2048~2045 (mm/s)" 1094 "-2048~2045 (mm/s)" 1095 "-2048~2045 (mm/s)" 1096 "-2048~2045 (mm/s)" 1097 "-2048~2045 (mm/s)" 1098 "-2048~2045 (mm/s)" 1099 "-2048~2045 (mm/s)" 1100 "-2048~2045 (mm/s)" 1101 "-2048~2045 (mm/s)" 1102 "-2048~2045 (mm/s)" 1103 "-2048~2045 (mm/s)" 1104 "-2048~2045 (mm/s)" 1105 "-2048~2045 (mm/s)" 1106 "-2048~2045 (mm/s)" 1107 "-2048~2045 (mm/s)" 1108 "-2048~2045 (mm/s)" 1109 "-2048~2045 (mm/s)" 1110 "-2048~2045 (mm/s)" 1111 "-2048~2045 (mm/s)" 1112 "-2048~2045 (mm/s)" 1113 "-2048~2045 (mm/s)" 1114 "-2048~2045 (mm/s)" 1115 "-2048~2045 (mm/s)" 1116 "-2048~2045 (mm/s)" 1117 "-2048~2045 (mm/s)" 1118 "-2048~2045 (mm/s)" 1119 "-2048~2045 (mm/s)" 1120 "-2048~2045 (mm/s)" 1121 "-2048~2045 (mm/s)" 1122 "-2048~2045 (mm/s)" 1123 "-2048~2045 (mm/s)" 1124 "-2048~2045 (mm/s)" 1125 "-2048~2045 (mm/s)" 1126 "-2048~2045 (mm/s)" 1127 "-2048~2045 (mm/s)" 1128 "-2048~2045 (mm/s)" 1129 "-2048~2045 (mm/s)" 1130 "-2048~2045 (mm/s)" 1131 "-2048~2045 (mm/s)" 1132 "-2048~2045 (mm/s)" 1133 "-2048~2045 (mm/s)" 1134 "-2048~2045 (mm/s)" 1135 "-2048~2045 (mm/s)" 1136 "-2048~2045 (mm/s)" 1137 "-2048~2045 (mm/s)" 1138 "-2048~2045 (mm/s)" 1139 "-2048~2045 (mm/s)" 1140 "-2048~2045 (mm/s)" 1141 "-2048~2045 (mm/s)" 1142 "-2048~2045 (mm/s)" 1143 "-2048~2045 (mm/s)" 1144 "-2048~2045 (mm/s)" 1145 "-2048~2045 (mm/s)" 1146 "-2048~2045 (mm/s)" 1147 "-2048~2045 (mm/s)" 1148 "-2048~2045 (mm/s)" 1149 "-2048~2045 (mm/s)" 1150 "-2048~2045 (mm/s)" 1151 "-2048~2045 (mm/s)" 1152 "-2048~2045 (mm/s)" 1153 "-2048~2045 (mm/s)" 1154 "-2048~2045 (mm/s)" 1155 "-2048~2045 (mm/s)" 1156 "-2048~2045 (mm/s)" 1157 "-2048~2045 (mm/s)" 1158 "-2048~2045 (mm/s)" 1159 "-2048~2045 (mm/s)" 1160 "-2048~2045 (mm/s)" 1161 "-2048~2045 (mm/s)" 1162 "-2048~2045 (mm/s)" 1163 "-2048~2045 (mm/s)" 1164 "-2048~2045 (mm/s)" 1165 "-2048~2045 (mm/s)" 1166 "-2048~2045 (mm/s)" 1167 "-2048~2045 (mm/s)" 1168 "-2048~2045 (mm/s)" 1169 "-2048~2045 (mm/s)" 1170 "-2048~2045 (mm/s)" 1171 "-2048~2045 (mm/s)" 1172 "-2048~2045 (mm/s)" 1173 "-2048~2045 (mm/s)" 1174 "-2048~2045 (mm/s)" 1175 "-2048~2045 (mm/s)" 1176 "-2048~2045 (mm/s)" 1177 "-2048~2045 (mm/s)" 1178 "-2048~2045 (mm/s)" 1179 "-2048~2045 (mm/s)" 1180 "-2048~2045 (mm/s)" 1181 "-2048~2045 (mm/s)" 1182 "-2048~2045 (mm/s)" 1183 "-2048~2045 (mm/s)" 1184 "-2048~2045 (mm/s)" 1185 "-2048~2045 (mm/s)" 1186 "-2048~2045 (mm/s)" 1187 "-2048~2045 (mm/s)" 1188 "-2048~2045 (mm/s)" 1189 "-2048~2045 (mm/s)" 1190 "-2048~2045 (mm/s)" 1191 "-2048~2045 (mm/s)" 1192 "-2048~2045 (mm/s)" 1193 "-2048~2045 (mm/s)" 1194 "-2048~2045 (mm/s)" 1195 "-2048~2045 (mm/s)" 1196 "-2048~2045 (mm/s)" 1197 "-2048~2045 (mm/s)" 1198 "-2048~2045 (mm/s)" 1199 "-2048~2045 (mm/s)" 1200 "-2048~2045 (mm/s)" 1201 "-2048~2045 (mm/s)" 1202 "-2048~2045 (mm/s)" 1203 "-2048~2045 (mm/s)" 1204 "-2048~2045 (mm/s)" 1205 "-2048~2045 (mm/s)" 1206 "-2048~2045 (mm/s)" 1207 "-2048~2045 (mm/s)" 1208 "-2048~2045 (mm/s)" 1209 "-2048~2045 (mm/s)" 1210 "-2048~2045 (mm/s)" 1211 "-2048~2045 (mm/s)" 1212 "-2048~2045 (mm/s)" 1213 "-2048~2045 (mm/s)" 1214 "-2048~2045 (mm/s)" 1215 "-2048~2045 (mm/s)" 1216 "-2048~2045 (mm/s)" 1217 "-2048~2045 (mm/s)" 1218 "-2048~2045 (mm/s)" 1219 "-2048~2045 (mm/s)" 1220 "-2048~2045 (mm/s)" 1221 "-2048~2045 (mm/s)" 1222 "-2048~2045 (mm/s)" 1223 "-2048~2045 (mm/s)" 1224 "-2048~2045 (mm/s)" 1225 "-2048~2045 (mm/s)" 1226 "-2048~2045 (mm/s)" 1227 "-2048~2045 (mm/s)" 1228 "-2048~2045 (mm/s)" 1229 "-2048~2045 (mm/s)" 1230 "-2048~2045 (mm/s)" 1231 "-2048~2045 (mm/s)" 1232 "-2048~2045 (mm/s)" 1233 "-2048~2045 (mm/s)" 1234 "-2048~2045 (mm/s)" 1235 "-2048~2045 (mm/s)" 1236 "-2048~2045 (mm/s)" 1237 "-2048~2045 (mm/s)" 1238 "-2048~2045 (mm/s)" 1239 "-2048~2045 (mm/s)" 1240 "-2048~2045 (mm/s)" 1241 "-2048~2045 (mm/s)" 1242 "-2048~2045 (mm/s)" 1243 "-2048~2045 (mm/s)" 1244 "-2048~2045 (mm/s)" 1245 "-2048~2045 (mm/s)" 1246 "-2048~2045 (mm/s)" 1247 "-2048~2045 (mm/s)" 1248 "-2048~2045 (mm/s)" 1249 "-2048~2045 (mm/s)" 1250 "-2048~2045 (mm/s)" 1251 "-2048~2045 (mm/s)" 1252 "-2048~2045 (mm/s)" 1253 "-2048~2045 (mm/s)" 1254 "-2048~2045 (mm/s)" 1255 "-2048~2045 (mm/s)" 1256 "-2048~2045 (mm/s)" 1257 "-2048~2045 (mm/s)" 1258 "-2048~2045 (mm/s)" 1259 "-2048~2045 (mm/s)" 1260 "-2048~2045 (mm/s)" 1261 "-2048~2045 (mm/s)" 1262 "-2048~2045 (mm/s)" 1263 "-2048~2045 (mm/s)" 1264 "-2048~2045 (mm/s)" 1265 "-2048~2045 (mm/s)" 1266 "-2048~2045 (mm/s)" 1267 "-2048~2045 (mm/s)" 1268 "-2048~2045 (mm/s)" 1269 "-2048~2045 (mm/s)" 1270 "-2048~2045 (mm/s)" 1271 "-2048~2045 (mm/s)" 1272 "-2048~2045 (mm/s)" 1273 "-2048~2045 (mm/s)" 1274 "-2048~2045 (mm/s)" 1275 "-2048~2045 (mm/s)" 1276 "-2048~2045 (mm/s)" 1277 "-2048~2045 (mm/s)" 1278 "-2048~2045 (mm/s)" 1279 "-2048~2045 (mm/s)" 1280 "-2048~2045 (mm/s)" 1281 "-2048~2045 (mm/s)" 1282 "-2048~2045 (mm/s)" 1283 "-2048~2045 (mm/s)" 1284 "-2048~2045 (mm/s)" 1285 "-2048~2045 (mm/s)" 1286 "-2048~2045 (mm/s)" 1287 "-2048~2045 (mm/s)" 1288 "-2048~2045 (mm/s)" 1289 "-2048~2045 (mm/s)" 1290 "-2048~2045 (mm/s)" 1291 "-2048~2045 (mm/s)" 1292 "-2048~2045 (mm/s)" 1293 "-2048~2045 (mm/s)" 1294 "-2048~2045 (mm/s)" 1295 "-2048~2045 (mm/s)" 1296 "-2048~2045 (mm/s)" 1297 "-2048~2045 (mm/s)" 1298 "-2048~2045 (mm/s)" 1299 "-2048~2045 (mm/s)" 1300 "-2048~2045 (mm/s)" 1301 "-2048~2045 (mm/s)" 1302 "-2048~2045 (mm/s)" 1303 "-2048~2045 (mm/s)" 1304 "-2048~2045 (mm/s)" 1305 "-2048~2045 (mm/s)" 1306 "-2048~2045 (mm/s)" 1307 "-2048~2045 (mm/s)" 1308 "-2048~2045 (mm/s)" 1309 "-2048~2045 (mm/s)" 1310 "-2048~2045 (mm/s)" 1311 "-2048~2045 (mm/s)" 1312 "-2048~2045 (mm/s)" 1313 "-2048~2045 (mm/s)" 1314 "-2048~2045 (mm/s)" 1315 "-2048~2045 (mm/s)" 1316 "-2048~2045 (mm/s)" 1317 "-2048~2045 (mm/s)" 1318 "-2048~2045 (mm/s)" 1319 "-2048~2045 (mm/s)" 1320 "-2048~2045 (mm/s)" 1321 "-2048~2045 (mm/s)" 1322 "-2048~2045 (mm/s)" 1323 "-2048~2045 (mm/s)" 1324 "-2048~2045 (mm/s)" 1325 "-2048~2045 (mm/s)" 1326 "-2048~2045 (mm/s)" 1327 "-2048~2045 (mm/s)" 1328 "-2048~2045 (mm/s)" 1329 "-2048~2045 (mm/s)" 1330 "-2048~2045 (mm/s)" 1331 "-2048~2045 (mm/s)" 1332 "-2048~2045 (mm/s)" 1333 "-2048~2045 (mm/s)" 1334 "-2048~2045 (mm/s)" 1335 "-2048~2045 (mm/s)" 1336 "-2048~2045 (mm/s)" 1337 "-2048~2045 (mm/s)" 1338 "-2048~2045 (mm/s)" 1339 "-2048~2045 (mm/s)" 1340 "-2048~2045 (mm/s)" 1341 "-2048~2045 (mm/s)" 1342 "-2048~2045 (mm/s)" 1343 "-2048~2045 (mm/s)" 1344 "-2048~2045 (mm/s)" 1345 "-2048~2045 (mm/s)" 1346 "-2048~2045 (mm/s)" 1347 "-2048~2045 (mm/s)" 1348 "-2048~2045 (mm/s)" 1349 "-2048~2045 (mm/s)" 1350 "-2048~2045 (mm/s)" 1351 "-2048~2045 (mm/s)" 1352 "-2048~2045 (mm/s)" 1353 "-2048~2045 (mm/s)" 1354 "-2048~2045 (mm/s)" 1355 "-2048~2045 (mm/s)" 1356 "-2048~2045 (mm/s)" 1357 "-2048~2045 (mm/s)" 1358 "-2048~2045 (mm/s)" 1359 "-2048~2045 (mm/s)" 1360 "-2048~2045 (mm/s)" 1361 "-2048~2045 (mm/s)" 1362 "-2048~2045 (mm/s)" 1363 "-2048~2045 (mm/s)" 1364 "-2048~2045 (mm/s)" 1365 "-2048~2045 (mm/s)" 1366 "-2048~2045 (mm/s)" 1367 "-2048~2045 (mm/s)" 1368 "-2048~2045 (mm/s)" 1369 "-2048~2045 (mm/s)" 1370 "-2048~2045 (mm/s)" 1371 "-2048~2045 (mm/s)" 1372 "-2048~2045 (mm/s)" 1373 "-2048~2045 (mm/s)" 1374 "-2048~2045 (mm/s)" 1375 "-2048~2045 (mm/s)" 1376 "-2048~2045 (mm/s)" 1377 "-2048~2045 (mm/s)" 1378 "-2048~2045 (mm/s)" 1379 "-2048~2045 (mm/s)" 1380 "-2048~2045 (mm/s)" 1381 "-2048~2045 (mm/s)" 1382 "-2048~2045 (mm/s)" 1383 "-2048~2045 (mm/s)" 1384 "-2048~2045 (mm/s)" 1385 "-2048~2045 (mm/s)" 1386 "-2048~2045 (mm/s)" 1387 "-2048~2045 (mm/s)" 1388 "-2048~2045 (mm/s)" 1389 "-2048~2045 (mm/s)" 1390 "-2048~2045 (mm/s)" 1391 "-2048~2045 (mm/s)" 1392 "-2048~2045 (mm/s)" 1393 "-2048~2045 (mm/s)" 1394 "-2048~2045 (mm/s)" 1395 "-2048~2045 (mm/s)" 1396 "-2048~2045 (mm/s)" 1397 "-2048~2045 (mm/s)" 1398 "-2048~2045 (mm/s)" 1399 "-2048~2045 (mm/s)" 1400 "-2048~2045 (mm/s)" 1401 "-2048~2045 (mm/s)" 1402 "-2048~2045 (mm/s)" 1403 "-2048~2045 (mm/s)" 1404 "-2048~2045 (mm/s)" 1405 "-2048~2045 (mm/s)" 1406 "-2048~2045 (mm/s)" 1407 "-2048~2045 (mm/s)" 1408 "-2048~2045 (mm/s)" 1409 "-2048~2045 (mm/s)" 1410 "-2048~2045 (mm/s)" 1411 "-2048~2045 (mm/s)" 1412 "-2048~2045 (mm/s)" 1413 "-2048~2045 (mm/s)" 1414 "-2048~2045 (mm/s)" 1415 "-2048~2045 (mm/s)" 1416 "-2048~2045 (mm/s)" 1417 "-2048~2045 (mm/s)" 1418 "-2048~2045 (mm/s)" 1419 "-2048~2045 (mm/s)" 1420 "-2048~2045 (mm/s)" 1421 "-2048~2045 (mm/s)" 1422 "-2048~2045 (mm/s)" 1423 "-2048~2045 (mm/s)" 1424 "-2048~2045 (mm/s)" 1425 "-2048~2045 (mm/s)" 1426 "-2048~2045 (mm/s)" 1427 "-2048~2045 (mm/s)" 1428 "-2048~2045 (mm/s)" 1429 "-2048~2045 (mm/s)" 1430 "-2048~2045 (mm/s)" 1431 "-2048~2045 (mm/s)" 1432 "-2048~2045 (mm/s)" 1433 "-2048~2045 (mm/s)" 1434 "-2048~2045 (mm/s)" 1435 "-2048~2045 (mm/s)" 1436 "-2048~2045 (mm/s)" 1437 "-2048~2045 (mm/s)" 1438 "-2048~2045 (mm/s)" 1439 "-2048~2045 (mm/s)" 1440 "-2048~2045 (mm/s)" 1441 "-2048~2045 (mm/s)" 1442 "-2048~2045 (mm/s)" 1443 "-2048~2045 (mm/s)" 1444 "-2048~2045 (mm/s)" 1445 "-2048~2045 (mm/s)" 1446 "-2048~2045 (mm/s)" 1447 "-2048~2045 (mm/s)" 1448 "-2048~2045 (mm/s)" 1449 "-2048~2045 (mm/s)" 1450 "-2048~2045 (mm/s)" 1451 "-2048~2045 (mm/s)" 1452 "-2048~2045 (mm/s)" 1453 "-2048~2045 (mm/s)" 1454 "-2048~2045 (mm/s)" 1455 "-2048~2045 (mm/s)" 1456 "-2048~2045 (mm/s)" 1457 "-2048~2045 (mm/s)" 1458 "-2048~2045 (mm/s)" 1459 "-2048~2045 (mm/s)" 1460 "-2048~2045 (mm/s)" 1461 "-2048~2045 (mm/s)" 1462 "-2048~2045 (mm/s)" 1463 "-2048~2045 (mm/s)" 1464 "-2048~2045 (mm/s)" 1465 "-2048~2045 (mm/s)" 1466 "-2048~2045 (mm/s)" 1467 "-2048~2045 (mm/s)" 1468 "-2048~2045 (mm/s)" 1469 "-2048~2045 (mm/s)" 1470 "-2048~2045 (mm/s)" 1471 "-2048~2045 (mm/s)" 1472 "-2048~2045 (mm/s)" 1473 "-2048~2045 (mm/s)" 1474 "-2048~2045 (mm/s)" 1475 "-2048~2045 (mm/s)" 1476 "-2048~2045 (mm/s)" 1477 "-2048~2045 (mm/s)" 1478 "-2048~2045 (mm/s)" 1479 "-2048~2045 (mm/s)" 1480 "-2048~2045 (mm/s)" 1481 "-2048~2045 (mm/s)" 1482 "-2048~2045 (mm/s)" 1483 "-2048~2045 (mm/s)" 1484 "-2048~2045 (mm/s)" 1485 "-2048~2045 (mm/s)" 1486 "-2048~2045 (mm/s)" 1487 "-2048~2045 (mm/s)" 1488 "-2048~2045 (mm/s)" 1489 "-2048~2045 (mm/s)" 1490 "-2048~2045 (mm/s)" 1491 "-2048~2045 (mm/s)" 1492 "-2048~2045 (mm/s)" 1493 "-2048~2045 (mm/s)" 1494 "-2048~2045 (mm/s)" 1495 "-2048~2045 (mm/s)" 1496 "-2048~2045 (mm/s)" 1497 "-2048~2045 (mm/s)" 1498 "-2048~2045 (mm/s)" 1499 "-2048~2045 (mm/s)" 1500 "-2048~2045 (mm/s)" 1501 "-2048~2045 (mm/s)" 1502 "-2048~2045 (mm/s)" 1503 "-2048~2045 (mm/s)" 1504 "-2048~2045 (mm/s)" 1505 "-2048~2045 (mm/s)" 1506 "-2048~2045 (mm/s)" 1507 "-2048~2045 (mm/s)" 1508 "-2048~2045 (mm/s)" 1509 "-2048~2045 (mm/s)" 1510 "-2048~2045 (mm/s)" 1511 "-2048~2045 (mm/s)" 1512 "-2048~2045 (mm/s)" 1513 "-2048~2045 (mm/s)" 1514 "-2048~2045 (mm/s)" 1515 "-2048~2045 (mm/s)" 1516 "-2048~2045 (mm/s)" 1517 "-2048~2045 (mm/s)" 1518 "-2048~2045 (mm/s)" 1519 "-2048~2045 (mm/s)" 1520 "-2048~2045 (mm/s)" 1521 "-2048~2045 (mm/s)" 1522 "-2048~2045 (mm/s)" 1523 "-2048~2045 (mm/s)" 1524 "-2048~2045 (mm/s)" 1525 "-2048~2045 (mm/s)" 1526 "-2048~2045 (mm/s)" 1527 "-2048~2045 (mm/s)" 1528 "-2048~2045 (mm/s)" 1529 "-2048~2045 (mm/s)" 1530 "-2048~2045 (mm/s)" 1531 "-2048~2045 (mm/s)" 1532 "-2048~2045 (mm/s)" 1533 "-2048~2045 (mm/s)" 1534 "-2048~2045 (mm/s)" 1535 "-2048~2045 (mm/s)" 1536 "-2048~2045 (mm/s)" 1537 "-2048~2045 (mm/s)" 1538 "-2048~2045 (mm/s)" 1539 "-2048~2045 (mm/s)" 1540 "-2048~2045 (mm/s)" 1541 "-2048~2045 (mm/s)" 1542 "-2048~2045 (mm/s)" 1543 "-2048~2045 (mm/s)" 1544 "-2048~2045 (mm/s)" 1545 "-2048~2045 (mm/s)" 1546 "-2048~2045 (mm/s)" 1547 "-2048~2045 (mm/s)" 1548 "-2048~2045 (mm/s)" 1549 "-2048~2045 (mm/s)" 1550 "-2048~2045 (mm/s)" 1551 "-2048~2045 (mm/s)" 1552 "-2048~2045 (mm/s)" 1553 "-2048~2045 (mm/s)" 1554 "-2048~2045 (mm/s)" 1555 "-2048~2045 (mm/s)" 1556 "-2048~2045 (mm/s)" 1557 "-2048~2045 (mm/s)" 1558 "-2048~2045 (mm/s)" 1559 "-2048~2045 (mm/s)" 1560 "-2048~2045 (mm/s)" 1561 "-2048~2045 (mm/s)" 1562 "-2048~2045 (mm/s)" 1563 "-2048~2045 (mm/s)" 1564 "-2048~2045 (mm/s)" 1565 "-2048~2045 (mm/s)" 1566 "-2048~2045 (mm/s)" 1567 "-2048~2045 (mm/s)" 1568 "-2048~2045 (mm/s)" 1569 "-2048~2045 (mm/s)" 1570 "-2048~2045 (mm/s)" 1571 "-2048~2045 (mm/s)" 1572 "-2048~2045 (mm/s)" 1573 "-2048~2045 (mm/s)" 1574 "-2048~2045 (mm/s)" 1575 "-2048~2045 (mm/s)" 1576 "-2048~2045 (mm/s)" 1577 "-2048~2045 (mm/s)" 1578 "-2048~2045 (mm/s)" 1579 "-2048~2045 (mm/s)" 1580 "-2048~2045 (mm/s)" 1581 "-2048~2045 (mm/s)" 1582 "-2048~2045 (mm/s)" 1583 "-2048~2045 (mm/s)" 1584 "-2048~2045 (mm/s)" 1585 "-2048~2045 (mm/s)" 1586 "-2048~2045 (mm/s)" 1587 "-2048~2045 (mm/s)" 1588 "-2048~2045 (mm/s)" 1589 "-2048~2045 (mm/s)" 1590 "-2048~2045 (mm/s)" 1591 "-2048~2045 (mm/s)" 1592 "-2048~2045 (mm/s)" 1593 "-2048~2045 (mm/s)" 1594 "-2048~2045 (mm/s)" 1595 "-2048~2045 (mm/s)" 1596 "-2048~2045 (mm/s)" 1597 "-2048~2045 (mm/s)" 1598 "-2048~2045 (mm/s)" 1599 "-2048~2045 (mm/s)" 1600 "-2048~2045 (mm/s)" 1601 "-2048~2045 (mm/s)" 1602 "-2048~2045 (mm/s)" 1603 "-2048~2045 (mm/s)" 1604 "-2048~2045 (mm/s)" 1605 "-2048~2045 (mm/s)" 1606 "-2048~2045 (mm/s)" 1607 "-2048~2045 (mm/s)" 1608 "-2048~2045 (mm/s)" 1609 "-2048~2045 (mm/s)" 1610 "-2048~2045 (mm/s)" 1611 "-2048~2045 (mm/s)" 1612 "-2048~2045 (mm/s)" 1613 "-2048~2045 (mm/s)" 1614 "-2048~2045 (mm/s)" 1615 "-2048~2045 (mm/s)" 1616 "-2048~2045 (mm/s)" 1617 "-2048~2045 (mm/s)" 1618 "-2048~2045 (mm/s)" 1619 "-2048~2045 (mm/s)" 1620 "-2048~2045 (mm/s)" 1621 "-2048~2045 (mm/s)" 1622 "-2048~2045 (mm/s)" 1623 "-2048~2045 (mm/s)" 1624 "-2048~2045 (mm/s)" 1625 "-2048~2045 (mm/s)" 1626 "-2048~2045 (mm/s)" 1627 "-2048~2045 (mm/s)" 1628 "-2048~2045 (mm/s)" 1629 "-2048~2045 (mm/s)" 1630 "-2048~2045 (mm/s)" 1631 "-2048~2045 (mm/s)" 1632 "-2048~2045 (mm/s)" 1633 "-2048~2045 (mm/s)" 1634 "-2048~2045 (mm/s)" 1635 "-2048~2045 (mm/s)" 1636 "-2048~2045 (mm/s)" 1637 "-2048~2045 (mm/s)" 1638 "-2048~2045 (mm/s)" 1639 "-2048~2045 (mm/s)" 1640 "-2048~2045 (mm/s)" 1641 "-2048~2045 (mm/s)" 1642 "-2048~2045 (mm/s)" 1643 "-2048~2045 (mm/s)" 1644 "-2048~2045 (mm/s)" 1645 "-2048~2045 (mm/s)" 1646 "-2048~2045 (mm/s)" 1647 "-2048~2045 (mm/s)" 1648 "-2048~2045 (mm/s)" 1649 "-2048~2045 (mm/s)" 1650 "-2048~2045 (mm/s)" 1651 "-2048~2045 (mm/s)" 1652 "-2048~2045 (mm/s)" 1653 "-2048~2045 (mm/s)" 1654 "-2048~2045 (mm/s)" 1655 "-2048~2045 (mm/s)" 1656 "-2048~2045 (mm/s)" 1657 "-2048~2045 (mm/s)" 1658 "-2048~2045 (mm/s)" 1659 "-2048~2045 (mm/s)" 1660 "-2048~2045 (mm/s)" 1661 "-2048~2045 (mm/s)" 1662 "-2048~2045 (mm/s)" 1663 "-2048~2045 (mm/s)" 1664 "-2048~2045 (mm/s)" 1665 "-2048~2045 (mm/s)" 1666 "-2048~2045 (mm/s)" 1667 "-2048~2045 (mm/s)" 1668 "-2048~2045 (mm/s)" 1669 "-2048~2045 (mm/s)" 1670 "-2048~2045 (mm/s)" 1671 "-2048~2045 (mm/s)" 1672 "-2048~2045 (mm/s)" 1673 "-2048~2045 (mm/s)" 1674 "-2048~2045 (mm/s)" 1675 "-2048~2045 (mm/s)" 1676 "-2048~2045 (mm/s)" 1677 "-2048~2045 (mm/s)" 1678 "-2048~2045 (mm/s)" 1679 "-2048~2045 (mm/s)" 1680 "-2048~2045 (mm/s)" 1681 "-2048~2045 (mm/s)" 1682 "-2048~2045 (mm/s)" 1683 "-2048~2045 (mm/s)" 1684 "-2048~2045 (mm/s)" 1685 "-2048~2045 (mm/s)" 1686 "-2048~2045 (mm/s)" 1687 "-2048~2045 (mm/s)" 1688 "-2048~2045 (mm/s)" 1689 "-2048~2045 (mm/s)" 1690 "-2048~2045 (mm/s)" 1691 "-2048~2045 (mm/s)" 1692 "-2048~2045 (mm/s)" 1693 "-2048~2045 (mm/s)" 1694 "-2048~2045 (mm/s)" 1695 "-2048~2045 (mm/s)" 1696 "-2048~2045 (mm/s)" 1697 "-2048~2045 (mm/s)" 1698 "-2048~2045 (mm/s)" 1699 "-2048~2045 (mm/s)" 1700 "-2048~2045 (mm/s)" 1701 "-2048~2045 (mm/s)" 1702 "-2048~2045 (mm/s)" 1703 "-2048~2045 (mm/s)" 1704 "-2048~2045 (mm/s)" 1705 "-2048~2045 (mm/s)" 1706 "-2048~2045 (mm/s)" 1707 "-2048~2045 (mm/s)" 1708 "-2048~2045 (mm/s)" 1709 "-2048~2045 (mm/s)" 1710 "-2048~2045 (mm/s)" 1711 "-2048~2045 (mm/s)" 1712 "-2048~2045 (mm/s)" 1713 "-2048~2045 (mm/s)" 1714 "-2048~2045 (mm/s)" 1715 "-2048~2045 (mm/s)" 1716 "-2048~2045 (mm/s)" 1717 "-2048~2045 (mm/s)" 1718 "-2048~2045 (mm/s)" 1719 "-2048~2045 (mm/s)" 1720 "-2048~2045 (mm/s)" 1721 "-2048~2045 (mm/s)" 1722 "-2048~2045 (mm/s)" 1723 "-2048~2045 (mm/s)" 1724 "-2048~2045 (mm/s)" 1725 "-2048~2045 (mm/s)" 1726 "-2048~2045 (mm/s)" 1727 "-2048~2045 (mm/s)" 1728 "-2048~2045 (mm/s)" 1729 "-2048~2045 (mm/s)" 1730 "-2048~2045 (mm/s)" 1731 "-2048~2045 (mm/s)" 1732 "-2048~2045 (mm/s)" 1733 "-2048~2045 (mm/s)" 1734 "-2048~2045 (mm/s)" 1735 "-2048~2045 (mm/s)" 1736 "-2048~2045 (mm/s)" 1737 "-2048~2045 (mm/s)" 1738 "-2048~2045 (mm/s)" 1739 "-2048~2045 (mm/s)" 1740 "-2048~2045 (mm/s)" 1741 "-2048~2045 (mm/s)" 1742 "-2048~2045 (mm/s)" 1743 "-2048~2045 (mm/s)" 1744 "-2048~2045 (mm/s)" 1745 "-2048~2045 (mm/s)" 1746 "-2048~2045 (mm/s)" 1747 "-2048~2045 (mm/s)" 1748 "-2048~2045 (mm/s)" 1749 "-2048~2045 (mm/s)" 1750 "-2048~2045 (mm/s)" 1751 "-2048~2045 (mm/s)" 1752 "-2048~2045 (mm/s)" 1753 "-2048~2045 (mm/s)" 1754 "-2048~2045 (mm/s)" 1755 "-2048~2045 (mm/s)" 1756 "-2048~2045 (mm/s)" 1757 "-2048~2045 (mm/s)" 1758 "-2048~2045 (mm/s)" 1759 "-2048~2045 (mm/s)" 1760 "-2048~2045 (mm/s)" 1761 "-2048~2045 (mm/s)" 1762 "-2048~2045 (mm/s)" 1763 "-2048~2045 (mm/s)" 1764 "-2048~2045 (mm/s)" 1765 "-2048~2045 (mm/s)" 1766 "-2048~2045 (mm/s)" 1767 "-2048~2045 (mm/s)" 1768 "-2048~2045 (mm/s)" 1769 "-2048~2045 (mm/s)" 1770 "-2048~2045 (mm/s)" 1771 "-2048~2045 (mm/s)" 1772 "-2048~2045 (mm/s)" 1773 "-2048~2045 (mm/s)" 1774 "-2048~2045 (mm/s)" 1775 "-2048~2045 (mm/s)" 1776 "-2048~2045 (mm/s)" 1777 "-2048~2045 (mm/s)" 1778 "-2048~2045 (mm/s)" 1779 "-2048~2045 (mm/s)" 1780 "-2048~2045 (mm/s)" 1781 "-2048~2045 (mm/s)" 1782 "-2048~2045 (mm/s)" 1783 "-2048~2045 (mm/s)" 1784 "-2048~2045 (mm/s)" 1785 "-2048~2045 (mm/s)" 1786 "-2048~2045 (mm/s)" 1787 "-2048~2045 (mm/s)" 1788 "-2048~2045 (mm/s)" 1789 "-2048~2045 (mm/s)" 1790 "-2048~2045 (mm/s)" 1791 "-2048~2045 (mm/s)" 1792 "-2048~2045 (mm/s)" 1793 "-2048~2045 (mm/s)" 1794 "-2048~2045 (mm/s)" 1795 "-2048~2045 (mm/s)" 1796 "-2048~2045 (mm/s)" 1797 "-2048~2045 (mm/s)" 1798 "-2048~2045 (mm/s)" 1799 "-2048~2045 (mm/s)" 1800 "-2048~2045 (mm/s)" 1801 "-2048~2045 (mm/s)" 1802 "-2048~2045 (mm/s)" 1803 "-2048~2045 (mm/s)" 1804 "-2048~2045 (mm/s)" 1805 "-2048~2045 (mm/s)" 1806 "-2048~2045 (mm/s)" 1807 "-2048~2045 (mm/s)" 1808 "-2048~2045 (mm/s)" 1809 "-2048~2045 (mm/s)" 1810 "-2048~2045 (mm/s)" 1811 "-2048~2045 (mm/s)" 1812 "-2048~2045 (mm/s)" 1813 "-2048~2045 (mm/s)" 1814 "-2048~2045 (mm/s)" 1815 "-2048~2045 (mm/s)" 1816 "-2048~2045 (mm/s)" 1817 "-2048~2045 (mm/s)" 1818 "-2048~2045 (mm/s)" 1819 "-2048~2045 (mm/s)" 1820 "-2048~2045 (mm/s)" 1821 "-2048~2045 (mm/s)" 1822 "-2048~2045 (mm/s)" 1823 "-2048~2045 (mm/s)" 1824 "-2048~2045 (mm/s)" 1825 "-2048~2045 (mm/s)" 1826 "-2048~2045 (mm/s)" 1827 "-2048~2045 (mm/s)" 1828 "-2048~2045 (mm/s)" 1829 "-2048~2045 (mm/s)" 1830 "-2048~2045 (mm/s)" 1831 "-2048~2045 (mm/s)" 1832 "-2048~2045 (mm/s)" 1833 "-2048~2045 (mm/s)" 1834 "-2048~2045 (mm/s)" 1835 "-2048~2045 (mm/s)" 1836 "-2048~2045 (mm/s)" 1837 "-2048~2045 (mm/s)" 1838 "-2048~2045 (mm/s)" 1839 "-2048~2045 (mm/s)" 1840 "-2048~2045 (mm/s)" 1841 "-2048~2045 (mm/s)" 1842 "-2048~2045 (mm/s)" 1843 "-2048~2045 (mm/s)" 1844 "-2048~2045 (mm/s)" 1845 "-2048~2045 (mm/s)" 1846 "-2048~2045 (mm/s)" 1847 "-2048~2045 (mm/s)" 1848 "-2048~2045 (mm/s)" 1849 "-2048~2045 (mm/s)" 1850 "-2048~2045 (mm/s)" 1851 "-2048~2045 (mm/s)" 1852 "-2048~2045 (mm/s)" 1853 "-2048~2045 (mm/s)" 1854 "-2048~2045 (mm/s)" 1855 "-2048~2045 (mm/s)" 1856 "-2048~2045 (mm/s)" 1857 "-2048~2045 (mm/s)" 1858 "-2048~2045 (mm/s)" 1859 "-2048~2045 (mm/s)" 1860 "-2048~2045 (mm/s)" 1861 "-2048~2045 (mm/s)" 1862 "-2048~2045 (mm/s)" 1863 "-2048~2045 (mm/s)" 1864 "-2048~2045 (mm/s)" 1865 "-2048~2045 (mm/s)" 1866 "-2048~2045 (mm/s)" 1867 "-2048~2045 (mm/s)" 1868 "-2048~2045 (mm/s)" 1869 "-2048~2045 (mm/s)" 1870 "-2048~2045 (mm/s)" 1871 "-2048~2045 (mm/s)" 1872 "-2048~2045 (mm/s)" 1873 "-2048~2045 (mm/s)" 1874 "-2048~2045 (mm/s)" 1875 "-2048~2045 (mm/s)" 1876 "-2048~2045 (mm/s)" 1877 "-2048~2045 (mm/s)" 1878 "-2048~2045 (mm/s)" 1879 "-2048~2045 (mm/s)" 1880 "-2048~2045 (mm/s)" 1881 "-2048~2045 (mm/s)" 1882 "-2048~2045 (mm/s)" 1883 "-2048~2045 (mm/s)" 1884 "-2048~2045 (mm/s)" 1885 "-2048~2045 (mm/s)" 1886 "-2048~2045 (mm/s)" 1887 "-2048~2045 (mm/s)" 1888 "-2048~2045 (mm/s)" 1889 "-2048~2045 (mm/s)" 1890 "-2048~2045 (mm/s)" 1891 "-2048~2045 (mm/s)" 1892 "-2048~2045 (mm/s)" 1893 "-2048~2045 (mm/s)" 1894 "-2048~2045 (mm/s)" 1895 "-2048~2045 (mm/s)" 1896 "-2048~2045 (mm/s)" 1897 "-2048~2045 (mm/s)" 1898 "-2048~2045 (mm/s)" 1899 "-2048~2045 (mm/s)" 1900 "-2048~2045 (mm/s)" 1901 "-2048~2045 (mm/s)" 1902 "-2048~2045 (mm/s)" 1903 "-2048~2045 (mm/s)" 1904 "-2048~2045 (mm/s)" 1905 "-2048~2045 (mm/s)" 1906 "-2048~2045 (mm/s)" 1907 "-2048~2045 (mm/s)" 1908 "-2048~2045 (mm/s)" 1909 "-2048~2045 (mm/s)" 1910 "-2048~2045 (mm/s)" 1911 "-2048~2045 (mm/s)" 1912 "-2048~2045 (mm/s)" 1913 "-2048~2045 (mm/s)" 1914 "-2048~2045 (mm/s)" 1915 "-2048~2045 (mm/s)" 1916 "-2048~2045 (mm/s)" 1917 "-2048~2045 (mm/s)" 1918 "-2048~2045 (mm/s)" 1919 "-2048~2045 (mm/s)" 1920 "-2048~2045 (mm/s)" 1921 "-2048~2045 (mm/s)" 1922 "-2048~2045 (mm/s)" 1923 "-2048~2045 (mm/s)" 1924 "-2048~2045 (mm/s)" 1925 "-2048~2045 (mm/s)" 1926 "-2048~2045 (mm/s)" 1927 "-2048~2045 (mm/s)" 1928 "-2048~2045 (mm/s)" 1929 "-2048~2045 (mm/s)" 1930 "-2048~2045 (mm/s)" 1931 "-2048~2045 (mm/s)" 1932 "-2048~2045 (mm/s)" 1933 "-2048~2045 (mm/s)" 1934 "-2048~2045 (mm/s)" 1935 "-2048~2045 (mm/s)" 1936 "-2048~2045 (mm/s)" 1937 "-2048~2045 (mm/s)" 1938 "-2048~2045 (mm/s)" 1939 "-2048~2045 (mm/s)" 1940 "-2048~2045 (mm/s)" 1941 "-2048~2045 (mm/s)" 1942 "-2048~2045 (mm/s)" 1943 "-2048~2045 (mm/s)" 1944 "-2048~2045 (mm/s)" 1945 "-2048~2045 (mm/s)" 1946 "-2048~2045 (mm/s)" 1947 "-2048~2045 (mm/s)" 1948 "-2048~2045 (mm/s)" 1949 "-2048~2045 (mm/s)" 1950 "-2048~2045 (mm/s)" 1951 "-2048~2045 (mm/s)" 1952 "-2048~2045 (mm/s)" 1953 "-2048~2045 (mm/s)" 1954 "-2048~2045 (mm/s)" 1955 "-2048~2045 (mm/s)" 1956 "-2048~2045 (mm/s)" 1957 "-2048~2045 (mm/s)" 1958 "-2048~2045 (mm/s)" 1959 "-2048~2045 (mm/s)" 1960 "-2048~2045 (mm/s)" 1961 "-2048~2045 (mm/s)" 1962 "-2048~2045 (mm/s)" 1963 "-2048~2045 (mm/s)" 1964 "-2048~2045 (mm/s)" 1965 "-2048~2045 (mm/s)" 1966 "-2048~2045 (mm/s)" 1967 "-2048~2045 (mm/s)" 1968 "-2048~2045 (mm/s)" 1969 "-2048~2045 (mm/s)" 1970 "-2048~2045 (mm/s)" 1971 "-2048~2045 (mm/s)" 1972 "-2048~2045 (mm/s)" 1973 "-2048~2045 (mm/s)" 1974 "-2048~2045 (mm/s)" 1975 "-2048~2045 (mm/s)" 1976 "-2048~2045 (mm/s)" 1977 "-2048~2045 (mm/s)" 1978 "-2048~2045 (mm/s)" 1979 "-2048~2045 (mm/s)" 1980 "-2048~2045 (mm/s)" 1981 "-2048~2045 (mm/s)" 1982 "-2048~2045 (mm/s)" 1983 "-2048~2045 (mm/s)" 1984 "-2048~2045 (mm/s)" 1985 "-2048~2045 (mm/s)" 1986 "-2048~2045 (mm/s)" 1987 "-2048~2045 (mm/s)" 1988 "-2048~2045 (mm/s)" 1989 "-2048~2045 (mm/s)" 1990 "-2048~2045 (mm/s)" 1991 "-2048~2045 (mm/s)" 1992 "-2048~2045 (mm/s)" 1993 "-2048~2045 (mm/s)" 1994 "-2048~2045 (mm/s)" 1995 "-2048~2045 (mm/s)" 1996 "-2048~2045 (mm/s)" 1997 "-2048~2045 (mm/s)" 1998 "-2048~2045 (mm/s)" 1999 "-2048~2045 (mm/s)" 2000 "-2048~2045 (mm/s)" 2001 "-2048~2045 (mm/s)" 2002 "-2048~2045 (mm/s)" 2003 "-2048~2045 (mm/s)" 2004 "-2048~2045 (mm/s)" 2005 "-2048~2045 (mm/s)" 2006 "-2048~2045 (mm/s)" 2007 "-2048~2045 (mm/s)" 2008 "-2048~2045 (mm/s)" 2009 "-2048~2045 (mm/s)" 2010 "-2048~2045 (mm/s)" 2011 "-2048~2045 (mm/s)" 2012 "-2048~2045 (mm/s)" 2013 "-2048~2045 (mm/s)" 2014 "-2048~2045 (mm/s)" 2015 "-2048~2045 (mm/s)" 2016 "-2048~2045 (mm/s)" 2017 "-2048~2045 (mm/s)" 2018 "-2048~2045 (mm/s)" 2019 "-2048~2045 (mm/s)" 2020 "-2048~2045 (mm/s)" 2021 "-2048~2045 (mm/s)" 2022 "-2048~2045 (mm/s)" 2023 "-2048~2045 (mm/s)" 2024 "-2048~2045 (mm/s)" 2025 "-2048~2045 (mm/s)" 2026 "-2048~2045 (mm/s)" 2027 "-2048~2045 (mm/s)" 2028 "-2048~2045 (mm/s)" 2029 "-2048~2045 (mm/s)" 2030 "-2048~2045 (mm/s)" 2031 "-2048~2045 (mm/s)" 2032 "-2048~2045 (mm/s)" 2033 "-2048~2045 (mm/s)" 2034 "-2048~2045 (mm/s)" 2035 "-2048~2045 (mm/s)" 2036 "-2048~2045 (mm/s)" 2037 "-2048~2045 (mm/s)" 2038 "-2048~2045 (mm/s)" 2039 "-2048~2045 (mm/s)" 2040 "-2048~2045 (mm/s)" 2041 "-2048~2045 (mm/s)" 2042 "-2048~2045 (mm/s)" 2043 "-2048~2045 (mm/s)" 2044 "-2048~2045 (mm/s)" 2045 "-2048~2045 (mm/s)" 2046 "-2048~2045 (mm/s)" 2047 "-2048~2045 (mm/s)" 2048 "-2048~2045 (mm/s)" 2049 "-2048~2045 (mm/s)" 2050 "-2048~2045 (mm/s)" 2051 "-2048~2045 (mm/s)" 2052 "-2048~2045 (mm/s)" 2053 "-2048~2045 (mm/s)" 2054 "-2048~2045 (mm/s)" 2055 "-2048~2045 (mm/s)" 2056 "-2048~2045 (mm/s)" 2057 "-2048~2045 (mm/s)" 2058 "-2048~2045 (mm/s)" 2059 "-2048~2045 (mm/s)" 2060 "-2048~2045 (mm/s)" 2061 "-2048~2045 (mm/s)" 2062 "-2048~2045 (mm/s)" 2063 "-2048~2045 (mm/s)" 2064 "-2048~2045 (mm/s)" 2065 "-2048~2045 (mm/s)" 2066 "-2048~2045 (mm/s)" 2067 "-2048~2045 (mm/s)" 2068 "-2048~2045 (mm/s)" 2069 "-2048~2045 (mm/s)" 2070 "-2048~2045 (mm/s)" 2071 "-2048~2045 (mm/s)" 2072 "-2048~2045 (mm/s)" 2073 "-2048~2045 (mm/s)" 2074 "-2048~2045 (mm/s)" 2075 "-2048~2045 (mm/s)" 2076 "-2048~2045 (mm/s)" 2077 "-2048~2045 (mm/s)" 2078 "-2048~2045 (mm/s)" 2079 "-2048~2045 (mm/s)" 2080 "-2048~2045 (mm/s)" 2081 "-2048~2045 (mm/s)" 2082 "-2048~2045 (mm/s)" 2083 "-2048~2045 (mm/s)" 2084 "-2048~2045 (mm/s)" 2085 "-2048~2045 (mm/s)" 2086 "-2048~2045 (mm/s)" 2087 "-2048~2045 (mm/s)" 2088 "-2048~2045 (mm/s)" 2089 "-2048~2045 (mm/s)" 2090 "-2048~2045 (mm/s)" 2091 "-2048~2045 (mm/s)" 2092 "-2048~2045 (mm/s)" 2093 "-2048~2045 (mm/s)" 2094 "-2048~2045 (mm/s)" 2095 "-2048~2045 (mm/s)" 2096 "-2048~2045 (mm/s)" 2097 "-2048~2045 (mm/s)" 2098 "-2048~2045 (mm/s)" 2099 "-2048~2045 (mm/s)" 2100 "-2048~2045 (mm/s)" 2101 "-2048~2045 (mm/s)" 2102 "-2048~2045 (mm/s)" 2103 "-2048~2045 (mm/s)" 2104 "-2048~2045 (mm/s)" 2105 "-2048~2045 (mm/s)" 2106 "-2048~2045 (mm/s)" 2107 "-2048~2045 (mm/s)" 2108 "-2048~2045 (mm/s)" 2109 "-2048~2045 (mm/s)" 2110 "-2048~2045 (mm/s)" 2111 "-2048~2045 (mm/s)" 2112 "-2048~2045 (mm/s)" 2113 "-2048~2045 (mm/s)" 2114 "-2048~2045 (mm/s)" 2115 "-2048~2045 (mm/s)" 2116 "-2048~2045 (mm/s)" 2117 "-2048~2045 (mm/s)" 2118 "-2048~2045 (mm/s)" 2119 "-2048~2045 (mm/s)" 2120 "-2048~2045 (mm/s)" 2121 "-2048~2045 (mm/s)" 2122 "-2048~2045 (mm/s)" 2123 "-2048~2045 (mm/s)" 2124 "-2048~2045 (mm/s)" 2125 "-2048~2045 (mm/s)" 2126 "-2048~2045 (mm/s)" 2127 "-2048~2045 (mm/s)" 2128 "-2048~2045 (mm/s)" 2129 "-2048~2045 (mm/s)" 2130 "-2048~2045 (mm/s)" 2131 "-2048~2045 (mm/s)" 2132 "-2048~2045 (mm/s)" 2133 "-2048~2045 (mm/s)" 2134 "-2048~2045 (mm/s)" 2135 "-2048~2045 (mm/s)" 2136 "-2048~2045 (mm/s)" 2137 "-2048~2045 (mm/s)" 2138 "-2048~2045 (mm/s)" 2139 "-2048~2045 (mm/s)" 2140 "-2048~2045 (mm/s)" 2141 "-2048~2045 (mm/s)" 2142 "-2048~2045 (mm/s)" 2143 "-2048~2045 (mm/s)" 2144 "-2048~2045 (mm/s)" 2145 "-2048~2045 (mm/s)" 2146 "-2048~2045 (mm/s)" 2147 "-2048~2045 (mm/s)" 2148 "-2048~2045 (mm/s)" 2149 "-2048~2045 (mm/s)" 2150 "-2048~2045 (mm/s)" 2151 "-2048~2045 (mm/s)" 2152 "-2048~2045 (mm/s)" 2153 "-2048~2045 (mm/s)" 2154 "-2048~2045 (mm/s)" 2155 "-2048~2045 (mm/s)" 2156 "-2048~2045 (mm/s)" 2157 "-2048~2045 (mm/s)" 2158 "-2048~2045 (mm/s)" 2159 "-2048~2045 (mm/s)" 2160 "-2048~2045 (mm/s)" 2161 "-2048~2045 (mm/s)" 2162 "-2048~2045 (mm/s)" 2163 "-2048~2045 (mm/s)" 2164 "-2048~2045 (mm/s)" 2165 "-2048~2045 (mm/s)" 2166 "-2048~2045 (mm/s)" 2167 "-2048~2045 (mm/s)" 2168 "-2048~2045 (mm/s)" 2169 "-2048~2045 (mm/s)" 2170 "-2048~2045 (mm/s)" 2171 "-2048~2045 (mm/s)" 2172 "-2048~2045 (mm/s)" 2173 "-2048~2045 (mm/s)" 2174 "-2048~2045 (mm/s)" 2175 "-2048~2045 (mm/s)" 2176 "-2048~2045 (mm/s)" 2177 "-2048~2045 (mm/s)" 2178 "-2048~2045 (mm/s)" 2179 "-2048~2045 (mm/s)" 2180 "-2048~2045 (mm/s)" 2181 "-2048~2045 (mm/s)" 2182 "-2048~2045 (mm/s)" 2183 "-2048~2045 (mm/s)" 2184 "-2048~2045 (mm/s)" 2185 "-2048~2045 (mm/s)" 2186 "-2048~2045 (mm/s)" 2187 "-2048~2045 (mm/s)" 2188 "-2048~2045 (mm/s)" 2189 "-2048~2045 (mm/s)" 2190 "-2048~2045 (mm/s)" 2191 "-2048~2045 (mm/s)" 2192 "-2048~2045 (mm/s)" 2193 "-2048~2045 (mm/s)" 2194 "-2048~2045 (mm/s)" 2195 "-2048~2045 (mm/s)" 2196 "-2048~2045 (mm/s)" 2197 "-2048~2045 (mm/s)" 2198 "-2048~2045 (mm/s)" 2199 "-2048~2045 (mm/s)" 2200 "-2048~2045 (mm/s)" 2201 "-2048~2045 (mm/s)" 2202 "-2048~2045 (mm/s)" 2203 "-2048~2045 (mm/s)" 2204 "-2048~2045 (mm/s)" 2205 "-2048~2045 (mm/s)" 2206 "-2048~2045 (mm/s)" 2207 "-2048~2045 (mm/s)" 2208 "-2048~2045 (mm/s)" 2209 "-2048~2045 (mm/s)" 2210 "-2048~2045 (mm/s)" 2211 "-2048~2045 (mm/s)" 2212 "-2048~2045 (mm/s)" 2213 "-2048~2045 (mm/s)" 2214 "-2048~2045 (mm/s)" 2215 "-2048~2045 (mm/s)" 2216 "-2048~2045 (mm/s)" 2217 "-2048~2045 (mm/s)" 2218 "-2048~2045 (mm/s)" 2219 "-2048~2045 (mm/s)" 2220 "-2048~2045 (mm/s)" 2221 "-2048~2045 (mm/s)" 2222 "-2048~2045 (mm/s)" 2223 "-2048~2045 (mm/s)" 2224 "-2048~2045 (mm/s)" 2225 "-2048~2045 (mm/s)" 2226 "-2048~2045 (mm/s)" 2227 "-2048~2045 (mm/s)" 2228 "-2048~2045 (mm/s)" 2229 "-2048~2045 (mm/s)" 2230 "-2048~2045 (mm/s)" 2231 "-2048~2045 (mm/s)" 2232 "-2048~2045 (mm/s)" 2233 "-2048~2045 (mm/s)" 2234 "-2048~2045 (mm/s)" 2235 "-2048~2045 (mm/s)" 2236 "-2048~2045 (mm/s)" 2237 "-2048~2045 (mm/s)" 2238 "-2048~2045 (mm/s)" 2239 "-2048~2045 (mm/s)" 2240 "-2048~2045 (mm/s)" 2241 "-2048~2045 (mm/s)" 2242 "-2048~2045 (mm/s)" 2243 "-2048~2045 (mm/s)" 2244 "-2048~2045 (mm/s)" 2245 "-2048~2045 (mm/s)" 2246 "-2048~2045 (mm/s)" 2247 "-2048~2045 (mm/s)" 2248 "-2048~2045 (mm/s)" 2249 "-2048~2045 (mm/s)" 2250 "-2048~2045 (mm/s)" 2251 "-2048~2045 (mm/s)" 2252 "-2048~2045 (mm/s)" 2253 "-2048~2045 (mm/s)" 2254 "-2048~2045 (mm/s)" 2255 "-2048~2045 (mm/s)" 2256 "-2048~2045 (mm/s)" 2257 "-2048~2045 (mm/s)" 2258 "-2048~2045 (mm/s)" 2259 "-2048~2045 (mm/s)" 2260 "-2048~2045 (mm/s)" 2261 "-2048~2045 (mm/s)" 2262 "-2048~2045 (mm/s)" 2263 "-2048~2045 (mm/s)" 2264 "-2048~2045 (mm/s)" 2265 "-2048~2045 (mm/s)" 2266 "-2048~2045 (mm/s)" 2267 "-2048~2045 (mm/s)" 2268 "-2048~2045 (mm/s)" 2269 "-2048~2045 (mm/s)" 2270 "-2048~2045 (mm/s)" 2271 "-2048~2045 (mm/s)" 2272 "-2048~2045 (mm/s)" 2273 "-2048~2045 (mm/s)" 2274 "-2048~2045 (mm/s)" 2275 "-2048~2045 (mm/s)" 2276 "-2048~2045 (mm/s)" 2277 "-2048~2045 (mm/s)" 2278 "-2048~2045 (mm/s)" 2279 "-2048~2045 (mm/s)" 2280 "-2048~2045 (mm/s)" 2281 "-2048~2045 (mm/s)" 2282 "-2048~2045 (mm/s)" 2283 "-2048~2045 (mm/s)" 2284 "-2048~2045 (mm/s)" 2285 "-2048~2045 (mm/s)" 2286 "-2048~2045 (mm/s)" 2287 "-2048~2045 (mm/s)" 2288 "-2048~2045 (mm/s)" 2289 "-2048~2045 (mm/s)" 2290 "-2048~2045 (mm/s)" 2291 "-2048~2045 (mm/s)" 2292 "-2048~2045 (mm/s)" 2293 "-2048~2045 (mm/s)" 2294 "-2048~2045 (mm/s)" 2295 "-2048~2045 (mm/s)" 2296 "-2048~2045 (mm/s)" 2297 "-2048~2045 (mm/s)" 2298 "-2048~2045 (mm/s)" 2299 "-2048~2045 (mm/s)" 2300 "-2048~2045 (mm/s)" 2301 "-2048~2045 (mm/s)" 2302 "-2048~2045 (mm/s)" 2303 "-2048~2045 (mm/s)" 2304 "-2048~2045 (mm/s)" 2305 "-2048~2045 (mm/s)" 2306 "-2048~2045 (mm/s)" 2307 "-2048~2045 (mm/s)" 2308 "-2048~2045 (mm/s)" 2309 "-2048~2045 (mm/s)" 2310 "-2048~2045 (mm/s)" 2311 "-2048~2045 (mm/s)" 2312 "-2048~2045 (mm/s)" 2313 "-2048~2045 (mm/s)" 2314 "-2048~2045 (mm/s)" 2315 "-2048~2045 (mm/s)" 2316 "-2048~2045 (mm/s)" 2317 "-2048~2045 (mm/s)" 2318 "-2048~2045 (mm/s)" 2319 "-2048~2045 (mm/s)" 2320 "-2048~2045 (mm/s)" 2321 "-2048~2045 (mm/s)" 2322 "-2048~2045 (mm/s)" 2323 "-2048~2045 (mm/s)" 2324 "-2048~2045 (mm/s)" 2325 "-2048~2045 (mm/s)" 2326 "-2048~2045 (mm/s)" 2327 "-2048~2045 (mm/s)" 2328 "-2048~2045 (mm/s)" 2329 "-2048~2045 (mm/s)" 2330 "-2048~2045 (mm/s)" 2331 "-2048~2045 (mm/s)" 2332 "-2048~2045 (mm/s)" 2333 "-2048~2045 (mm/s)" 2334 "-2048~2045 (mm/s)" 2335 "-2048~2045 (mm/s)" 2336 "-2048~2045 (mm/s)" 2337 "-2048~2045 (mm/s)" 2338 "-2048~2045 (mm/s)" 2339 "-2048~2045 (mm/s)" 2340 "-2048~2045 (mm/s)" 2341 "-2048~2045 (mm/s)" 2342 "-2048~2045 (mm/s)" 2343 "-2048~2045 (mm/s)" 2344 "-2048~2045 (mm/s)" 2345 "-2048~2045 (mm/s)" 2346 "-2048~2045 (mm/s)" 2347 "-2048~2045 (mm/s)" 2348 "-2048~2045 (mm/s)" 2349 "-2048~2045 (mm/s)" 2350 "-2048~2045 (mm/s)" 2351 "-2048~2045 (mm/s)" 2352 "-2048~2045 (mm/s)" 2353 "-2048~2045 (mm/s)" 2354 "-2048~2045 (mm/s)" 2355 "-2048~2045 (mm/s)" 2356 "-2048~2045 (mm/s)" 2357 "-2048~2045 (mm/s)" 2358 "-2048~2045 (mm/s)" 2359 "-2048~2045 (mm/s)" 2360 "-2048~2045 (mm/s)" 2361 "-2048~2045 (mm/s)" 2362 "-2048~2045 (mm/s)" 2363 "-2048~2045 (mm/s)" 2364 "-2048~2045 (mm/s)" 2365 "-2048~2045 (mm/s)" 2366 "-2048~2045 (mm/s)" 2367 "-2048~2045 (mm/s)" 2368 "-2048~2045 (mm/s)" 2369 "-2048~2045 (mm/s)" 2370 "-2048~2045 (mm/s)" 2371 "-2048~2045 (mm/s)" 2372 "-2048~2045 (mm/s)" 2373 "-2048~2045 (mm/s)" 2374 "-2048~2045 (mm/s)" 2375 "-2048~2045 (mm/s)" 2376 "-2048~2045 (mm/s)" 2377 "-2048~2045 (mm/s)" 2378 "-2048~2045 (mm/s)" 2379 "-2048~2045 (mm/s)" 2380 "-2048~2045 (mm/s)" 2381 "-2048~2045 (mm/s)" 2382 "-2048~2045 (mm/s)" 2383 "-2048~2045 (mm/s)" 2384 "-2048~2045 (mm/s)" 2385 "-2048~2045 (mm/s)" 2386 "-2048~2045 (mm/s)" 2387 "-2048~2045 (mm/s)" 2388 "-2048~2045 (mm/s)" 2389 "-2048~2045 (mm/s)" 2390 "-2048~2045 (mm/s)" 2391 "-2048~2045 (mm/s)" 2392 "-2048~2045 (mm/s)" 2393 "-2048~2045 (mm/s)" 2394 "-2048~2045 (mm/s)" 2395 "-2048~2045 (mm/s)" 2396 "-2048~2045 (mm/s)" 2397 "-2048~2045 (mm/s)" 2398 "-2048~2045 (mm/s)" 2399 "-2048~2045 (mm/s)" 2400 "-2048~2045 (mm/s)" 2401 "-2048~2045 (mm/s)" 2402 "-2048~2045 (mm/s)" 2403 "-2048~2045 (mm/s)" 2404 "-2048~2045 (mm/s)" 2405 "-2048~2045 (mm/s)" 2406 "-2048~2045 (mm/s)" 2407 "-2048~2045 (mm/s)" 2408 "-2048~2045 (mm/s)" 2409 "-2048~2045 (mm/s)" 2410 "-2048~2045 (mm/s)" 2411 "-2048~2045 (mm/s)" 2412 "-2048~2045 (mm/s)" 2413 "-2048~2045 (mm/s)" 2414 "-2048~2045 (mm/s)" 2415 "-2048~2045 (mm/s)" 2416 "-2048~2045 (mm/s)" 2417 "-2048~2045 (mm/s)" 2418 "-2048~2045 (mm/s)" 2419 "-2048~2045 (mm/s)" 2420 "-2048~2045 (mm/s)" 2421 "-2048~2045 (mm/s)" 2422 "-2048~2045 (mm/s)" 2423 "-2048~2045 (mm/s)" 2424 "-2048~2045 (mm/s)" 2425 "-2048~2045 (mm/s)" 2426 "-2048~2045 (mm/s)" 2427 "-2048~2045 (mm/s)" 2428 "-2048~2045 (mm/s)" 2429 "-2048~2045 (mm/s)" 2430 "-2048~2045 (mm/s)" 2431 "-2048~2045 (mm/s)" 2432 "-2048~2045 (mm/s)" 2433 "-2048~2045 (mm/s)" 2434 "-2048~2045 (mm/s)" 2435 "-2048~2045 (mm/s)" 2436 "-2048~2045 (mm/s)" 2437 "-2048~2045 (mm/s)" 2438 "-2048~2045 (mm/s)" 2439 "-2048~2045 (mm/s)" 2440 "-2048~2045 (mm/s)" 2441 "-2048~2045 (mm/s)" 2442 "-2048~2045 (mm/s)" 2443 "-2048~2045 (mm/s)" 2444 "-2048~2045 (mm/s)" 2445 "-2048~2045 (mm/s)" 2446 "-2048~2045 (mm/s)" 2447 "-2048~2045 (mm/s)" 2448 "-2048~2045 (mm/s)" 2449 "-2048~2045 (mm/s)" 2450 "-2048~2045 (mm/s)" 2451 "-2048~2045 (mm/s)" 2452 "-2048~2045 (mm/s)" 2453 "-2048~2045 (mm/s)" 2454 "-2048~2045 (mm/s)" 2455 "-2048~2045 (mm/s)" 2456 "-2048~2045 (mm/s)" 2457 "-2048~2045 (mm/s)" 2458 "-2048~2045 (mm/s)" 2459 "-2048~2045 (mm/s)" 2460 "-2048~2045 (mm/s)" 2461 "-2048~2045 (mm/s)" 2462 "-2048~2045 (mm/s)" 2463 "-2048~2045 (mm/s)" 2464 "-2048~2045 (mm/s)" 2465 "-2048~2045 (mm/s)" 2466 "-2048~2045 (mm/s)" 2467 "-2048~2045 (mm/s)" 2468 "-2048~2045 (mm/s)" 2469 "-2048~2045 (mm/s)" 2470 "-2048~2045 (mm/s)" 2471 "-2048~2045 (mm/s)" 2472 "-2048~2045 (mm/s)" 2473 "-2048~2045 (mm/s)" 2474 "-2048~2045 (mm/s)" 2475 "-2048~2045 (mm/s)" 2476 "-2048~2045 (mm/s)" 2477 "-2048~2045 (mm/s)" 2478 "-2048~2045 (mm/s)" 2479 "-2048~2045 (mm/s)" 2480 "-2048~2045 (mm/s)" 2481 "-2048~2045 (mm/s)" 2482 "-2048~2045 (mm/s)" 2483 "-2048~2045 (mm/s)" 2484 "-2048~2045 (mm/s)" 2485 "-2048~2045 (mm/s)" 2486 "-2048~2045 (mm/s)" 2487 "-2048~2045 (mm/s)" 2488 "-2048~2045 (mm/s)" 2489 "-2048~2045 (mm/s)" 2490 "-2048~2045 (mm/s)" 2491 "-2048~2045 (mm/s)" 2492 "-2048~2045 (mm/s)" 2493 "-2048~2045 (mm/s)" 2494 "-2048~2045 (mm/s)" 2495 "-2048~2045 (mm/s)" 2496 "-2048~2045 (mm/s)" 2497 "-2048~2045 (mm/s)" 2498 "-2048~2045 (mm/s)" 2499 "-2048~2045 (mm/s)" 2500 "-2048~2045 (mm/s)" 2501 "-2048~2045 (mm/s)" 2502 "-2048~2045 (mm/s)" 2503 "-2048~2045 (mm/s)" 2504 "-2048~2045 (mm/s)" 2505 "-2048~2045 (mm/s)" 2506 "-2048~2045 (mm/s)" 2507 "-2048~2045 (mm/s)" 2508 "-2048~2045 (mm/s)" 2509 "-2048~2045 (mm/s)" 2510 "-2048~2045 (mm/s)" 2511 "-2048~2045 (mm/s)" 2512 "-2048~2045 (mm/s)" 2513 "-2048~2045 (mm/s)" 2514 "-2048~2045 (mm/s)" 2515 "-2048~2045 (mm/s)" 2516 "-2048~2045 (mm/s)" 2517 "-2048~2045 (mm/s)" 2518 "-2048~2045 (mm/s)" 2519 "-2048~2045 (mm/s)" 2520 "-2048~2045 (mm/s)" 2521 "-2048~2045 (mm/s)" 2522 "-2048~2045 (mm/s)" 2523 "-2048~2045 (mm/s)" 2524 "-2048~2045 (mm/s)" 2525 "-2048~2045 (mm/s)" 2526 "-2048~2045 (mm/s)" 2527 "-2048~2045 (mm/s)" 2528 "-2048~2045 (mm/s)" 2529 "-2048~2045 (mm/s)" 2530 "-2048~2045 (mm/s)" 2531 "-2048~2045 (mm/s)" 2532 "-2048~2045 (mm/s)" 2533 "-2048~2045 (mm/s)" 2534 "-2048~2045 (mm/s)" 2535 "-2048~2045 (mm/s)" 2536 "-2048~2045 (mm/s)" 2537 "-2048~2045 (mm/s)" 2538 "-2048~2045 (mm/s)" 2539 "-2048~2045 (mm/s)" 2540 "-2048~2045 (mm/s)" 2541 "-2048~2045 (mm/s)" 2542 "-2048~2045 (mm/s)" 2543 "-2048~2045 (mm/s)" 2544 "-2048~2045 (mm/s)" 2545 "-2048~2045 (mm/s)" 2546 "-2048~2045 (mm/s)" 2547 "-2048~2045 (mm/s)" 2548 "-2048~2045 (mm/s)" 2549 "-2048~2045 (mm/s)" 2550 "-2048~2045 (mm/s)" 2551 "-2048~2045 (mm/s)" 2552 "-2048~2045 (mm/s)" 2553 "-2048~2045 (mm/s)" 2554 "-2048~2045 (mm/s)" 2555 "-2048~2045 (mm/s)" 2556 "-2048~2045 (mm/s)" 2557 "-2048~2045 (mm/s)" 2558 "-2048~2045 (mm/s)" 2559 "-2048~2045 (mm/s)" 2560 "-2048~2045 (mm/s)" 2561 "-2048~2045 (mm/s)" 2562 "-2048~2045 (mm/s)" 2563 "-2048~2045 (mm/s)" 2564 "-2048~2045 (mm/s)" 2565 "-2048~2045 (mm/s)" 2566 "-2048~2045 (mm/s)" 2567 "-2048~2045 (mm/s)" 2568 "-2048~2045 (mm/s)" 2569 "-2048~2045 (mm/s)" 2570 "-2048~2045 (mm/s)" 2571 "-2048~2045 (mm/s)" 2572 "-2048~2045 (mm/s)" 2573 "-2048~2045 (mm/s)" 2574 "-2048~2045 (mm/s)" 2575 "-2048~2045 (mm/s)" 2576 "-2048~2045 (mm/s)" 2577 "-2048~2045 (mm/s)" 2578 "-2048~2045 (mm/s)" 2579 "-2048~2045 (mm/s)" 2580 "-2048~2045 (mm/s)" 2581 "-2048~2045 (mm/s)" 2582 "-2048~2045 (mm/s)" 2583 "-2048~2045 (mm/s)" 2584 "-2048~2045 (mm/s)" 2585 "-2048~2045 (mm/s)" 2586 "-2048~2045 (mm/s)" 2587 "-2048~2045 (mm/s)" 2588 "-2048~2045 (mm/s)" 2589 "-2048~2045 (mm/s)" 2590 "-2048~2045 (mm/s)" 2591 "-2048~2045 (mm/s)" 2592 "-2048~2045 (mm/s)" 2593 "-2048~2045 (mm/s)" 2594 "-2048~2045 (mm/s)" 2595 "-2048~2045 (mm/s)" 2596 "-2048~2045 (mm/s)" 2597 "-2048~2045 (mm/s)" 2598 "-2048~2045 (mm/s)" 2599 "-2048~2045 (mm/s)" 2600 "-2048~2045 (mm/s)" 2601 "-2048~2045 (mm/s)" 2602 "-2048~2045 (mm/s)" 2603 "-2048~2045 (mm/s)" 2604 "-2048~2045 (mm/s)" 2605 "-2048~2045 (mm/s)" 2606 "-2048~2045 (mm/s)" 2607 "-2048~2045 (mm/s)" 2608 "-2048~2045 (mm/s)" 2609 "-2048~2045 (mm/s)" 2610 "-2048~2045 (mm/s)" 2611 "-2048~2045 (mm/s)" 2612 "-2048~2045 (mm/s)" 2613 "-2048~2045 (mm/s)" 2614 "-2048~2045 (mm/s)" 2615 "-2048~2045 (mm/s)" 2616 "-2048~2045 (mm/s)" 2617 "-2048~2045 (mm/s)" 2618 "-2048~2045 (mm/s)" 2619 "-2048~2045 (mm/s)" 2620 "-2048~2045 (mm/s)" 2621 "-2048~2045 (mm/s)" 2622 "-2048~2045 (mm/s)" 2623 "-2048~2045 (mm/s)" 2624 "-2048~2045 (mm/s)" 2625 "-2048~2045 (mm/s)" 2626 "-2048~2045 (mm/s)" 2627 "-2048~2045 (mm/s)" 2628 "-2048~2045 (mm/s)" 2629 "-2048~2045 (mm/s)" 2630 "-2048~2045 (mm/s)" 2631 "-2048~2045 (mm/s)" 2632 "-2048~2045 (mm/s)" 2633 "-2048~2045 (mm/s)" 2634 "-2048~2045 (mm/s)" 2635 "-2048~2045 (mm/s)" 2636 "-2048~2045 (mm/s)" 2637 "-2048~2045 (mm/s)" 2638 "-2048~2045 (mm/s)" 2639 "-2048~2045 (mm/s)" 2640 "-2048~2045 (mm/s)" 2641 "-2048~2045 (mm/s)" 2642 "-2048~2045 (mm/s)" 2643 "-2048~2045 (mm/s)" 2644 "-2048~2045 (mm/s)" 2645 "-2048~2045 (mm/s)" 2646 "-2048~2045 (mm/s)" 2647 "-2048~2045 (mm/s)" 2648 "-2048~2045 (mm/s)" 2649 "-2048~2045 (mm/s)" 2650 "-2048~2045 (mm/s)" 2651 "-2048~2045 (mm/s)" 2652 "-2048~2045 (mm/s)" 2653 "-2048~2045 (mm/s)" 2654 "-2048~2045 (mm/s)" 2655 "-2048~2045 (mm/s)" 2656 "-2048~2045 (mm/s)" 2657 "-2048~2045 (mm/s)" 2658 "-2048~2045 (mm/s)" 2659 "-2048~2045 (mm/s)" 2660 "-2048~2045 (mm/s)" 2661 "-2048~2045 (mm/s)" 2662 "-2048~2045 (mm/s)" 2663 "-2048~2045 (mm/s)" 2664 "-2048~2045 (mm/s)" 2665 "-2048~2045 (mm/s)" 2666 "-2048~2045 (mm/s)" 2667 "-2048~2045 (mm/s)" 2668 "-2048~2045 (mm/s)" 2669 "-2048~2045 (mm/s)" 2670 "-2048~2045 (mm/s)" 2671 "-2048~2045 (mm/s)" 2672 "-2048~2045 (mm/s)" 2673 "-2048~2045 (mm/s)" 2674 "-2048~2045 (mm/s)" 2675 "-2048~2045 (mm/s)" 2676 "-2048~2045 (mm/s)" 2677 "-2048~2045 (mm/s)" 2678 "-2048~2045 (mm/s)" 2679 "-2048~2045 (mm/s)" 2680 "-2048~2045 (mm/s)" 2681 "-2048~2045 (mm/s)" 2682 "-2048~2045 (mm/s)" 2683 "-2048~2045 (mm/s)" 2684 "-2048~2045 (mm/s)" 2685 "-2048~2045 (mm/s)" 2686 "-2048~2045 (mm/s)" 2687 "-2048~2045 (mm/s)" 2688 "-2048~2045 (mm/s)" 2689 "-2048~2045 (mm/s)" 2690 "-2048~2045 (mm/s)" 2691 "-2048~2045 (mm/s)" 2692 "-2048~2045 (mm/s)" 2693 "-2048~2045 (mm/s)" 2694 "-2048~2045 (mm/s)" 2695 "-2048~2045 (mm/s)" 2696 "-2048~2045 (mm/s)" 2697 "-2048~2045 (mm/s)" 2698 "-2048~2045 (mm/s)" 2699 "-2048~2045 (mm/s)" 2700 "-2048~2045 (mm/s)" 2701 "-2048~2045 (mm/s)" 2702 "-2048~2045 (mm/s)" 2703 "-2048~2045 (mm/s)" 2704 "-2048~2045 (mm/s)" 2705 "-2048~2045 (mm/s)" 2706 "-2048~2045 (mm/s)" 2707 "-2048~2045 (mm/s)" 2708 "-2048~2045 (mm/s)" 2709 "-2048~2045 (mm/s)" 2710 "-2048~2045 (mm/s)" 2711 "-2048~2045 (mm/s)" 2712 "-2048~2045 (mm/s)" 2713 "-2048~2045 (mm/s)" 2714 "-2048~2045 (mm/s)" 2715 "-2048~2045 (mm/s)" 2716 "-2048~2045 (mm/s)" 2717 "-2048~2045 (mm/s)" 2718 "-2048~2045 (mm/s)" 2719 "-2048~2045 (mm/s)" 2720 "-2048~2045 (mm/s)" 2721 "-2048~2045 (mm/s)" 2722 "-2048~2045 (mm/s)" 2723 "-2048~2045 (mm/s)" 2724 "-2048~2045 (mm/s)" 2725 "-2048~2045 (mm/s)" 2726 "-2048~2045 (mm/s)" 2727 "-2048~2045 (mm/s)" 2728 "-2048~2045 (mm/s)" 2729 "-2048~2045 (mm/s)" 2730 "-2048~2045 (mm/s)" 2731 "-2048~2045 (mm/s)" 2732 "-2048~2045 (mm/s)" 2733 "-2048~2045 (mm/s)" 2734 "-2048~2045 (mm/s)" 2735 "-2048~2045 (mm/s)" 2736 "-2048~2045 (mm/s)" 2737 "-2048~2045 (mm/s)" 2738 "-2048~2045 (mm/s)" 2739 "-2048~2045 (mm/s)" 2740 "-2048~2045 (mm/s)" 2741 "-2048~2045 (mm/s)" 2742 "-2048~2045 (mm/s)" 2743 "-2048~2045 (mm/s)" 2744 "-2048~2045 (mm/s)" 2745 "-2048~2045 (mm/s)" 2746 "-2048~2045 (mm/s)" 2747 "-2048~2045 (mm/s)" 2748 "-2048~2045 (mm/s)" 2749 "-2048~2045 (mm/s)" 2750 "-2048~2045 (mm/s)" 2751 "-2048~2045 (mm/s)" 2752 "-2048~2045 (mm/s)" 2753 "-2048~2045 (mm/s)" 2754 "-2048~2045 (mm/s)" 2755 "-2048~2045 (mm/s)" 2756 "-2048~2045 (mm/s)" 2757 "-2048~2045 (mm/s)" 2758 "-2048~2045 (mm/s)" 2759 "-2048~2045 (mm/s)" 2760 "-2048~2045 (mm/s)" 2761 "-2048~2045 (mm/s)" 2762 "-2048~2045 (mm/s)" 2763 "-2048~2045 (mm/s)" 2764 "-2048~2045 (mm/s)" 2765 "-2048~2045 (mm/s)" 2766 "-2048~2045 (mm/s)" 2767 "-2048~2045 (mm/s)" 2768 "-2048~2045 (mm/s)" 2769 "-2048~2045 (mm/s)" 2770 "-2048~2045 (mm/s)" 2771 "-2048~2045 (mm/s)" 2772 "-2048~2045 (mm/s)" 2773 "-2048~2045 (mm/s)" 2774 "-2048~2045 (mm/s)" 2775 "-2048~2045 (mm/s)" 2776 "-2048~2045 (mm/s)" 2777 "-2048~2045 (mm/s)" 2778 "-2048~2045 (mm/s)" 2779 "-2048~2045 (mm/s)" 2780 "-2048~2045 (mm/s)" 2781 "-2048~2045 (mm/s)" 2782 "-2048~2045 (mm/s)" 2783 "-2048~2045 (mm/s)" 2784 "-2048~2045 (mm/s)" 2785 "-2048~2045 (mm/s)" 2786 "-2048~2045 (mm/s)" 2787 "-2048~2045 (mm/s)" 2788 "-2048~2045 (mm/s)" 2789 "-2048~2045 (mm/s)" 2790 "-2048~2045 (mm/s)" 2791 "-2048~2045 (mm/s)" 2792 "-2048~2045 (mm/s)" 2793 "-2048~2045 (mm/s)" 2794 "-2048~2045 (mm/s)" 2795 "-2048~2045 (mm/s)" 2796 "-2048~2045 (mm/s)" 2797 "-2048~2045 (mm/s)" 2798 "-2048~2045 (mm/s)" 2799 "-2048~2045 (mm/s)" 2800 "-2048~2045 (mm/s)" 2801 "-2048~2045 (mm/s)" 2802 "-2048~2045 (mm/s)" 2803 "-2048~2045 (mm/s)" 2804 "-2048~2045 (mm/s)" 2805 "-2048~2045 (mm/s)" 2806 "-2048~2045 (mm/s)" 2807 "-2048~2045 (mm/s)" 2808 "-2048~2045 (mm/s)" 2809 "-2048~2045 (mm/s)" 2810 "-2048~2045 (mm/s)" 2811 "-2048~2045 (mm/s)" 2812 "-2048~2045 (mm/s)" 2813 "-2048~2045 (mm/s)" 2814 "-2048~2045 (mm/s)" 2815 "-2048~2045 (mm/s)" 2816 "-2048~2045 (mm/s)" 2817 "-2048~2045 (mm/s)" 2818 "-2048~2045 (mm/s)" 2819 "-2048~2045 (mm/s)" 2820 "-2048~2045 (mm/s)" 2821 "-2048~2045 (mm/s)" 2822 "-2048~2045 (mm/s)" 2823 "-2048~2045 (mm/s)" 2824 "-2048~2045 (mm/s)" 2825 "-2048~2045 (mm/s)" 2826 "-2048~2045 (mm/s)" 2827 "-2048~2045 (mm/s)" 2828 "-2048~2045 (mm/s)" 2829 "-2048~2045 (mm/s)" 2830 "-2048~2045 (mm/s)" 2831 "-2048~2045 (mm/s)" 2832 "-2048~2045 (mm/s)" 2833 "-2048~2045 (mm/s)" 2834 "-2048~2045 (mm/s)" 2835 "-2048~2045 (mm/s)" 2836 "-2048~2045 (mm/s)" 2837 "-2048~2045 (mm/s)" 2838 "-2048~2045 (mm/s)" 2839 "-2048~2045 (mm/s)" 2840 "-2048~2045 (mm/s)" 2841 "-2048~2045 (mm/s)" 2842 "-2048~2045 (mm/s)" 2843 "-2048~2045 (mm/s)" 2844 "-2048~2045 (mm/s)" 2845 "-2048~2045 (mm/s)" 2846 "-2048~2045 (mm/s)" 2847 "-2048~2045 (mm/s)" 2848 "-2048~2045 (mm/s)" 2849 "-2048~2045 (mm/s)" 2850 "-2048~2045 (mm/s)" 2851 "-2048~2045 (mm/s)" 2852 "-2048~2045 (mm/s)" 2853 "-2048~2045 (mm/s)" 2854 "-2048~2045 (mm/s)" 2855 "-2048~2045 (mm/s)" 2856 "-2048~2045 (mm/s)" 2857 "-2048~2045 (mm/s)" 2858 "-2048~2045 (mm/s)" 2859 "-2048~2045 (mm/s)" 2860 "-2048~2045 (mm/s)" 2861 "-2048~2045 (mm/s)" 2862 "-2048~2045 (mm/s)" 2863 "-2048~2045 (mm/s)" 2864 "-2048~2045 (mm/s)" 2865 "-2048~2045 (mm/s)" 2866 "-2048~2045 (mm/s)" 2867 "-2048~2045 (mm/s)" 2868 "-2048~2045 (mm/s)" 2869 "-2048~2045 (mm/s)" 2870 "-2048~2045 (mm/s)" 2871 "-2048~2045 (mm/s)" 2872 "-2048~2045 (mm/s)" 2873 "-2048~2045 (mm/s)" 2874 "-2048~2045 (mm/s)" 2875 "-2048~2045 (mm/s)" 2876 "-2048~2045 (mm/s)" 2877 "-2048~2045 (mm/s)" 2878 "-2048~2045 (mm/s)" 2879 "-2048~2045 (mm/s)" 2880 "-2048~2045 (mm/s)" 2881 "-2048~2045 (mm/s)" 2882 "-2048~2045 (mm/s)" 2883 "-2048~2045 (mm/s)" 2884 "-2048~2045 (mm/s)" 2885 "-2048~2045 (mm/s)" 2886 "-2048~2045 (mm/s)" 2887 "-2048~2045 (mm/s)" 2888 "-2048~2045 (mm/s)" 2889 "-2048~2045 (mm/s)" 2890 "-2048~2045 (mm/s)" 2891 "-2048~2045 (mm/s)" 2892 "-2048~2045 (mm/s)" 2893 "-2048~2045 (mm/s)" 2894 "-2048~2045 (mm/s)" 2895 "-2048~2045 (mm/s)" 2896 "-2048~2045 (mm/s)" 2897 "-2048~2045 (mm/s)" 2898 "-2048~2045 (mm/s)" 2899 "-2048~2045 (mm/s)" 2900 "-2048~2045 (mm/s)" 2901 "-2048~2045 (mm/s)" 2902 "-2048~2045 (mm/s)" 2903 "-2048~2045 (mm/s)" 2904 "-2048~2045 (mm/s)" 2905 "-2048~2045 (mm/s)" 2906 "-2048~2045 (mm/s)" 2907 "-2048~2045 (mm/s)" 2908 "-2048~2045 (mm/s)" 2909 "-2048~2045 (mm/s)" 2910 "-2048~2045 (mm/s)" 2911 "-2048~2045 (mm/s)" 2912 "-2048~2045 (mm/s)" 2913 "-2048~2045 (mm/s)" 2914 "-2048~2045 (mm/s)" 2915 "-2048~2045 (mm/s)" 2916 "-2048~2045 (mm/s)" 2917 "-2048~2045 (mm/s)" 2918 "-2048~2045 (mm/s)" 2919 "-2048~2045 (mm/s)" 2920 "-2048~2045 (mm/s)" 2921 "-2048~2045 (mm/s)" 2922 "-2048~2045 (mm/s)" 2923 "-2048~2045 (mm/s)" 2924 "-2048~2045 (mm/s)" 2925 "-2048~2045 (mm/s)" 2926 "-2048~2045 (mm/s)" 2927 "-2048~2045 (mm/s)" 2928 "-2048~2045 (mm/s)" 2929 "-2048~2045 (mm/s)" 2930 "-2048~2045 (mm/s)" 2931 "-2048~2045 (mm/s)" 2932 "-2048~2045 (mm/s)" 2933 "-2048~2045 (mm/s)" 2934 "-2048~2045 (mm/s)" 2935 "-2048~2045 (mm/s)" 2936 "-2048~2045 (mm/s)" 2937 "-2048~2045 (mm/s)" 2938 "-2048~2045 (mm/s)" 2939 "-2048~2045 (mm/s)" 2940 "-2048~2045 (mm/s)" 2941 "-2048~2045 (mm/s)" 2942 "-2048~2045 (mm/s)" 2943 "-2048~2045 (mm/s)" 2944 "-2048~2045 (mm/s)" 2945 "-2048~2045 (mm/s)" 2946 "-2048~2045 (mm/s)" 2947 "-2048~2045 (mm/s)" 2948 "-2048~2045 (mm/s)" 2949 "-2048~2045 (mm/s)" 2950 "-2048~2045 (mm/s)" 2951 "-2048~2045 (mm/s)" 2952 "-2048~2045 (mm/s)" 2953 "-2048~2045 (mm/s)" 2954 "-2048~2045 (mm/s)" 2955 "-2048~2045 (mm/s)" 2956 "-2048~2045 (mm/s)" 2957 "-2048~2045 (mm/s)" 2958 "-2048~2045 (mm/s)" 2959 "-2048~2045 (mm/s)" 2960 "-2048~2045 (mm/s)" 2961 "-2048~2045 (mm/s)" 2962 "-2048~2045 (mm/s)" 2963 "-2048~2045 (mm/s)" 2964 "-2048~2045 (mm/s)" 2965 "-2048~2045 (mm/s)" 2966 "-2048~2045 (mm/s)" 2967 "-2048~2045 (mm/s)" 2968 "-2048~2045 (mm/s)" 2969 "-2048~2045 (mm/s)" 2970 "-2048~2045 (mm/s)" 2971 "-2048~2045 (mm/s)" 2972 "-2048~2045 (mm/s)" 2973 "-2048~2045 (mm/s)" 2974 "-2048~2045 (mm/s)" 2975 "-2048~2045 (mm/s)" 2976 "-2048~2045 (mm/s)" 2977 "-2048~2045 (mm/s)" 2978 "-2048~2045 (mm/s)" 2979 "-2048~2045 (mm/s)" 2980 "-2048~2045 (mm/s)" 2981 "-2048~2045 (mm/s)" 2982 "-2048~2045 (mm/s)" 2983 "-2048~2045 (mm/s)" 2984 "-2048~2045 (mm/s)" 2985 "-2048~2045 (mm/s)" 2986 "-2048~2045 (mm/s)" 2987 "-2048~2045 (mm/s)" 2988 "-2048~2045 (mm/s)" 2989 "-2048~2045 (mm/s)" 2990 "-2048~2045 (mm/s)" 2991 "-2048~2045 (mm/s)" 2992 "-2048~2045 (mm/s)" 2993 "-2048~2045 (mm/s)" 2994 "-2048~2045 (mm/s)" 2995 "-2048~2045 (mm/s)" 2996 "-2048~2045 (mm/s)" 2997 "-2048~2045 (mm/s)" 2998 "-2048~2045 (mm/s)" 2999 "-2048~2045 (mm/s)" 3000 "-2048~2045 (mm/s)" 3001 "-2048~2045 (mm/s)" 3002 "-2048~2045 (mm/s)" 3003 "-2048~2045 (mm/s)" 3004 "-2048~2045 (mm/s)" 3005 "-2048~2045 (mm/s)" 3006 "-2048~2045 (mm/s)" 3007 "-2048~2045 (mm/s)" 3008 "-2048~2045 (mm/s)" 3009 "-2048~2045 (mm/s)" 3010 "-2048~2045 (mm/s)" 3011 "-2048~2045 (mm/s)" 3012 "-2048~2045 (mm/s)" 3013 "-2048~2045 (mm/s)" 3014 "-2048~2045 (mm/s)" 3015 "-2048~2045 (mm/s)" 3016 "-2048~2045 (mm/s)" 3017 "-2048~2045 (mm/s)" 3018 "-2048~2045 (mm/s)" 3019 "-2048~2045 (mm/s)" 3020 "-2048~2045 (mm/s)" 3021 "-2048~2045 (mm/s)" 3022 "-2048~2045 (mm/s)" 3023 "-2048~2045 (mm/s)" 3024 "-2048~2045 (mm/s)" 3025 "-2048~2045 (mm/s)" 3026 "-2048~2045 (mm/s)" 3027 "-2048~2045 (mm/s)" 3028 "-2048~2045 (mm/s)" 3029 "-2048~2045 (mm/s)" 3030 "-2048~2045 (mm/s)" 3031 "-2048~2045 (mm/s)" 3032 "-2048~2045 (mm/s)" 3033 "-2048~2045 (mm/s)" 3034 "-2048~2045 (mm/s)" 3035 "-2048~2045 (mm/s)" 3036 "-2048~2045 (mm/s)" 3037 "-2048~2045 (mm/s)" 3038 "-2048~2045 (mm/s)" 3039 "-2048~2045 (mm/s)" 3040 "-2048~2045 (mm/s)" 3041 "-2048~2045 (mm/s)" 3042 "-2048~2045 (mm/s)" 3043 "-2048~2045 (mm/s)" 3044 "-2048~2045 (mm/s)" 3045 "-2048~2045 (mm/s)" 3046 "-2048~2045 (mm/s)" 3047 "-2048~2045 (mm/s)" 3048 "-2048~2045 (mm/s)" 3049 "-2048~2045 (mm/s)" 3050 "-2048~2045 (mm/s)" 3051 "-2048~2045 (mm/s)" 3052 "-2048~2045 (mm/s)" 3053 "-2048~2045 (mm/s)" 3054 "-2048~2045 (mm/s)" 3055 "-2048~2045 (mm/s)" 3056 "-2048~2045 (mm/s)" 3057 "-2048~2045 (mm/s)" 3058 "-2048~2045 (mm/s)" 3059 "-2048~2045 (mm/s)" 3060 "-2048~2045 (mm/s)" 3061 "-2048~2045 (mm/s)" 3062 "-2048~2045 (mm/s)" 3063 "-2048~2045 (mm/s)" 3064 "-2048~2045 (mm/s)" 3065 "-2048~2045 (mm/s)" 3066 "-2048~2045 (mm/s)" 3067 "-2048~2045 (mm/s)" 3068 "-2048~2045 (mm/s)" 3069 "-2048~2045 (mm/s)" 3070 "-2048~2045 (mm/s)" 3071 "-2048~2045 (mm/s)" 3072 "-2048~2045 (mm/s)" 3073 "-2048~2045 (mm/s)" 3074 "-2048~2045 (mm/s)" 3075 "-2048~2045 (mm/s)" 3076 "-2048~2045 (mm/s)" 3077 "-2048~2045 (mm/s)" 3078 "-2048~2045 (mm/s)" 3079 "-2048~2045 (mm/s)" 3080 "-2048~2045 (mm/s)" 3081 "-2048~2045 (mm/s)" 3082 "-2048~2045 (mm/s)" 3083 "-2048~2045 (mm/s)" 3084 "-2048~2045 (mm/s)" 3085 "-2048~2045 (mm/s)" 3086 "-2048~2045 (mm/s)" 3087 "-2048~2045 (mm/s)" 3088 "-2048~2045 (mm/s)" 3089 "-2048~2045 (mm/s)" 3090 "-2048~2045 (mm/s)" 3091 "-2048~2045 (mm/s)" 3092 "-2048~2045 (mm/s)" 3093 "-2048~2045 (mm/s)" 3094 "-2048~2045 (mm/s)" 3095 "-2048~2045 (mm/s)" 3096 "-2048~2045 (mm/s)" 3097 "-2048~2045 (mm/s)" 3098 "-2048~2045 (mm/s)" 3099 "-2048~2045 (mm/s)" 3100 "-2048~2045 (mm/s)" 3101 "-2048~2045 (mm/s)" 3102 "-2048~2045 (mm/s)" 3103 "-2048~2045 (mm/s)" 3104 "-2048~2045 (mm/s)" 3105 "-2048~2045 (mm/s)" 3106 "-2048~2045 (mm/s)" 3107 "-2048~2045 (mm/s)" 3108 "-2048~2045 (mm/s)" 3109 "-2048~2045 (mm/s)" 3110 "-2048~2045 (mm/s)" 3111 "-2048~2045 (mm/s)" 3112 "-2048~2045 (mm/s)" 3113 "-2048~2045 (mm/s)" 3114 "-2048~2045 (mm/s)" 3115 "-2048~2045 (mm/s)" 3116 "-2048~2045 (mm/s)" 3117 "-2048~2045 (mm/s)" 3118 "-2048~2045 (mm/s)" 3119 "-2048~2045 (mm/s)" 3120 "-2048~2045 (mm/s)" 3121 "-2048~2045 (mm/s)" 3122 "-2048~2045 (mm/s)" 3123 "-2048~2045 (mm/s)" 3124 "-2048~2045 (mm/s)" 3125 "-2048~2045 (mm/s)" 3126 "-2048~2045 (mm/s)" 3127 "-2048~2045 (mm/s)" 3128 "-2048~2045 (mm/s)" 3129 "-2048~2045 (mm/s)" 3130 "-2048~2045 (mm/s)" 3131 "-2048~2045 (mm/s)" 3132 "-2048~2045 (mm/s)" 3133 "-2048~2045 (mm/s)" 3134 "-2048~2045 (mm/s)" 3135 "-2048~2045 (mm/s)" 3136 "-2048~2045 (mm/s)" 3137 "-2048~2045 (mm/s)" 3138 "-2048~2045 (mm/s)" 3139 "-2048~2045 (mm/s)" 3140 "-2048~2045 (mm/s)" 3141 "-2048~2045 (mm/s)" 3142 "-2048~2045 (mm/s)" 3143 "-2048~2045 (mm/s)" 3144 "-2048~2045 (mm/s)" 3145 "-2048~2045 (mm/s)" 3146 "-2048~2045 (mm/s)" 3147 "-2048~2045 (mm/s)" 3148 "-2048~2045 (mm/s)" 3149 "-2048~2045 (mm/s)" 3150 "-2048~2045 (mm/s)" 3151 "-2048~2045 (mm/s)" 3152 "-2048~2045 (mm/s)" 3153 "-2048~2045 (mm/s)" 3154 "-2048~2045 (mm/s)" 3155 "-2048~2045 (mm/s)" 3156 "-2048~2045 (mm/s)" 3157 "-2048~2045 (mm/s)" 3158 "-2048~2045 (mm/s)" 3159 "-2048~2045 (mm/s)" 3160 "-2048~2045 (mm/s)" 3161 "-2048~2045 (mm/s)" 3162 "-2048~2045 (mm/s)" 3163 "-2048~2045 (mm/s)" 3164 "-2048~2045 (mm/s)" 3165 "-2048~2045 (mm/s)" 3166 "-2048~2045 (mm/s)" 3167 "-2048~2045 (mm/s)" 3168 "-2048~2045 (mm/s)" 3169 "-2048~2045 (mm/s)" 3170 "-2048~2045 (mm/s)" 3171 "-2048~2045 (mm/s)" 3172 "-2048~2045 (mm/s)" 3173 "-2048~2045 (mm/s)" 3174 "-2048~2045 (mm/s)" 3175 "-2048~2045 (mm/s)" 3176 "-2048~2045 (mm/s)" 3177 "-2048~2045 (mm/s)" 3178 "-2048~2045 (mm/s)" 3179 "-2048~2045 (mm/s)" 3180 "-2048~2045 (mm/s)" 3181 "-2048~2045 (mm/s)" 3182 "-2048~2045 (mm/s)" 3183 "-2048~2045 (mm/s)" 3184 "-2048~2045 (mm/s)" 3185 "-2048~2045 (mm/s)" 3186 "-2048~2045 (mm/s)" 3187 "-2048~2045 (mm/s)" 3188 "-2048~2045 (mm/s)" 3189 "-2048~2045 (mm/s)" 3190 "-2048~2045 (mm/s)" 3191 "-2048~2045 (mm/s)" 3192 "-2048~2045 (mm/s)" 3193 "-2048~2045 (mm/s)" 3194 "-2048~2045 (mm/s)" 3195 "-2048~2045 (mm/s)" 3196 "-2048~2045 (mm/s)" 3197 "-2048~2045 (mm/s)" 3198 "-2048~2045 (mm/s)" 3199 "-2048~2045 (mm/s)" 3200 "-2048~2045 (mm/s)" 3201 "-2048~2045 (mm/s)" 3202 "-2048~2045 (mm/s)" 3203 "-2048~2045 (mm/s)" 3204 "-2048~2045 (mm/s)" 3205 "-2048~2045 (mm/s)" 3206 "-2048~2045 (mm/s)" 3207 "-2048~2045 (mm/s)" 3208 "-2048~2045 (mm/s)" 3209 "-2048~2045 (mm/s)" 3210 "-2048~2045 (mm/s)" 3211 "-2048~2045 (mm/s)" 3212 "-2048~2045 (mm/s)" 3213 "-2048~2045 (mm/s)" 3214 "-2048~2045 (mm/s)" 3215 "-2048~2045 (mm/s)" 3216 "-2048~2045 (mm/s)" 3217 "-2048~2045 (mm/s)" 3218 "-2048~2045 (mm/s)" 3219 "-2048~2045 (mm/s)" 3220 "-2048~2045 (mm/s)" 3221 "-2048~2045 (mm/s)" 3222 "-2048~2045 (mm/s)" 3223 "-2048~2045 (mm/s)" 3224 "-2048~2045 (mm/s)" 3225 "-2048~2045 (mm/s)" 3226 "-2048~2045 (mm/s)" 3227 "-2048~2045 (mm/s)" 3228 "-2048~2045 (mm/s)" 3229 "-2048~2045 (mm/s)" 3230 "-2048~2045 (mm/s)" 3231 "-2048~2045 (mm/s)" 3232 "-2048~2045 (mm/s)" 3233 "-2048~2045 (mm/s)" 3234 "-2048~2045 (mm/s)" 3235 "-2048~2045 (mm/s)" 3236 "-2048~2045 (mm/s)" 3237 "-2048~2045 (mm/s)" 3238 "-2048~2045 (mm/s)" 3239 "-2048~2045 (mm/s)" 3240 "-2048~2045 (mm/s)" 3241 "-2048~2045 (mm/s)" 3242 "-2048~2045 (mm/s)" 3243 "-2048~2045 (mm/s)" 3244 "-2048~2045 (mm/s)" 3245 "-2048~2045 (mm/s)" 3246 "-2048~2045 (mm/s)" 3247 "-2048~2045 (mm/s)" 3248 "-2048~2045 (mm/s)" 3249 "-2048~2045 (mm/s)" 3250 "-2048~2045 (mm/s)" 3251 "-2048~2045 (mm/s)" 3252 "-2048~2045 (mm/s)" 3253 "-2048~2045 (mm/s)" 3254 "-2048~2045 (mm/s)" 3255 "-2048~2045 (mm/s)" 3256 "-2048~2045 (mm/s)" 3257 "-2048~2045 (mm/s)" 3258 "-2048~2045 (mm/s)" 3259 "-2048~2045 (mm/s)" 3260 "-2048~2045 (mm/s)" 3261 "-2048~2045 (mm/s)" 3262 "-2048~2045 (mm/s)" 3263 "-2048~2045 (mm/s)" 3264 "-2048~2045 (mm/s)" 3265 "-2048~2045 (mm/s)" 3266 "-2048~2045 (mm/s)" 3267 "-2048~2045 (mm/s)" 3268 "-2048~2045 (mm/s)" 3269 "-2048~2045 (mm/s)" 3270 "-2048~2045 (mm/s)" 3271 "-2048~2045 (mm/s)" 3272 "-2048~2045 (mm/s)" 3273 "-2048~2045 (mm/s)" 3274 "-2048~2045 (mm/s)" 3275 "-2048~2045 (mm/s)" 3276 "-2048~2045 (mm/s)" 3277 "-2048~2045 (mm/s)" 3278 "-2048~2045 (mm/s)" 3279 "-2048~2045 (mm/s)" 3280 "-2048~2045 (mm/s)" 3281 "-2048~2045 (mm/s)" 3282 "-2048~2045 (mm/s)" 3283 "-2048~2045 (mm/s)" 3284 "-2048~2045 (mm/s)" 3285 "-2048~2045 (mm/s)" 3286 "-2048~2045 (mm/s)" 3287 "-2048~2045 (mm/s)" 3288 "-2048~2045 (mm/s)" 3289 "-2048~2045 (mm/s)" 3290 "-2048~2045 (mm/s)" 3291 "-2048~2045 (mm/s)" 3292 "-2048~2045 (mm/s)" 3293 "-2048~2045 (mm/s)" 3294 "-2048~2045 (mm/s)" 3295 "-2048~2045 (mm/s)" 3296 "-2048~2045 (mm/s)" 3297 "-2048~2045 (mm/s)" 3298 "-2048~2045 (mm/s)" 3299 "-2048~2045 (mm/s)" 3300 "-2048~2045 (mm/s)" 3301 "-2048~2045 (mm/s)" 3302 "-2048~2045 (mm/s)" 3303 "-2048~2045 (mm/s)" 3304 "-2048~2045 (mm/s)" 3305 "-2048~2045 (mm/s)" 3306 "-2048~2045 (mm/s)" 3307 "-2048~2045 (mm/s)" 3308 "-2048~2045 (mm/s)" 3309 "-2048~2045 (mm/s)" 3310 "-2048~2045 (mm/s)" 3311 "-2048~2045 (mm/s)" 3312 "-2048~2045 (mm/s)" 3313 "-2048~2045 (mm/s)" 3314 "-2048~2045 (mm/s)" 3315 "-2048~2045 (mm/s)" 3316 "-2048~2045 (mm/s)" 3317 "-2048~2045 (mm/s)" 3318 "-2048~2045 (mm/s)" 3319 "-2048~2045 (mm/s)" 3320 "-2048~2045 (mm/s)" 3321 "-2048~2045 (mm/s)" 3322 "-2048~2045 (mm/s)" 3323 "-2048~2045 (mm/s)" 3324 "-2048~2045 (mm/s)" 3325 "-2048~2045 (mm/s)" 3326 "-2048~2045 (mm/s)" 3327 "-2048~2045 (mm/s)" 3328 "-2048~2045 (mm/s)" 3329 "-2048~2045 (mm/s)" 3330 "-2048~2045 (mm/s)" 3331 "-2048~2045 (mm/s)" 3332 "-2048~2045 (mm/s)" 3333 "-2048~2045 (mm/s)" 3334 "-2048~2045 (mm/s)" 3335 "-2048~2045 (mm/s)" 3336 "-2048~2045 (mm/s)" 3337 "-2048~2045 (mm/s)" 3338 "-2048~2045 (mm/s)" 3339 "-2048~2045 (mm/s)" 3340 "-2048~2045 (mm/s)" 3341 "-2048~2045 (mm/s)" 3342 "-2048~2045 (mm/s)" 3343 "-2048~2045 (mm/s)" 3344 "-2048~2045 (mm/s)" 3345 "-2048~2045 (mm/s)" 3346 "-2048~2045 (mm/s)" 3347 "-2048~2045 (mm/s)" 3348 "-2048~2045 (mm/s)" 3349 "-2048~2045 (mm/s)" 3350 "-2048~2045 (mm/s)" 3351 "-2048~2045 (mm/s)" 3352 "-2048~2045 (mm/s)" 3353 "-2048~2045 (mm/s)" 3354 "-2048~2045 (mm/s)" 3355 "-2048~2045 (mm/s)" 3356 "-2048~2045 (mm/s)" 3357 "-2048~2045 (mm/s)" 3358 "-2048~2045 (mm/s)" 3359 "-2048~2045 (mm/s)" 3360 "-2048~2045 (mm/s)" 3361 "-2048~2045 (mm/s)" 3362 "-2048~2045 (mm/s)" 3363 "-2048~2045 (mm/s)" 3364 "-2048~2045 (mm/s)" 3365 "-2048~2045 (mm/s)" 3366 "-2048~2045 (mm/s)" 3367 "-2048~2045 (mm/s)" 3368 "-2048~2045 (mm/s)" 3369 "-2048~2045 (mm/s)" 3370 "-2048~2045 (mm/s)" 3371 "-2048~2045 (mm/s)" 3372 "-2048~2045 (mm/s)" 3373 "-2048~2045 (mm/s)" 3374 "-2048~2045 (mm/s)" 3375 "-2048~2045 (mm/s)" 3376 "-2048~2045 (mm/s)" 3377 "-2048~2045 (mm/s)" 3378 "-2048~2045 (mm/s)" 3379 "-2048~2045 (mm/s)" 3380 "-2048~2045 (mm/s)" 3381 "-2048~2045 (mm/s)" 3382 "-2048~2045 (mm/s)" 3383 "-2048~2045 (mm/s)" 3384 "-2048~2045 (mm/s)" 3385 "-2048~2045 (mm/s)" 3386 "-2048~2045 (mm/s)" 3387 "-2048~2045 (mm/s)" 3388 "-2048~2045 (mm/s)" 3389 "-2048~2045 (mm/s)" 3390 "-2048~2045 (mm/s)" 3391 "-2048~2045 (mm/s)" 3392 "-2048~2045 (mm/s)" 3393 "-2048~2045 (mm/s)" 3394 "-2048~2045 (mm/s)" 3395 "-2048~2045 (mm/s)" 3396 "-2048~2045 (mm/s)" 3397 "-2048~2045 (mm/s)" 3398 "-2048~2045 (mm/s)" 3399 "-2048~2045 (mm/s)" 3400 "-2048~2045 (mm/s)" 3401 "-2048~2045 (mm/s)" 3402 "-2048~2045 (mm/s)" 3403 "-2048~2045 (mm/s)" 3404 "-2048~2045 (mm/s)" 3405 "-2048~2045 (mm/s)" 3406 "-2048~2045 (mm/s)" 3407 "-2048~2045 (mm/s)" 3408 "-2048~2045 (mm/s)" 3409 "-2048~2045 (mm/s)" 3410 "-2048~2045 (mm/s)" 3411 "-2048~2045 (mm/s)" 3412 "-2048~2045 (mm/s)" 3413 "-2048~2045 (mm/s)" 3414 "-2048~2045 (mm/s)" 3415 "-2048~2045 (mm/s)" 3416 "-2048~2045 (mm/s)" 3417 "-2048~2045 (mm/s)" 3418 "-2048~2045 (mm/s)" 3419 "-2048~2045 (mm/s)" 3420 "-2048~2045 (mm/s)" 3421 "-2048~2045 (mm/s)" 3422 "-2048~2045 (mm/s)" 3423 "-2048~2045 (mm/s)" 3424 "-2048~2045 (mm/s)" 3425 "-2048~2045 (mm/s)" 3426 "-2048~2045 (mm/s)" 3427 "-2048~2045 (mm/s)" 3428 "-2048~2045 (mm/s)" 3429 "-2048~2045 (mm/s)" 3430 "-2048~2045 (mm/s)" 3431 "-2048~2045 (mm/s)" 3432 "-2048~2045 (mm/s)" 3433 "-2048~2045 (mm/s)" 3434 "-2048~2045 (mm/s)" 3435 "-2048~2045 (mm/s)" 3436 "-2048~2045 (mm/s)" 3437 "-2048~2045 (mm/s)" 3438 "-2048~2045 (mm/s)" 3439 "-2048~2045 (mm/s)" 3440 "-2048~2045 (mm/s)" 3441 "-2048~2045 (mm/s)" 3442 "-2048~2045 (mm/s)" 3443 "-2048~2045 (mm/s)" 3444 "-2048~2045 (mm/s)" 3445 "-2048~2045 (mm/s)" 3446 "-2048~2045 (mm/s)" 3447 "-2048~2045 (mm/s)" 3448 "-2048~2045 (mm/s)" 3449 "-2048~2045 (mm/s)" 3450 "-2048~2045 (mm/s)" 3451 "-2048~2045 (mm/s)" 3452 "-2048~2045 (mm/s)" 3453 "-2048~2045 (mm/s)" 3454 "-2048~2045 (mm/s)" 3455 "-2048~2045 (mm/s)" 3456 "-2048~2045 (mm/s)" 3457 "-2048~2045 (mm/s)" 3458 "-2048~2045 (mm/s)" 3459 "-2048~2045 (mm/s)" 3460 "-2048~2045 (mm/s)" 3461 "-2048~2045 (mm/s)" 3462 "-2048~2045 (mm/s)" 3463 "-2048~2045 (mm/s)" 3464 "-2048~2045 (mm/s)" 3465 "-2048~2045 (mm/s)" 3466 "-2048~2045 (mm/s)" 3467 "-2048~2045 (mm/s)" 3468 "-2048~2045 (mm/s)" 3469 "-2048~2045 (mm/s)" 3470 "-2048~2045 (mm/s)" 3471 "-2048~2045 (mm/s)" 3472 "-2048~2045 (mm/s)" 3473 "-2048~2045 (mm/s)" 3474 "-2048~2045 (mm/s)" 3475 "-2048~2045 (mm/s)" 3476 "-2048~2045 (mm/s)" 3477 "-2048~2045 (mm/s)" 3478 "-2048~2045 (mm/s)" 3479 "-2048~2045 (mm/s)" 3480 "-2048~2045 (mm/s)" 3481 "-2048~2045 (mm/s)" 3482 "-2048~2045 (mm/s)" 3483 "-2048~2045 (mm/s)" 3484 "-2048~2045 (mm/s)" 3485 "-2048~2045 (mm/s)" 3486 "-2048~2045 (mm/s)" 3487 "-2048~2045 (mm/s)" 3488 "-2048~2045 (mm/s)" 3489 "-2048~2045 (mm/s)" 3490 "-2048~2045 (mm/s)" 3491 "-2048~2045 (mm/s)" 3492 "-2048~2045 (mm/s)" 3493 "-2048~2045 (mm/s)" 3494 "-2048~2045 (mm/s)" 3495 "-2048~2045 (mm/s)" 3496 "-2048~2045 (mm/s)" 3497 "-2048~2045 (mm/s)" 3498 "-2048~2045 (mm/s)" 3499 "-2048~2045 (mm/s)" 3500 "-2048~2045 (mm/s)" 3501 "-2048~2045 (mm/s)" 3502 "-2048~2045 (mm/s)" 3503 "-2048~2045 (mm/s)" 3504 "-2048~2045 (mm/s)" 3505 "-2048~2045 (mm/s)" 3506 "-2048~2045 (mm/s)" 3507 "-2048~2045 (mm/s)" 3508 "-2048~2045 (mm/s)" 3509 "-2048~2045 (mm/s)" 3510 "-2048~2045 (mm/s)" 3511 "-2048~2045 (mm/s)" 3512 "-2048~2045 (mm/s)" 3513 "-2048~2045 (mm/s)" 3514 "-2048~2045 (mm/s)" 3515 "-2048~2045 (mm/s)" 3516 "-2048~2045 (mm/s)" 3517 "-2048~2045 (mm/s)" 3518 "-2048~2045 (mm/s)" 3519 "-2048~2045 (mm/s)" 3520 "-2048~2045 (mm/s)" 3521 "-2048~2045 (mm/s)" 3522 "-2048~2045 (mm/s)" 3523 "-2048~2045 (mm/s)" 3524 "-2048~2045 (mm/s)" 3525 "-2048~2045 (mm/s)" 3526 "-2048~2045 (mm/s)" 3527 "-2048~2045 (mm/s)" 3528 "-2048~2045 (mm/s)" 3529 "-2048~2045 (mm/s)" 3530 "-2048~2045 (mm/s)" 3531 "-2048~2045 (mm/s)" 3532 "-2048~2045 (mm/s)" 3533 "-2048~2045 (mm/s)" 3534 "-2048~2045 (mm/s)" 3535 "-2048~2045 (mm/s)" 3536 "-2048~2045 (mm/s)" 3537 "-2048~2045 (mm/s)" 3538 "-2048~2045 (mm/s)" 3539 "-2048~2045 (mm/s)" 3540 "-2048~2045 (mm/s)" 3541 "-2048~2045 (mm/s)" 3542 "-2048~2045 (mm/s)" 3543 "-2048~2045 (mm/s)" 3544 "-2048~2045 (mm/s)" 3545 "-2048~2045 (mm/s)" 3546 "-2048~2045 (mm/s)" 3547 "-2048~2045 (mm/s)" 3548 "-2048~2045 (mm/s)" 3549 "-2048~2045 (mm/s)" 3550 "-2048~2045 (mm/s)" 3551 "-2048~2045 (mm/s)" 3552 "-2048~2045 (mm/s)" 3553 "-2048~2045 (mm/s)" 3554 "-2048~2045 (mm/s)" 3555 "-2048~2045 (mm/s)" 3556 "-2048~2045 (mm/s)" 3557 "-2048~2045 (mm/s)" 3558 "-2048~2045 (mm/s)" 3559 "-2048~2045 (mm/s)" 3560 "-2048~2045 (mm/s)" 3561 "-2048~2045 (mm/s)" 3562 "-2048~2045 (mm/s)" 3563 "-2048~2045 (mm/s)" 3564 "-2048~2045 (mm/s)" 3565 "-2048~2045 (mm/s)" 3566 "-2048~2045 (mm/s)" 3567 "-2048~2045 (mm/s)" 3568 "-2048~2045 (mm/s)" 3569 "-2048~2045 (mm/s)" 3570 "-2048~2045 (mm/s)" 3571 "-2048~2045 (mm/s)" 3572 "-2048~2045 (mm/s)" 3573 "-2048~2045 (mm/s)" 3574 "-2048~2045 (mm/s)" 3575 "-2048~2045 (mm/s)" 3576 "-2048~2045 (mm/s)" 3577 "-2048~2045 (mm/s)" 3578 "-2048~2045 (mm/s)" 3579 "-2048~2045 (mm/s)" 3580 "-2048~2045 (mm/s)" 3581 "-2048~2045 (mm/s)" 3582 "-2048~2045 (mm/s)" 3583 "-2048~2045 (mm/s)" 3584 "-2048~2045 (mm/s)" 3585 "-2048~2045 (mm/s)" 3586 "-2048~2045 (mm/s)" 3587 "-2048~2045 (mm/s)" 3588 "-2048~2045 (mm/s)" 3589 "-2048~2045 (mm/s)" 3590 "-2048~2045 (mm/s)" 3591 "-2048~2045 (mm/s)" 3592 "-2048~2045 (mm/s)" 3593 "-2048~2045 (mm/s)" 3594 "-2048~2045 (mm/s)" 3595 "-2048~2045 (mm/s)" 3596 "-2048~2045 (mm/s)" 3597 "-2048~2045 (mm/s)" 3598 "-2048~2045 (mm/s)" 3599 "-2048~2045 (mm/s)" 3600 "-2048~2045 (mm/s)" 3601 "-2048~2045 (mm/s)" 3602 "-2048~2045 (mm/s)" 3603 "-2048~2045 (mm/s)" 3604 "-2048~2045 (mm/s)" 3605 "-2048~2045 (mm/s)" 3606 "-2048~2045 (mm/s)" 3607 "-2048~2045 (mm/s)" 3608 "-2048~2045 (mm/s)" 3609 "-2048~2045 (mm/s)" 3610 "-2048~2045 (mm/s)" 3611 "-2048~2045 (mm/s)" 3612 "-2048~2045 (mm/s)" 3613 "-2048~2045 (mm/s)" 3614 "-2048~2045 (mm/s)" 3615 "-2048~2045 (mm/s)" 3616 "-2048~2045 (mm/s)" 3617 "-2048~2045 (mm/s)" 3618 "-2048~2045 (mm/s)" 3619 "-2048~2045 (mm/s)" 3620 "-2048~2045 (mm/s)" 3621 "-2048~2045 (mm/s)" 3622 "-2048~2045 (mm/s)" 3623 "-2048~2045 (mm/s)" 3624 "-2048~2045 (mm/s)" 3625 "-2048~2045 (mm/s)" 3626 "-2048~2045 (mm/s)" 3627 "-2048~2045 (mm/s)" 3628 "-2048~2045 (mm/s)" 3629 "-2048~2045 (mm/s)" 3630 "-2048~2045 (mm/s)" 3631 "-2048~2045 (mm/s)" 3632 "-2048~2045 (mm/s)" 3633 "-2048~2045 (mm/s)" 3634 "-2048~2045 (mm/s)" 3635 "-2048~2045 (mm/s)" 3636 "-2048~2045 (mm/s)" 3637 "-2048~2045 (mm/s)" 3638 "-2048~2045 (mm/s)" 3639 "-2048~2045 (mm/s)" 3640 "-2048~2045 (mm/s)" 3641 "-2048~2045 (mm/s)" 3642 "-2048~2045 (mm/s)" 3643 "-2048~2045 (mm/s)" 3644 "-2048~2045 (mm/s)" 3645 "-2048~2045 (mm/s)" 3646 "-2048~2045 (mm/s)" 3647 "-2048~2045 (mm/s)" 3648 "-2048~2045 (mm/s)" 3649 "-2048~2045 (mm/s)" 3650 "-2048~2045 (mm/s)" 3651 "-2048~2045 (mm/s)" 3652 "-2048~2045 (mm/s)" 3653 "-2048~2045 (mm/s)" 3654 "-2048~2045 (mm/s)" 3655 "-2048~2045 (mm/s)" 3656 "-2048~2045 (mm/s)" 3657 "-2048~2045 (mm/s)" 3658 "-2048~2045 (mm/s)" 3659 "-2048~2045 (mm/s)" 3660 "-2048~2045 (mm/s)" 3661 "-2048~2045 (mm/s)" 3662 "-2048~2045 (mm/s)" 3663 "-2048~2045 (mm/s)" 3664 "-2048~2045 (mm/s)" 3665 "-2048~2045 (mm/s)" 3666 "-2048~2045 (mm/s)" 3667 "-2048~2045 (mm/s)" 3668 "-2048~2045 (mm/s)" 3669 "-2048~2045 (mm/s)" 3670 "-2048~2045 (mm/s)" 3671 "-2048~2045 (mm/s)" 3672 "-2048~2045 (mm/s)" 3673 "-2048~2045 (mm/s)" 3674 "-2048~2045 (mm/s)" 3675 "-2048~2045 (mm/s)" 3676 "-2048~2045 (mm/s)" 3677 "-2048~2045 (mm/s)" 3678 "-2048~2045 (mm/s)" 3679 "-2048~2045 (mm/s)" 3680 "-2048~2045 (mm/s)" 3681 "-2048~2045 (mm/s)" 3682 "-2048~2045 (mm/s)" 3683 "-2048~2045 (mm/s)" 3684 "-2048~2045 (mm/s)" 3685 "-2048~2045 (mm/s)" 3686 "-2048~2045 (mm/s)" 3687 "-2048~2045 (mm/s)" 3688 "-2048~2045 (mm/s)" 3689 "-2048~2045 (mm/s)" 3690 "-2048~2045 (mm/s)" 3691 "-2048~2045 (mm/s)" 3692 "-2048~2045 (mm/s)" 3693 "-2048~2045 (mm/s)" 3694 "-2048~2045 (mm/s)" 3695 "-2048~2045 (mm/s)" 3696 "-2048~2045 (mm/s)" 3697 "-2048~2045 (mm/s)" 3698 "-2048~2045 (mm/s)" 3699 "-2048~2045 (mm/s)" 3700 "-2048~2045 (mm/s)" 3701 "-2048~2045 (mm/s)" 3702 "-2048~2045 (mm/s)" 3703 "-2048~2045 (mm/s)" 3704 "-2048~2045 (mm/s)" 3705 "-2048~2045 (mm/s)" 3706 "-2048~2045 (mm/s)" 3707 "-2048~2045 (mm/s)" 3708 "-2048~2045 (mm/s)" 3709 "-2048~2045 (mm/s)" 3710 "-2048~2045 (mm/s)" 3711 "-2048~2045 (mm/s)" 3712 "-2048~2045 (mm/s)" 3713 "-2048~2045 (mm/s)" 3714 "-2048~2045 (mm/s)" 3715 "-2048~2045 (mm/s)" 3716 "-2048~2045 (mm/s)" 3717 "-2048~2045 (mm/s)" 3718 "-2048~2045 (mm/s)" 3719 "-2048~2045 (mm/s)" 3720 "-2048~2045 (mm/s)" 3721 "-2048~2045 (mm/s)" 3722 "-2048~2045 (mm/s)" 3723 "-2048~2045 (mm/s)" 3724 "-2048~2045 (mm/s)" 3725 "-2048~2045 (mm/s)" 3726 "-2048~2045 (mm/s)" 3727 "-2048~2045 (mm/s)" 3728 "-2048~2045 (mm/s)" 3729 "-2048~2045 (mm/s)" 3730 "-2048~2045 (mm/s)" 3731 "-2048~2045 (mm/s)" 3732 "-2048~2045 (mm/s)" 3733 "-2048~2045 (mm/s)" 3734 "-2048~2045 (mm/s)" 3735 "-2048~2045 (mm/s)" 3736 "-2048~2045 (mm/s)" 3737 "-2048~2045 (mm/s)" 3738 "-2048~2045 (mm/s)" 3739 "-2048~2045 (mm/s)" 3740 "-2048~2045 (mm/s)" 3741 "-2048~2045 (mm/s)" 3742 "-2048~2045 (mm/s)" 3743 "-2048~2045 (mm/s)" 3744 "-2048~2045 (mm/s)" 3745 "-2048~2045 (mm/s)" 3746 "-2048~2045 (mm/s)" 3747 "-2048~2045 (mm/s)" 3748 "-2048~2045 (mm/s)" 3749 "-2048~2045 (mm/s)" 3750 "-2048~2045 (mm/s)" 3751 "-2048~2045 (mm/s)" 3752 "-2048~2045 (mm/s)" 3753 "-2048~2045 (mm/s)" 3754 "-2048~2045 (mm/s)" 3755 "-2048~2045 (mm/s)" 3756 "-2048~2045 (mm/s)" 3757 "-2048~2045 (mm/s)" 3758 "-2048~2045 (mm/s)" 3759 "-2048~2045 (mm/s)" 3760 "-2048~2045 (mm/s)" 3761 "-2048~2045 (mm/s)" 3762 "-2048~2045 (mm/s)" 3763 "-2048~2045 (mm/s)" 3764 "-2048~2045 (mm/s)" 3765 "-2048~2045 (mm/s)" 3766 "-2048~2045 (mm/s)" 3767 "-2048~2045 (mm/s)" 3768 "-2048~2045 (mm/s)" 3769 "-2048~2045 (mm/s)" 3770 "-2048~2045 (mm/s)" 3771 "-2048~2045 (mm/s)" 3772 "-2048~2045 (mm/s)" 3773 "-2048~2045 (mm/s)" 3774 "-2048~2045 (mm/s)" 3775 "-2048~2045 (mm/s)" 3776 "-2048~2045 (mm/s)" 3777 "-2048~2045 (mm/s)" 3778 "-2048~2045 (mm/s)" 3779 "-2048~2045 (mm/s)" 3780 "-2048~2045 (mm/s)" 3781 "-2048~2045 (mm/s)" 3782 "-2048~2045 (mm/s)" 3783 "-2048~2045 (mm/s)" 3784 "-2048~2045 (mm/s)" 3785 "-2048~2045 (mm/s)" 3786 "-2048~2045 (mm/s)" 3787 "-2048~2045 (mm/s)" 3788 "-2048~2045 (mm/s)" 3789 "-2048~2045 (mm/s)" 3790 "-2048~2045 (mm/s)" 3791 "-2048~2045 (mm/s)" 3792 "-2048~2045 (mm/s)" 3793 "-2048~2045 (mm/s)" 3794 "-2048~2045 (mm/s)" 3795 "-2048~2045 (mm/s)" 3796 "-2048~2045 (mm/s)" 3797 "-2048~2045 (mm/s)" 3798 "-2048~2045 (mm/s)" 3799 "-2048~2045 (mm/s)" 3800 "-2048~2045 (mm/s)" 3801 "-2048~2045 (mm/s)" 3802 "-2048~2045 (mm/s)" 3803 "-2048~2045 (mm/s)" 3804 "-2048~2045 (mm/s)" 3805 "-2048~2045 (mm/s)" 3806 "-2048~2045 (mm/s)" 3807 "-2048~2045 (mm/s)" 3808 "-2048~2045 (mm/s)" 3809 "-2048~2045 (mm/s)" 3810 "-2048~2045 (mm/s)" 3811 "-2048~2045 (mm/s)" 3812 "-2048~2045 (mm/s)" 3813 "-2048~2045 (mm/s)" 3814 "-2048~2045 (mm/s)" 3815 "-2048~2045 (mm/s)" 3816 "-2048~2045 (mm/s)" 3817 "-2048~2045 (mm/s)" 3818 "-2048~2045 (mm/s)" 3819 "-2048~2045 (mm/s)" 3820 "-2048~2045 (mm/s)" 3821 "-2048~2045 (mm/s)" 3822 "-2048~2045 (mm/s)" 3823 "-2048~2045 (mm/s)" 3824 "-2048~2045 (mm/s)" 3825 "-2048~2045 (mm/s)" 3826 "-2048~2045 (mm/s)" 3827 "-2048~2045 (mm/s)" 3828 "-2048~2045 (mm/s)" 3829 "-2048~2045 (mm/s)" 3830 "-2048~2045 (mm/s)" 3831 "-2048~2045 (mm/s)" 3832 "-2048~2045 (mm/s)" 3833 "-2048~2045 (mm/s)" 3834 "-2048~2045 (mm/s)" 3835 "-2048~2045 (mm/s)" 3836 "-2048~2045 (mm/s)" 3837 "-2048~2045 (mm/s)" 3838 "-2048~2045 (mm/s)" 3839 "-2048~2045 (mm/s)" 3840 "-2048~2045 (mm/s)" 3841 "-2048~2045 (mm/s)" 3842 "-2048~2045 (mm/s)" 3843 "-2048~2045 (mm/s)" 3844 "-2048~2045 (mm/s)" 3845 "-2048~2045 (mm/s)" 3846 "-2048~2045 (mm/s)" 3847 "-2048~2045 (mm/s)" 3848 "-2048~2045 (mm/s)" 3849 "-2048~2045 (mm/s)" 3850 "-2048~2045 (mm/s)" 3851 "-2048~2045 (mm/s)" 3852 "-2048~2045 (mm/s)" 3853 "-2048~2045 (mm/s)" 3854 "-2048~2045 (mm/s)" 3855 "-2048~2045 (mm/s)" 3856 "-2048~2045 (mm/s)" 3857 "-2048~2045 (mm/s)" 3858 "-2048~2045 (mm/s)" 3859 "-2048~2045 (mm/s)" 3860 "-2048~2045 (mm/s)" 3861 "-2048~2045 (mm/s)" 3862 "-2048~2045 (mm/s)" 3863 "-2048~2045 (mm/s)" 3864 "-2048~2045 (mm/s)" 3865 "-2048~2045 (mm/s)" 3866 "-2048~2045 (mm/s)" 3867 "-2048~2045 (mm/s)" 3868 "-2048~2045 (mm/s)" 3869 "-2048~2045 (mm/s)" 3870 "-2048~2045 (mm/s)" 3871 "-2048~2045 (mm/s)" 3872 "-2048~2045 (mm/s)" 3873 "-2048~2045 (mm/s)" 3874 "-2048~2045 (mm/s)" 3875 "-2048~2045 (mm/s)" 3876 "-2048~2045 (mm/s)" 3877 "-2048~2045 (mm/s)" 3878 "-2048~2045 (mm/s)" 3879 "-2048~2045 (mm/s)" 3880 "-2048~2045 (mm/s)" 3881 "-2048~2045 (mm/s)" 3882 "-2048~2045 (mm/s)" 3883 "-2048~2045 (mm/s)" 3884 "-2048~2045 (mm/s)" 3885 "-2048~2045 (mm/s)" 3886 "-2048~2045 (mm/s)" 3887 "-2048~2045 (mm/s)" 3888 "-2048~2045 (mm/s)" 3889 "-2048~2045 (mm/s)" 3890 "-2048~2045 (mm/s)" 3891 "-2048~2045 (mm/s)" 3892 "-2048~2045 (mm/s)" 3893 "-2048~2045 (mm/s)" 3894 "-2048~2045 (mm/s)" 3895 "-2048~2045 (mm/s)" 3896 "-2048~2045 (mm/s)" 3897 "-2048~2045 (mm/s)" 3898 "-2048~2045 (mm/s)" 3899 "-2048~2045 (mm/s)" 3900 "-2048~2045 (mm/s)" 3901 "-2048~2045 (mm/s)" 3902 "-2048~2045 (mm/s)" 3903 "-2048~2045 (mm/s)" 3904 "-2048~2045 (mm/s)" 3905 "-2048~2045 (mm/s)" 3906 "-2048~2045 (mm/s)" 3907 "-2048~2045 (mm/s)" 3908 "-2048~2045 (mm/s)" 3909 "-2048~2045 (mm/s)" 3910 "-2048~2045 (mm/s)" 3911 "-2048~2045 (mm/s)" 3912 "-2048~2045 (mm/s)" 3913 "-2048~2045 (mm/s)" 3914 "-2048~2045 (mm/s)" 3915 "-2048~2045 (mm/s)" 3916 "-2048~2045 (mm/s)" 3917 "-2048~2045 (mm/s)" 3918 "-2048~2045 (mm/s)" 3919 "-2048~2045 (mm/s)" 3920 "-2048~2045 (mm/s)" 3921 "-2048~2045 (mm/s)" 3922 "-2048~2045 (mm/s)" 3923 "-2048~2045 (mm/s)" 3924 "-2048~2045 (mm/s)" 3925 "-2048~2045 (mm/s)" 3926 "-2048~2045 (mm/s)" 3927 "-2048~2045 (mm/s)" 3928 "-2048~2045 (mm/s)" 3929 "-2048~2045 (mm/s)" 3930 "-2048~2045 (mm/s)" 3931 "-2048~2045 (mm/s)" 3932 "-2048~2045 (mm/s)" 3933 "-2048~2045 (mm/s)" 3934 "-2048~2045 (mm/s)" 3935 "-2048~2045 (mm/s)" 3936 "-2048~2045 (mm/s)" 3937 "-2048~2045 (mm/s)" 3938 "-2048~2045 (mm/s)" 3939 "-2048~2045 (mm/s)" 3940 "-2048~2045 (mm/s)" 3941 "-2048~2045 (mm/s)" 3942 "-2048~2045 (mm/s)" 3943 "-2048~2045 (mm/s)" 3944 "-2048~2045 (mm/s)" 3945 "-2048~2045 (mm/s)" 3946 "-2048~2045 (mm/s)" 3947 "-2048~2045 (mm/s)" 3948 "-2048~2045 (mm/s)" 3949 "-2048~2045 (mm/s)" 3950 "-2048~2045 (mm/s)" 3951 "-2048~2045 (mm/s)" 3952 "-2048~2045 (mm/s)" 3953 "-2048~2045 (mm/s)" 3954 "-2048~2045 (mm/s)" 3955 "-2048~2045 (mm/s)" 3956 "-2048~2045 (mm/s)" 3957 "-2048~2045 (mm/s)" 3958 "-2048~2045 (mm/s)" 3959 "-2048~2045 (mm/s)" 3960 "-2048~2045 (mm/s)" 3961 "-2048~2045 (mm/s)" 3962 "-2048~2045 (mm/s)" 3963 "-2048~2045 (mm/s)" 3964 "-2048~2045 (mm/s)" 3965 "-2048~2045 (mm/s)" 3966 "-2048~2045 (mm/s)" 3967 "-2048~2045 (mm/s)" 3968 "-2048~2045 (mm/s)" 3969 "-2048~2045 (mm/s)" 3970 "-2048~2045 (mm/s)" 3971 "-2048~2045 (mm/s)" 3972 "-2048~2045 (mm/s)" 3973 "-2048~2045 (mm/s)" 3974 "-2048~2045 (mm/s)" 3975 "-2048~2045 (mm/s)" 3976 "-2048~2045 (mm/s)" 3977 "-2048~2045 (mm/s)" 3978 "-2048~2045 (mm/s)" 3979 "-2048~2045 (mm/s)" 3980 "-2048~2045 (mm/s)" 3981 "-2048~2045 (mm/s)" 3982 "-2048~2045 (mm/s)" 3983 "-2048~2045 (mm/s)" 3984 "-2048~2045 (mm/s)" 3985 "-2048~2045 (mm/s)" 3986 "-2048~2045 (mm/s)" 3987 "-2048~2045 (mm/s)" 3988 "-2048~2045 (mm/s)" 3989 "-2048~2045 (mm/s)" 3990 "-2048~2045 (mm/s)" 3991 "-2048~2045 (mm/s)" 3992 "-2048~2045 (mm/s)" 3993 "-2048~2045 (mm/s)" 3994 "-2048~2045 (mm/s)" 3995 "-2048~2045 (mm/s)" 3996 "-2048~2045 (mm/s)" 3997 "-2048~2045 (mm/s)" 3998 "-2048~2045 (mm/s)" 3999 "-2048~2045 (mm/s)" 4000 "-2048~2045 (mm/s)" 4001 "-2048~2045 (mm/s)" 4002 "-2048~2045 (mm/s)" 4003 "-2048~2045 (mm/s)" 4004 "-2048~2045 (mm/s)" 4005 "-2048~2045 (mm/s)" 4006 "-2048~2045 (mm/s)" 4007 "-2048~2045 (mm/s)" 4008 "-2048~2045 (mm/s)" 4009 "-2048~2045 (mm/s)" 4010 "-2048~2045 (mm/s)" 4011 "-2048~2045 (mm/s)" 4012 "-2048~2045 (mm/s)" 4013 "-2048~2045 (mm/s)" 4014 "-2048~2045 (mm/s)" 4015 "-2048~2045 (mm/s)" 4016 "-2048~2045 (mm/s)" 4017 "-2048~2045 (mm/s)" 4018 "-2048~2045 (mm/s)" 4019 "-2048~2045 (mm/s)" 4020 "-2048~2045 (mm/s)" 4021 "-2048~2045 (mm/s)" 4022 "-2048~2045 (mm/s)" 4023 "-2048~2045 (mm/s)" 4024 "-2048~2045 (mm/s)" 4025 "-2048~2045 (mm/s)" 4026 "-2048~2045 (mm/s)" 4027 "-2048~2045 (mm/s)" 4028 "-2048~2045 (mm/s)" 4029 "-2048~2045 (mm/s)" 4030 "-2048~2045 (mm/s)" 4031 "-2048~2045 (mm/s)" 4032 "-2048~2045 (mm/s)" 4033 "-2048~2045 (mm/s)" 4034 "-2048~2045 (mm/s)" 4035 "-2048~2045 (mm/s)" 4036 "-2048~2045 (mm/s)" 4037 "-2048~2045 (mm/s)" 4038 "-2048~2045 (mm/s)" 4039 "-2048~2045 (mm/s)" 4040 "-2048~2045 (mm/s)" 4041 "-2048~2045 (mm/s)" 4042 "-2048~2045 (mm/s)" 4043 "-2048~2045 (mm/s)" 4044 "-2048~2045 (mm/s)" 4045 "-2048~2045 (mm/s)" 4046 "-2048~2045 (mm/s)" 4047 "-2048~2045 (mm/s)" 4048 "-2048~2045 (mm/s)" 4049 "-2048~2045 (mm/s)" 4050 "-2048~2045 (mm/s)" 4051 "-2048~2045 (mm/s)" 4052 "-2048~2045 (mm/s)" 4053 "-2048~2045 (mm/s)" 4054 "-2048~2045 (mm/s)" 4055 "-2048~2045 (mm/s)" 4056 "-2048~2045 (mm/s)" 4057 "-2048~2045 (mm/s)" 4058 "-2048~2045 (mm/s)" 4059 "-2048~2045 (mm/s)" 4060 "-2048~2045 (mm/s)" 4061 "-2048~2045 (mm/s)" 4062 "-2048~2045 (mm/s)" 4063 "-2048~2045 (mm/s)" 4064 "-2048~2045 (mm/s)" 4065 "-2048~2045 (mm/s)" 4066 "-2048~2045 (mm/s)" 4067 "-2048~2045 (mm/s)" 4068 "-2048~2045 (mm/s)" 4069 "-2048~2045 (mm/s)" 4070 "-2048~2045 (mm/s)" 4071 "-2048~2045 (mm/s)" 4072 "-2048~2045 (mm/s)" 4073 "-2048~2045 (mm/s)" 4074 "-2048~2045 (mm/s)" 4075 "-2048~2045 (mm/s)" 4076 "-2048~2045 (mm/s)" 4077 "-2048~2045 (mm/s)" 4078 "-2048~2045 (mm/s)" 4079 "-2048~2045 (mm/s)" 4080 "-2048~2045 (mm/s)" 4081 "-2048~2045 (mm/s)" 4082 "-2048~2045 (mm/s)" 4083 "-2048~2045 (mm/s)" 4084 "-2048~2045 (mm/s)" 4085 "-2048~2045 (mm/s)" 4086 "-2048~2045 (mm/s)" 4087 "-2048~2045 (mm/s)" 4088 "-2048~2045 (mm/s)" 4089 "-2048~2045 (mm/s)" 4090 "-2048~2045 (mm/s)" 4091 "-2048~2045 (mm/s)" 4092 "-2048~2045 (mm/s)" 4093 "-2048~2045 (mm/s)" 4094 "Not used" 4095 "Invalid" ;
